VERSION ""

NS_ :

BS_:

BU_: VDCU_V CDCU VDR_TBOX ADCU VIU_B VIU_C VDCU_M EPB EPS_M EPS_S EBS FCS CMS_R CMS_B ECAS EGSM MTCU

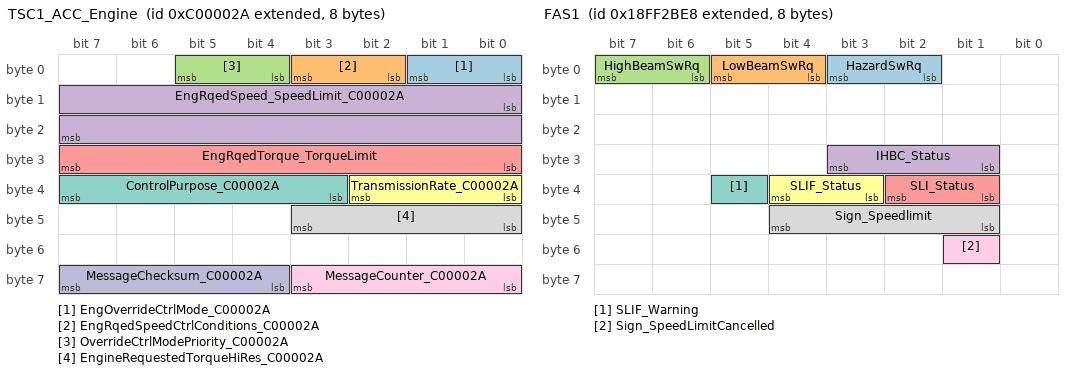
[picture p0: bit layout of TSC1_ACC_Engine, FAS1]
BO_ 2348810282 TSC1_ACC_Engine: 8 ADCU
 SG_ EngOverrideCtrlMode_C00002A : 0|2@1+ (1,0) [0|3] "" VDCU_V
 SG_ EngRqedSpeedCtrlConditions_C00002A : 2|2@1+ (1,0) [0|3] "" VDCU_V
 SG_ OverrideCtrlModePriority_C00002A : 4|2@1+ (1,0) [0|3] "" VDCU_V
 SG_ EngRqedSpeed_SpeedLimit_C00002A : 8|16@1+ (0.125,0) [0|8031.875] "rpm" VDCU_V
 SG_ EngRqedTorque_TorqueLimit : 24|8@1+ (1,-125) [-125|125] "%" VDCU_V
 SG_ TransmissionRate_C00002A : 32|3@1+ (1,0) [0|7] "" VDCU_V
 SG_ ControlPurpose_C00002A : 35|5@1+ (1,0) [0|31] "" VDCU_V
 SG_ EngineRequestedTorqueHiRes_C00002A : 40|4@1+ (0.125,0) [0|0.875] "%" VDCU_V
 SG_ MessageCounter_C00002A : 56|4@1+ (1,0) [0|15] "" VDCU_V
 SG_ MessageChecksum_C00002A : 60|4@1+ (1,0) [0|15] "" VDCU_V

BO_ 2349465642 CCVS2_ACC: 8 ADCU
 SG_ CruiseControlPauseCommand : 4|2@1+ (1,0) [0|3] "" VDCU_V

BO_ 2566859752 FAS1: 8 FCS
 SG_ HazardSwRq : 2|2@1+ (1,0) [0|3] "" VDCU_V
 SG_ LowBeamSwRq : 4|2@1+ (1,0) [0|3] "" VDCU_V
 SG_ HighBeamSwRq : 6|2@1+ (1,0) [0|3] "" VDCU_V
 SG_ IHBC_Status : 25|3@1+ (1,0) [0|7] "" VDCU_V
 SG_ SLI_Status : 33|2@1+ (1,0) [0|3] "" VDCU_V
 SG_ SLIF_Status : 35|2@1+ (1,0) [0|3] "" VDCU_V
 SG_ SLIF_Warning : 37|1@1+ (1,0) [0|1] "" VDCU_V
 SG_ Sign_Speedlimit : 41|4@1+ (1,0) [0|15] "" VDCU_V
 SG_ Sign_SpeedLimitCancelled : 49|1@1+ (1,0) [0|1] "" VDCU_V

BO_ 2565865808 EBC1_EPB: 8 EPB
 SG_ HaltBrakeSwitchEPB : 58|2@1+ (1,0) [0|3] "" VDCU_V

BO_ 2566787664 EPBS1_EPB: 8 EPB
 SG_ EPB_ParkBraStatus : 0|2@1+ (1,0) [0|3] "" VDCU_V
 SG_ AH_ParkActive : 2|2@1+ (1,0) [0|3] "" VDCU_V
 SG_ AH_BraStatus : 4|2@1+ (1,0) [0|3] "" VDCU_V
 SG_ EPB_WorkMode : 6|2@1+ (1,0) [0|3] "" VDCU_V
 SG_ ErrCode : 8|8@1+ (1,0) [0|255] "" VDCU_V
 SG_ ChildLockActive : 16|2@1+ (1,0) [0|3] "" VDCU_V
 SG_ LowPreRelParkLimit : 18|2@1+ (1,0) [0|3] "" VDCU_V
 SG_ TrailerCnctChck : 20|2@1+ (1,0) [0|3] "" VDCU_V
 SG_ ResponsePriority : 22|2@1+ (1,0) [0|3] "" VDCU_V
 SG_ IdepedtBraOly : 24|2@1+ (1,0) [0|3] "" VDCU_V
 SG_ PrakBraForcTest : 26|2@1+ (1,0) [0|3] "" VDCU_V
 SG_ DriveHillStatus : 28|2@1+ (1,0) [0|3] "" VDCU_V
 SG_ EPB_BraSwitch : 30|2@1+ (1,0) [0|3] "" VDCU_V
 SG_ ParkBtSwitch : 32|2@1+ (1,0) [0|3] "" VDCU_V
 SG_ RelsBtSwitch : 34|2@1+ (1,0) [0|3] "" VDCU_V
 SG_ AHBtSwitch : 36|2@1+ (1,0) [0|3] "" VDCU_V
 SG_ IdepedtBtSwitch : 38|2@1+ (1,0) [0|3] "" VDCU_V
 SG_ ForcTestBtSwitch : 40|2@1+ (1,0) [0|3] "" VDCU_V
 SG_ SysStatus : 42|2@1+ (1,0) [0|3] "" VDCU_V
 SG_ WarmingStatus : 44|2@1+ (1,0) [0|3] "" VDCU_V
 SG_ RollerTestBenchMode : 46|1@1+ (1,0) [0|1] "" VDCU_V
 SG_ ParkBraPres : 48|8@1+ (4.9,-122.5) [-122.5|1102.5] "Kpa" VDCU_V
 SG_ PTposition : 56|8@1+ (1,-125) [-125|125] "%" VDCU_V

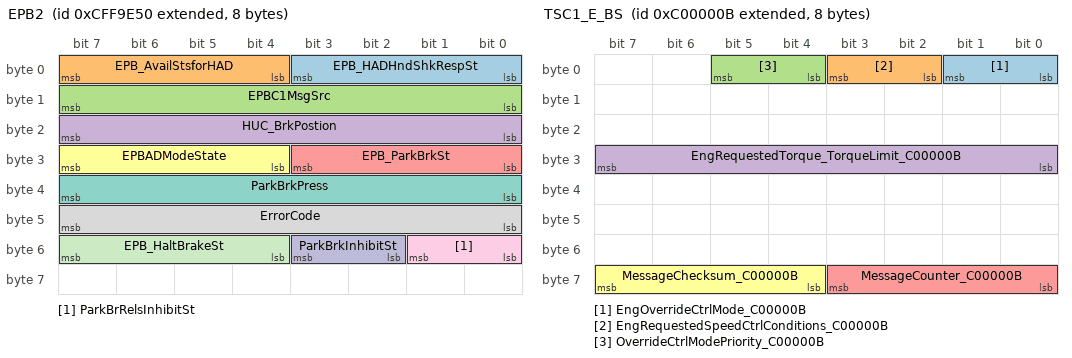
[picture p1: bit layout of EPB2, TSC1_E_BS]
BO_ 2365562448 EPB2: 8 EPB
 SG_ EPB_HADHndShkRespSt : 0|4@1+ (1,0) [0|15] "" VDCU_V
 SG_ EPB_AvailStsforHAD : 4|4@1+ (1,0) [0|15] "" VDCU_V
 SG_ EPBC1MsgSrc : 8|8@1+ (1,0) [0|255] "" VDCU_V
 SG_ HUC_BrkPostion : 16|8@1+ (1,0) [0|255] "" VDCU_V
 SG_ EPB_ParkBrkSt : 24|4@1+ (1,0) [0|16] "" VDCU_V
 SG_ EPBADModeState : 28|4@1+ (1,0) [0|15] "" VDCU_V
 SG_ ParkBrkPress : 32|8@1+ (4,0) [0|255] "" VDCU_V
 SG_ ErrorCode : 40|8@1+ (1,0) [0|255] "" VDCU_V
 SG_ ParkBrRelsInhibitSt : 48|2@1+ (1,0) [0|3] "" VDCU_V
 SG_ ParkBrkInhibitSt : 50|2@1+ (1,0) [0|3] "" VDCU_V
 SG_ EPB_HaltBrakeSt : 52|4@1+ (1,0) [0|15] "" VDCU_V

BO_ 2566847056 B1_EPB: 8 EPB
 SG_ BrakeAppPress : 0|8@1+ (4,0) [0|1000] "Kpa" VDCU_V

BO_ 2566911764 PropB_F7_S: 8 EPS_S
 SG_ DriverInterventionStatus_S : 0|3@1+ (1,1) [1|7] "0" VDCU_V

BO_ 2566897256 WPTC1: 8 VDCU_V
 SG_ WPTC1_InletTemp : 0|8@1+ (1,-40) [-40|210] "℃" Vector__XXX
 SG_ WPTC1_OutletTemp : 8|8@1+ (1,-40) [-40|210] "℃" Vector__XXX
 SG_ WPTC1_CtrlSysTemp : 16|8@1+ (1,-40) [-40|210] "℃" Vector__XXX
 SG_ WPTC1_HVVoltage : 24|8@1+ (5,0) [0|1000] "V" Vector__XXX
 SG_ WPTC1_HeaterPower : 32|8@1+ (100,0) [0|25500] "W" VDR_TBOX
 SG_ WPTC1_WorkingSts : 40|1@1+ (1,0) [0|1] "" Vector__XXX
 SG_ WPTC1_FaultLevel : 41|2@1+ (1,0) [0|3] "" Vector__XXX
 SG_ WPTC1_HVOverVoltage : 43|1@1+ (1,0) [0|1] "" Vector__XXX
 SG_ WPTC1_HVUnderVoltage : 44|1@1+ (1,0) [0|1] "" Vector__XXX
 SG_ WPTC1_LVOverVoltage : 45|1@1+ (1,0) [0|1] "" Vector__XXX
 SG_ WPTC1_LVUnderVoltage : 46|1@1+ (1,0) [0|1] "" Vector__XXX
 SG_ WPTC1_OpenCircuit : 47|1@1+ (1,0) [0|1] "" Vector__XXX
 SG_ WPTC1_OutletOverheating : 48|1@1+ (1,0) [0|1] "" Vector__XXX
 SG_ WPTC1_IGBTOverheating : 49|1@1+ (1,0) [0|1] "" Vector__XXX
 SG_ WPTC1_ComLoss : 50|1@1+ (1,0) [0|1] "" Vector__XXX
 SG_ WPTC1_IGBTShortCircuit : 51|1@1+ (1,0) [0|1] "" Vector__XXX
 SG_ WPTC1_LowFlowrate : 52|1@1+ (1,0) [0|1] "" Vector__XXX
 SG_ WPTC1_OvercurrentFault : 53|1@1+ (1,0) [0|1] "" Vector__XXX
 SG_ WPTC1_PTCShortCircuit : 54|1@1+ (1,0) [0|1] "" Vector__XXX
 SG_ WPTC1_NTCFault : 55|1@1+ (1,0) [0|1] "" Vector__XXX
 SG_ WPTC1_SoftwareVersion : 56|8@1+ (1,0) [0|255] "" Vector__XXX

BO_ 2566897283 WPTC2: 8 VDCU_V
 SG_ WPTC2_InletTemp : 0|8@1+ (1,-40) [-40|210] "℃" Vector__XXX
 SG_ WPTC2_OutletTemp : 8|8@1+ (1,-40) [-40|210] "℃" Vector__XXX
 SG_ WPTC2_CtrlSysTemp : 16|8@1+ (1,-40) [-40|210] "℃" Vector__XXX
 SG_ WPTC2_HVVoltage : 24|8@1+ (5,0) [0|1000] "V" Vector__XXX
 SG_ WPTC2_HeaterPower : 32|8@1+ (100,0) [0|25500] "W" VDR_TBOX
 SG_ WPTC2_WorkingSts : 40|1@1+ (1,0) [0|1] "" Vector__XXX
 SG_ WPTC2_FaultLevel : 41|2@1+ (1,0) [0|3] "" Vector__XXX
 SG_ WPTC2_HVOverVoltage : 43|1@1+ (1,0) [0|1] "" Vector__XXX
 SG_ WPTC2_HVUnderVoltage : 44|1@1+ (1,0) [0|1] "" Vector__XXX
 SG_ WPTC2_LVOverVoltage : 45|1@1+ (1,0) [0|1] "" Vector__XXX
 SG_ WPTC2_LVUnderVoltage : 46|1@1+ (1,0) [0|1] "" Vector__XXX
 SG_ WPTC2_OpenCircuit : 47|1@1+ (1,0) [0|1] "" Vector__XXX
 SG_ WPTC2_OutletOverheating : 48|1@1+ (1,0) [0|1] "" Vector__XXX
 SG_ WPTC2_IGBTOverheating : 49|1@1+ (1,0) [0|1] "" Vector__XXX
 SG_ WPTC2_ComLoss : 50|1@1+ (1,0) [0|1] "" Vector__XXX
 SG_ WPTC2_IGBTShortCircuit : 51|1@1+ (1,0) [0|1] "" Vector__XXX
 SG_ WPTC2_LowFlowrate : 52|1@1+ (1,0) [0|1] "" Vector__XXX
 SG_ WPTC2_OvercurrentFault : 53|1@1+ (1,0) [0|1] "" Vector__XXX
 SG_ WPTC2_PTCShortCircuit : 54|1@1+ (1,0) [0|1] "" Vector__XXX
 SG_ WPTC2_NTCFault : 55|1@1+ (1,0) [0|1] "" Vector__XXX
 SG_ WPTC2_SoftwareVersion : 56|8@1+ (1,0) [0|255] "" Vector__XXX

BO_ 2566897284 WPTC3: 8 VDCU_V
 SG_ WPTC3_InletTemp : 0|8@1+ (1,-40) [-40|210] "℃" Vector__XXX
 SG_ WPTC3_OutletTemp : 8|8@1+ (1,-40) [-40|210] "℃" Vector__XXX
 SG_ WPTC3_CtrlSysTemp : 16|8@1+ (1,-40) [-40|210] "℃" Vector__XXX
 SG_ WPTC3_HVVoltage : 24|8@1+ (5,0) [0|1000] "V" Vector__XXX
 SG_ WPTC3_HeaterPower : 32|8@1+ (100,0) [0|25500] "W" VDR_TBOX
 SG_ WPTC3_WorkingSts : 40|1@1+ (1,0) [0|1] "" Vector__XXX
 SG_ WPTC3_FaultLevel : 41|2@1+ (1,0) [0|3] "" Vector__XXX
 SG_ WPTC3_HVOverVoltage : 43|1@1+ (1,0) [0|1] "" Vector__XXX
 SG_ WPTC3_HVUnderVoltage : 44|1@1+ (1,0) [0|1] "" Vector__XXX
 SG_ WPTC3_LVOverVoltage : 45|1@1+ (1,0) [0|1] "" Vector__XXX
 SG_ WPTC3_LVUnderVoltage : 46|1@1+ (1,0) [0|1] "" Vector__XXX
 SG_ WPTC3_OpenCircuit : 47|1@1+ (1,0) [0|1] "" Vector__XXX
 SG_ WPTC3_OutletOverheating : 48|1@1+ (1,0) [0|1] "" Vector__XXX
 SG_ WPTC3_IGBTOverheating : 49|1@1+ (1,0) [0|1] "" Vector__XXX
 SG_ WPTC3_ComLoss : 50|1@1+ (1,0) [0|1] "" Vector__XXX
 SG_ WPTC3_IGBTShortCircuit : 51|1@1+ (1,0) [0|1] "" Vector__XXX
 SG_ WPTC3_LowFlowrate : 52|1@1+ (1,0) [0|1] "" Vector__XXX
 SG_ WPTC3_OvercurrentFault : 53|1@1+ (1,0) [0|1] "" Vector__XXX
 SG_ WPTC3_PTCShortCircuit : 54|1@1+ (1,0) [0|1] "" Vector__XXX
 SG_ WPTC3_NTCFault : 55|1@1+ (1,0) [0|1] "" Vector__XXX
 SG_ WPTC3_SoftwareVersion : 56|8@1+ (1,0) [0|255] "" Vector__XXX

BO_ 2348810251 TSC1_E_BS: 8 EBS
 SG_ EngOverrideCtrlMode_C00000B : 0|2@1+ (1,0) [0|3] "" VDCU_V
 SG_ EngRequestedSpeedCtrlConditions_C00000B : 2|2@1+ (1,0) [0|3] "" VDCU_V
 SG_ OverrideCtrlModePriority_C00000B : 4|2@1+ (1,0) [0|3] "" VDCU_V
 SG_ EngRequestedTorque_TorqueLimit_C00000B : 24|8@1+ (1,-125) [-125|125] "%" VDCU_V
 SG_ MessageCounter_C00000B : 56|4@1+ (1,0) [0|15] "" VDCU_V
 SG_ MessageChecksum_C00000B : 60|4@1+ (1,0) [0|15] "" VDCU_V

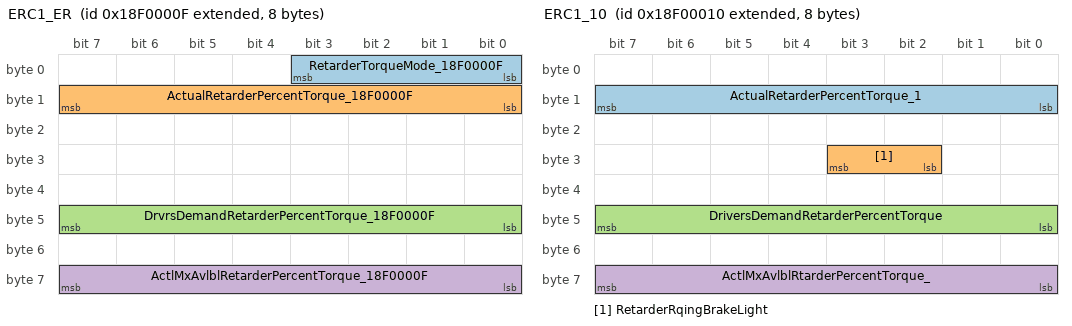
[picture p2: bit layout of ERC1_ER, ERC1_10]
BO_ 2565865487 ERC1_ER: 8 VDCU_V
 SG_ RetarderTorqueMode_18F0000F : 0|4@1+ (1,0) [0|15] "" VDR_TBOX,EBS
 SG_ ActualRetarderPercentTorque_18F0000F : 8|8@1+ (1,-125) [-125|125] "%" VDR_TBOX,EBS
 SG_ DrvrsDemandRetarderPercentTorque_18F0000F : 40|8@1+ (1,-125) [-125|0] "%" VDR_TBOX,EBS
 SG_ ActlMxAvlblRetarderPercentTorque_18F0000F : 56|8@1+ (1,-125) [-125|125] "%" VDR_TBOX,EBS

BO_ 2566840591 RC_ER: 19 VDCU_V
 SG_ ReferenceRetarderTorque_18FEE10F : 128|16@1+ (1,0) [0|64255] "Nm" VDR_TBOX,EBS

BO_ 2565865488 ERC1_10: 8 VDCU_V
 SG_ ActualRetarderPercentTorque_1 : 8|8@1+ (1,-125) [-125|125] "%" VDR_TBOX,ADCU,EPB,EPS_M,EPS_S
 SG_ RetarderRqingBrakeLight : 26|2@1+ (1,0) [0|3] "" VDR_TBOX,ADCU,EPB,EPS_M,EPS_S
 SG_ DriversDemandRetarderPercentTorque : 40|8@1+ (1,-125) [-125|125] "%" VDR_TBOX,ADCU,EPB,EPS_M,EPS_S
 SG_ ActlMxAvlblRtarderPercentTorque_ : 56|8@1+ (1,-125) [-125|125] "%" VDR_TBOX,ADCU,EPB,EPS_M,EPS_S

BO_ 2566840592 RC1_10: 19 VDCU_V
 SG_ RetarderType_10 : 0|4@1+ (1,0) [0|15] "" VDR_TBOX,ADCU,EBS
 SG_ RetarderLocation_10 : 4|4@1+ (1,0) [0|15] "" VDR_TBOX,ADCU,EBS
 SG_ ReferenceRetarderTorque_10 : 128|16@1+ (1,0) [0|64255] "Nm" VDR_TBOX,ADCU,EBS

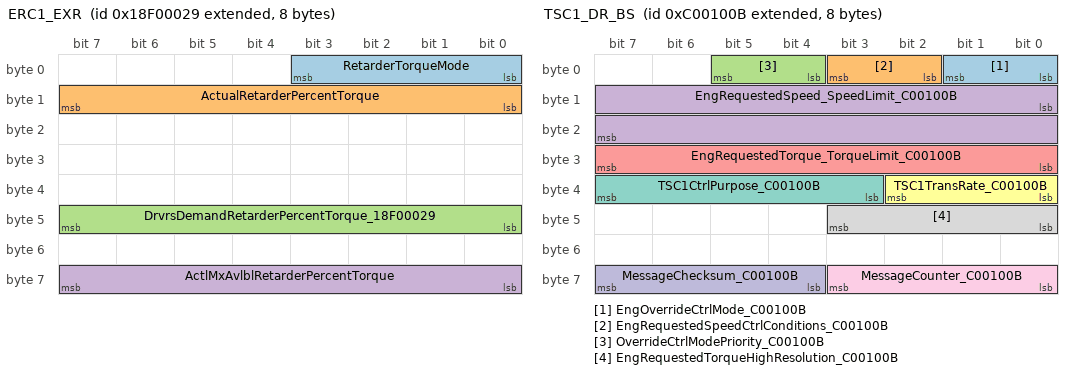
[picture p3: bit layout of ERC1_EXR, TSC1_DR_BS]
BO_ 2565865513 ERC1_EXR: 8 VDCU_V
 SG_ RetarderTorqueMode : 0|4@1+ (1,0) [0|15] "" VDR_TBOX,EBS
 SG_ ActualRetarderPercentTorque : 8|8@1+ (1,-125) [-125|125] "%" VDR_TBOX,EBS
 SG_ DrvrsDemandRetarderPercentTorque_18F00029 : 40|8@1+ (1,-125) [-125|0] "%" VDR_TBOX,EBS
 SG_ ActlMxAvlblRetarderPercentTorque : 56|8@1+ (1,-125) [-125|125] "%" VDR_TBOX,EBS

BO_ 2566840617 RC_EXR: 19 VDCU_V
 SG_ ReferenceRetarderTorque : 128|16@1+ (1,0) [0|64255] "Nm" VDR_TBOX,EBS

BO_ 2348814091 TSC1_ER_BS: 10 EBS
 SG_ EngOverrideCtrlMode_C000F0B : 0|2@1+ (1,0) [0|3] "" VDCU_V
 SG_ OverrideCtrlModePriority_C000F0B : 4|2@1+ (1,0) [0|3] "" VDCU_V
 SG_ EngRequestedTorque_TorqueLimit_C000F0B : 24|8@1+ (1,-125) [-125|125] "%" VDCU_V
 SG_ MessageCounterJ1939_C000F0B : 56|4@1+ (1,0) [0|15] "" VDCU_V
 SG_ MessageChecksumJ1939_C000F0B : 60|4@1+ (1,0) [0|15] "" VDCU_V
 SG_ MessageChecksumAR2_C000F0B : 64|8@1+ (1,0) [0|255] "" VDCU_V
 SG_ MessageCounter_C000F0B : 72|4@1+ (1,0) [0|15] "" VDCU_V

BO_ 2348814347 TSC1_DR_BS: 8 EBS
 SG_ EngOverrideCtrlMode_C00100B : 0|2@1+ (1,0) [0|3] "" VDCU_V
 SG_ EngRequestedSpeedCtrlConditions_C00100B : 2|2@1+ (1,0) [0|3] "" VDCU_V
 SG_ OverrideCtrlModePriority_C00100B : 4|2@1+ (1,0) [0|3] "" VDCU_V
 SG_ EngRequestedSpeed_SpeedLimit_C00100B : 8|16@1+ (0.125,0) [0|8031.875] "rpm" VDCU_V
 SG_ EngRequestedTorque_TorqueLimit_C00100B : 24|8@1+ (1,-125) [-125|125] "%" VDCU_V
 SG_ TSC1TransRate_C00100B : 32|3@1+ (1,0) [0|7] "" VDCU_V
 SG_ TSC1CtrlPurpose_C00100B : 35|5@1+ (1,0) [0|31] "" VDCU_V
 SG_ EngRequestedTorqueHighResolution_C00100B : 40|4@1+ (0.125,0) [0|0.875] "%" VDCU_V
 SG_ MessageCounter_C00100B : 56|4@1+ (1,0) [0|15] "" VDCU_V
 SG_ MessageChecksum_C00100B : 60|4@1+ (1,0) [0|15] "" VDCU_V

BO_ 2348820747 TSC1_EXR_BS: 10 EBS
 SG_ EngOverrideCtrlMode : 0|2@1+ (1,0) [0|3] "" VDCU_V
 SG_ OverrideCtrlModePriority : 4|2@1+ (1,0) [0|3] "" VDCU_V
 SG_ EngRequestedTorque_TorqueLimit : 24|8@1+ (1,-125) [-125|125] "%" VDCU_V
 SG_ MessageCounterJ1939_C00290B : 56|4@1+ (1,0) [0|15] "" VDCU_V
 SG_ MessageChecksumJ1939_C00290B : 60|4@1+ (1,0) [0|15] "" VDCU_V
 SG_ MessageChecksumAR2_C00290B : 64|8@1+ (1,0) [0|255] "" VDCU_V
 SG_ MessageCounter_C00290B : 72|4@1+ (1,0) [0|15] "" VDCU_V

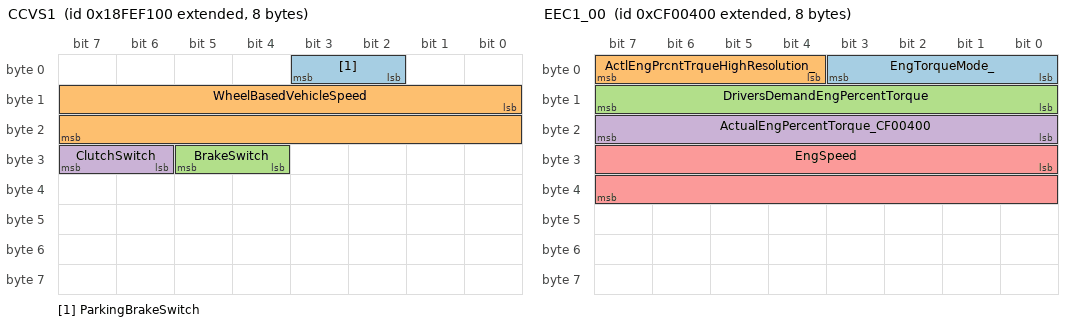
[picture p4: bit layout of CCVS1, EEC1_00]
BO_ 2566844672 CCVS1: 8 VDCU_V
 SG_ ParkingBrakeSwitch : 2|2@1+ (1,0) [0|3] "" CDCU,VDR_TBOX,ADCU,EPB,FCS,EBS,ECAS
 SG_ WheelBasedVehicleSpeed : 8|16@1+ (0.00390625,0) [0|250.996] "km/h" VDR_TBOX,ADCU,EPB,EBS,ECAS
 SG_ BrakeSwitch : 28|2@1+ (1,0) [0|3] "" VDR_TBOX,ADCU,EPB,ECAS
 SG_ ClutchSwitch : 30|2@1+ (1,0) [0|3] "" VDR_TBOX,ADCU,EPB

BO_ 2566841088 EC1_00: 39 VDCU_V
 SG_ EngReferenceTorque_ : 152|16@1+ (1,0) [0|64255] "N?m" ADCU,EBS

BO_ 2364539904 EEC1_00: 8 VDCU_V
 SG_ EngTorqueMode_ : 0|4@1+ (1,0) [0|15] "%" VDR_TBOX,ADCU,EPB,FCS,EPS_M,EPS_S
 SG_ ActlEngPrcntTrqueHighResolution_ : 4|4@1+ (0.125,0) [0|0.875] "%" VDR_TBOX,ADCU,EPB,FCS,EBS,EPS_M,EPS_S
 SG_ DriversDemandEngPercentTorque : 8|8@1+ (1,-125) [-125|125] "%" VIU_C,VDR_TBOX,ADCU,EPB,FCS,EBS,EPS_M,EPS_S
 SG_ ActualEngPercentTorque_CF00400 : 16|8@1+ (1,-125) [-125|125] "%" VIU_C,VDR_TBOX,ADCU,EPB,FCS,EBS,EPS_M,EPS_S
 SG_ EngSpeed : 24|16@1+ (0.125,0) [0|8031.875] "rpm" VIU_C,VDR_TBOX,ADCU,EPB,FCS,EBS,EPS_M,EPS_S,ECAS

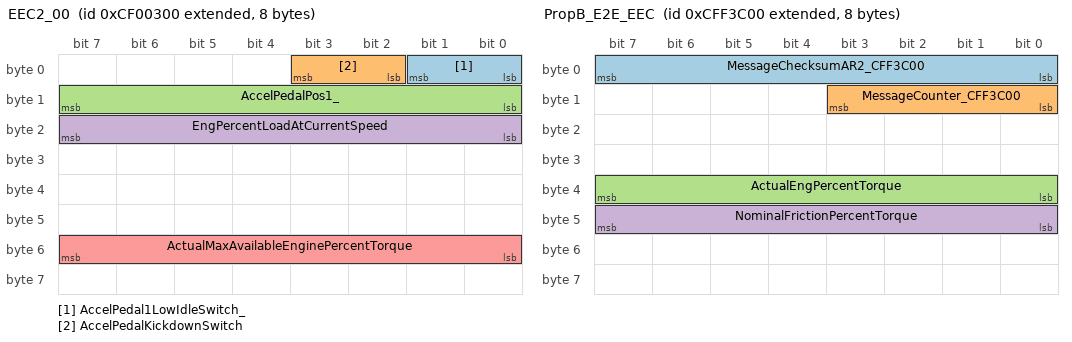
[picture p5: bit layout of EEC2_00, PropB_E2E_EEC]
BO_ 2364539648 EEC2_00: 8 VDCU_V
 SG_ AccelPedal1LowIdleSwitch_ : 0|2@1+ (1,0) [0|3] "" VDR_TBOX,ADCU,EPB,FCS,EPS_M,EPS_S
 SG_ AccelPedalKickdownSwitch : 2|2@1+ (1,0) [0|3] "" VDR_TBOX,ADCU,EPB,FCS,EPS_M,EPS_S
 SG_ AccelPedalPos1_ : 8|8@1+ (0.4,0) [0|100] "%" VDR_TBOX,ADCU,EPB,FCS,EBS,EPS_M,EPS_S
 SG_ EngPercentLoadAtCurrentSpeed : 16|8@1+ (1,0) [0|250] "%" VIU_C,VDR_TBOX,ADCU,EPB,FCS,EBS,EPS_M,EPS_S
 SG_ ActualMaxAvailableEnginePercentTorque : 48|8@1+ (0.4,0) [0|100] "%" VDR_TBOX,ADCU,EPB,FCS,EPS_M,EPS_S

BO_ 2566840064 EEC3_00: 8 VDCU_V
 SG_ NominalFrictionPercentTorque_00 : 0|8@1+ (1,-125) [-125|125] "%" VDR_TBOX,ADCU,EPB,EPS_M,EPS_S
 SG_ Estimated_Engine_Parasitic_Losses_Percent_Torque : 32|8@1+ (1,-125) [0|125] "%" VDR_TBOX

BO_ 2566843904 ET1: 8 VDCU_V
 SG_ EngCoolantTemp : 0|8@1+ (1,-40) [-40|210] "deg^C" EBS

BO_ 2566845952 IC1: 8 VDCU_V
 SG_ EngIntakeManifold1Press : 8|8@1+ (2,0) [0|500] "kPa" EBS

BO_ 2365537280 PropB_E2E_EEC: 8 VDCU_V
 SG_ MessageChecksumAR2_CFF3C00 : 0|8@1+ (1,0) [0|255] "" EBS
 SG_ MessageCounter_CFF3C00 : 8|4@1+ (1,0) [0|15] "" EBS
 SG_ ActualEngPercentTorque : 32|8@1+ (1,-125) [-125|130] "%" EBS
 SG_ NominalFrictionPercentTorque : 40|8@1+ (1,-125) [-125|125] "%" EBS

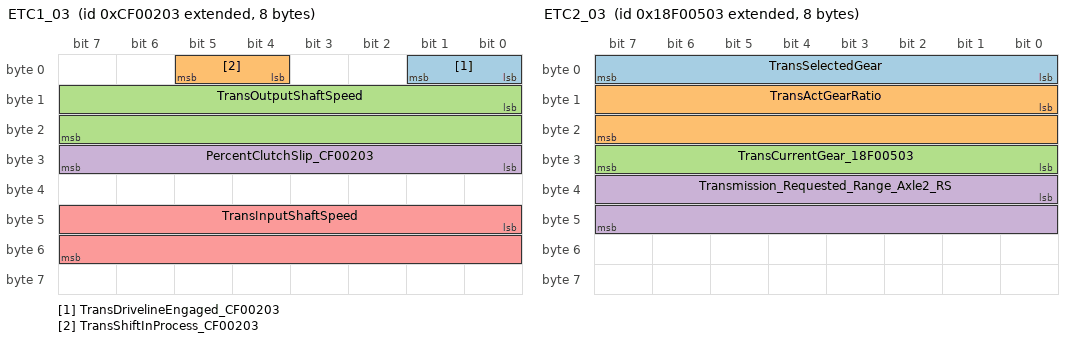
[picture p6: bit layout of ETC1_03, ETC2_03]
BO_ 2364539395 ETC1_03: 8 VDCU_V
 SG_ TransDrivelineEngaged_CF00203 : 0|2@1+ (1,0) [0|3] "" VDR_TBOX,ADCU,EPB
 SG_ TransShiftInProcess_CF00203 : 4|2@1+ (1,0) [0|3] "" VDR_TBOX,ADCU,EPB,EBS
 SG_ TransOutputShaftSpeed : 8|16@1+ (0.125,0) [0|8031.875] "rpm" VDR_TBOX,ADCU,EPB,EPS_M,EPS_S
 SG_ PercentClutchSlip_CF00203 : 24|8@1+ (0.4,0) [0|100] "%" VDR_TBOX,ADCU,EPB
 SG_ TransInputShaftSpeed : 40|16@1+ (0.125,0) [0|8031.875] "rpm" VDR_TBOX,ADCU,EPB

BO_ 2565866755 ETC2_03: 8 VDCU_V
 SG_ TransSelectedGear : 0|8@1+ (1,-125) [-125|125] "" CDCU,VDR_TBOX,ADCU,EPB,EBS,EPS_M,EPS_S
 SG_ TransActGearRatio : 8|16@1+ (0.001,0) [0|64.225] "" VDR_TBOX,ADCU,EPB,EBS,EPS_M,EPS_S
 SG_ TransCurrentGear_18F00503 : 24|8@1+ (1,-125) [-125|125] "" CDCU,VDR_TBOX,CMS_R,CMS_B,ADCU,EPB,EBS,EPS_M,EPS_S
 SG_ Transmission_Requested_Range_Axle2_RS : 32|16@1+ (1,0) [0|255] "ASC" Vector__XXX

BO_ 2566801923 ETC7_03: 8 VDCU_V
 SG_ TransReadyForBrakeRelease_18FE4A03 : 8|2@1+ (1,0) [0|3] "" VDR_TBOX,ADCU,EPB,EBS,EPS_M,EPS_S

BO_ 2364541955 ETC8: 8 VDCU_V
 SG_ TransTorqueConverterRatio : 0|16@1+ (0.001,0) [0|64.255] "" EBS

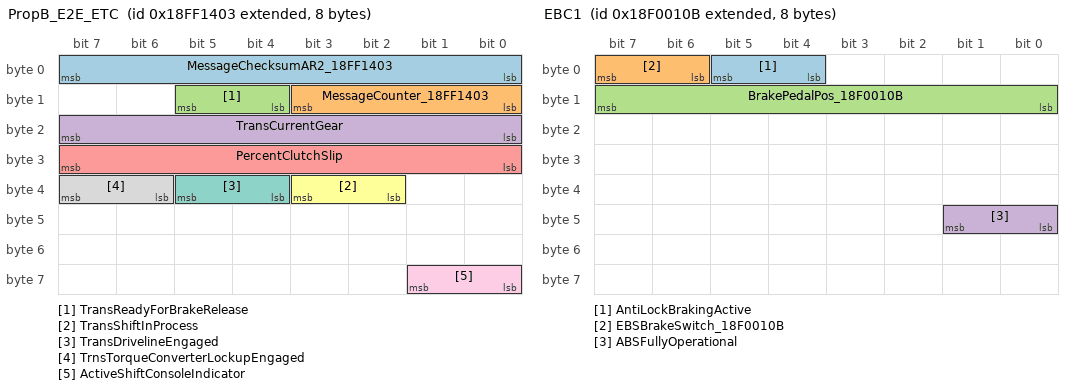
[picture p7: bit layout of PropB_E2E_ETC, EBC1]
BO_ 2566853635 PropB_E2E_ETC: 8 VDCU_V
 SG_ MessageChecksumAR2_18FF1403 : 0|8@1+ (1,0) [0|255] "" EBS
 SG_ MessageCounter_18FF1403 : 8|4@1+ (1,0) [0|15] "" EBS
 SG_ TransReadyForBrakeRelease : 12|2@1+ (1,0) [0|3] "" EBS
 SG_ TransCurrentGear : 16|8@1+ (1,-125) [-125|125] "" EBS
 SG_ PercentClutchSlip : 24|8@1+ (0.4,0) [0|100] "%" EBS
 SG_ TransShiftInProcess : 34|2@1+ (1,0) [0|3] "" EBS
 SG_ TransDrivelineEngaged : 36|2@1+ (1,0) [0|3] "" EBS
 SG_ TrnsTorqueConverterLockupEngaged : 38|2@1+ (1,0) [0|3] "" EBS
 SG_ ActiveShiftConsoleIndicator : 56|2@1+ (1,0) [0|3] "" EBS

BO_ 2565865739 EBC1: 8 EBS
 SG_ AntiLockBrakingActive : 4|2@1+ (1,0) [0|3] "" VDCU_V
 SG_ EBSBrakeSwitch_18F0010B : 6|2@1+ (1,0) [0|3] "" VDCU_V
 SG_ BrakePedalPos_18F0010B : 8|8@1+ (0.4,0) [0|100] "" VDCU_V
 SG_ ABSFullyOperational : 40|2@1+ (1,0) [0|3] "" VDCU_V

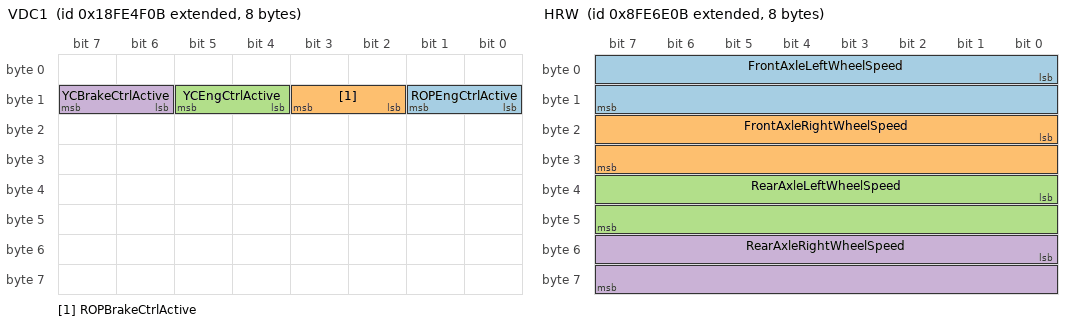
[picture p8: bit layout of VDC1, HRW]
BO_ 2566803211 VDC1: 8 EBS
 SG_ ROPEngCtrlActive : 8|2@1+ (1,0) [0|3] "" VDCU_V
 SG_ ROPBrakeCtrlActive : 10|2@1+ (1,0) [0|3] "" VDCU_V
 SG_ YCEngCtrlActive : 12|2@1+ (1,0) [0|3] "" VDCU_V
 SG_ YCBrakeCtrlActive : 14|2@1+ (1,0) [0|3] "" VDCU_V

BO_ 2298375691 HRW: 8 EBS
 SG_ FrontAxleLeftWheelSpeed : 0|16@1+ (0.00390625,0) [0|255.99609375] "" VDCU_V
 SG_ FrontAxleRightWheelSpeed : 16|16@1+ (0.00390625,0) [0|255.99609375] "" VDCU_V
 SG_ RearAxleLeftWheelSpeed : 32|16@1+ (0.00390625,0) [0|255.99609375] "" VDCU_V
 SG_ RearAxleRightWheelSpeed : 48|16@1+ (0.00390625,0) [0|255.99609375] "" VDCU_V

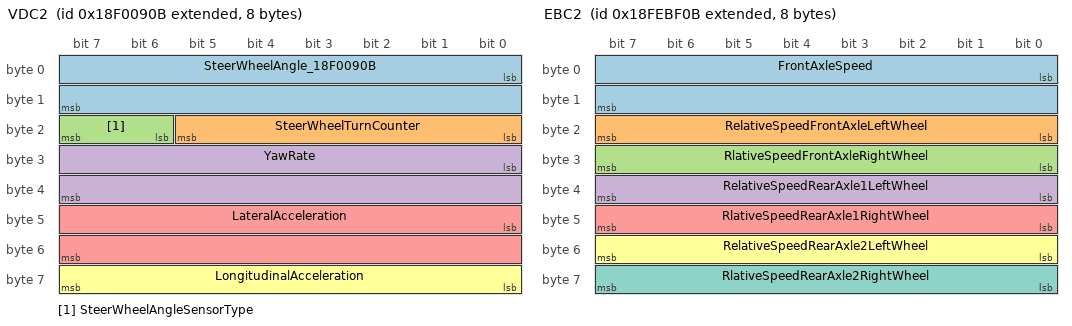
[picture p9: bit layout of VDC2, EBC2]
BO_ 2565867787 VDC2: 8 EBS
 SG_ SteerWheelAngle_18F0090B : 0|16@1+ (9.765625E-4,-31.374) [-31.374|32.625056205] "" VDCU_V
 SG_ SteerWheelTurnCounter : 16|6@1+ (1,-32) [-32|29] "" VDCU_V
 SG_ SteerWheelAngleSensorType : 22|2@1+ (1,0) [0|3] "" VDCU_V
 SG_ YawRate : 24|16@1+ (1.220703125E-4,-3.92) [-3.92|4.07985745] "" VDCU_V
 SG_ LateralAcceleration : 40|16@1+ (4.8828125E-4,-15.687) [-15.687|16.312495335] "" VDCU_V
 SG_ LongitudinalAcceleration : 56|8@1+ (0.1,-12.5) [-12.5|12.5] "" VDCU_V

BO_ 2566831883 EBC2: 8 EBS
 SG_ FrontAxleSpeed : 0|16@1+ (0.00390625,0) [0|255.99609375] "" VDCU_V
 SG_ RelativeSpeedFrontAxleLeftWheel : 16|8@1+ (0.0625,-7.8125) [-7.8125|7.8125] "" VDCU_V
 SG_ RlativeSpeedFrontAxleRightWheel : 24|8@1+ (0.0625,-7.8125) [-7.8125|7.8125] "" VDCU_V
 SG_ RelativeSpeedRearAxle1LeftWheel : 32|8@1+ (0.0625,-7.8125) [-7.8125|7.8125] "" VDCU_V
 SG_ RlativeSpeedRearAxle1RightWheel : 40|8@1+ (0.0625,-7.8125) [-7.8125|7.8125] "" VDCU_V
 SG_ RelativeSpeedRearAxle2LeftWheel : 48|8@1+ (0.0625,-7.8125) [-7.8125|7.8125] "" VDCU_V
 SG_ RlativeSpeedRearAxle2RightWheel : 56|8@1+ (0.0625,-7.8125) [-7.8125|7.8125] "" VDCU_V

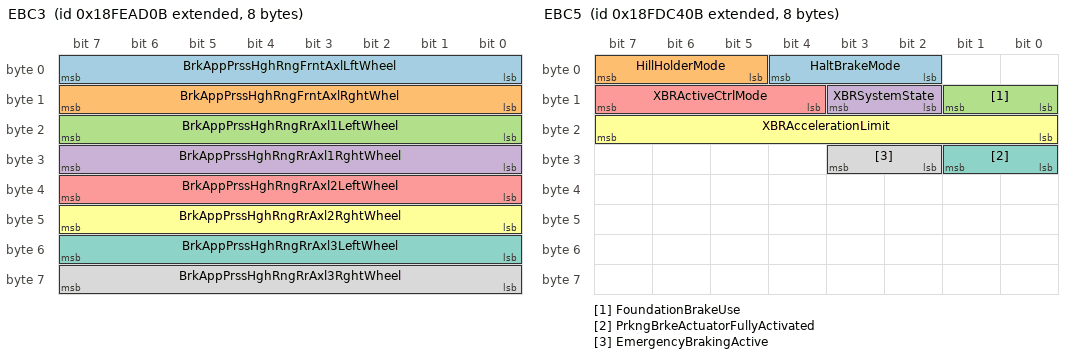
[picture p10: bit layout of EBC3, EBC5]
BO_ 2566827275 EBC3: 8 EBS
 SG_ BrkAppPrssHghRngFrntAxlLftWheel : 0|8@1+ (5,0) [0|1250] "" VDCU_V
 SG_ BrkAppPrssHghRngFrntAxlRghtWhel : 8|8@1+ (5,0) [0|1250] "" VDCU_V
 SG_ BrkAppPrssHghRngRrAxl1LeftWheel : 16|8@1+ (5,0) [0|1250] "" VDCU_V
 SG_ BrkAppPrssHghRngRrAxl1RghtWheel : 24|8@1+ (5,0) [0|1250] "" VDCU_V
 SG_ BrkAppPrssHghRngRrAxl2LeftWheel : 32|8@1+ (5,0) [0|1250] "" VDCU_V
 SG_ BrkAppPrssHghRngRrAxl2RghtWheel : 40|8@1+ (5,0) [0|1250] "" VDCU_V
 SG_ BrkAppPrssHghRngRrAxl3LeftWheel : 48|8@1+ (5,0) [0|1250] "" VDCU_V
 SG_ BrkAppPrssHghRngRrAxl3RghtWheel : 56|8@1+ (5,0) [0|1250] "" VDCU_V

BO_ 2566767627 EBC5: 8 EBS
 SG_ HaltBrakeMode : 2|3@1+ (1,0) [0|7] "" VDCU_V
 SG_ HillHolderMode : 5|3@1+ (1,0) [0|7] "" VDCU_V
 SG_ FoundationBrakeUse : 8|2@1+ (1,0) [0|3] "" VDCU_V
 SG_ XBRSystemState : 10|2@1+ (1,0) [0|3] "" VDCU_V
 SG_ XBRActiveCtrlMode : 12|4@1+ (1,0) [0|15] "" VDCU_V
 SG_ XBRAccelerationLimit : 16|8@1+ (0.1,-12.5) [-12.5|12.5] "" VDCU_V
 SG_ PrkngBrkeActuatorFullyActivated : 24|2@1+ (1,0) [0|3] "" VDCU_V
 SG_ EmergencyBrakingActive : 26|2@1+ (1,0) [0|3] "" VDCU_V

BO_ 2566847015 Brakes: 8 VDCU_V
 SG_ BrakePrimaryPress : 8|8@1+ (4,0) [0|1000] "kPa" EBS
 SG_ BrakeSecondPress : 16|8@1+ (4,0) [0|1000] "kPa" EBS

BO_ 2565865767 MSF1_PropB_MC: 10 VDCU_V
 SG_ ABSOffroadSwitch_18F00127 : 16|2@1+ (1,0) [0|3] "" EBS
 SG_ ASROffroadSwitch_18F00127 : 18|2@1+ (1,0) [0|3] "" EBS
 SG_ ASRHillHolderSwitch_18F00127 : 20|2@1+ (1,0) [0|3] "" EBS
 SG_ EngRetarderSelection : 32|8@1+ (0.4,0) [0|100] "%" Vector__XXX
 SG_ HaltBrakeSwitch_18F00127 : 58|2@1+ (1,0) [0|3] "" EBS
 SG_ TrctrMntdTrailerABSWarningSignal : 62|2@1+ (1,0) [0|3] "" Vector__XXX
 SG_ MessageChecksumAR2_18F00127 : 64|8@1+ (1,0) [0|255] "" Vector__XXX
 SG_ MessageCounter_18F00127 : 72|4@1+ (1,0) [0|15] "" Vector__XXX

BO_ 2565865511 ERC1_MC: 10 VDCU_V
 SG_ DrvrsDemandRetarderPercentTorque : 40|8@1+ (1,-125) [-125|0] "%" EBS
 SG_ RetarderSelectionNonengine : 48|8@1+ (0.4,0) [0|100] "%" EBS
 SG_ MessageChecksumAR2_18F00027 : 64|8@1+ (1,0) [0|255] "" EBS
 SG_ MessageCounter_18F00027 : 72|4@1+ (1,0) [0|15] "" EBS

BO_ 2566857767 PropB_RetLever: 8 VDCU_V
 SG_ RetarderLeverState : 0|8@1+ (0.4,0) [0|100] "%" EBS

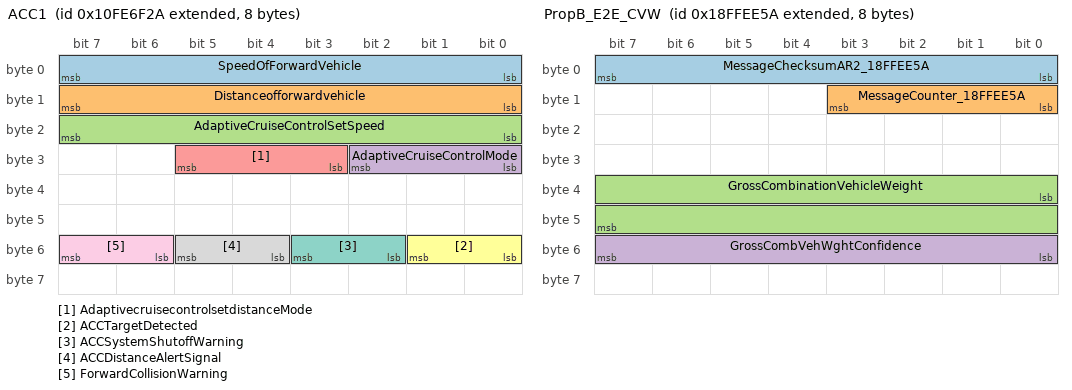
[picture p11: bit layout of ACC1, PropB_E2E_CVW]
BO_ 2432593706 ACC1: 8 FCS
 SG_ SpeedOfForwardVehicle : 0|8@1+ (1,0) [0|250] "" VDCU_V
 SG_ Distanceofforwardvehicle : 8|8@1+ (1,0) [0|250] "" VDCU_V
 SG_ AdaptiveCruiseControlSetSpeed : 16|8@1+ (1,0) [0|250] "" VDCU_V
 SG_ AdaptiveCruiseControlMode : 24|3@1+ (1,0) [0|7] "" VDCU_V
 SG_ AdaptivecruisecontrolsetdistanceMode : 27|3@1+ (1,0) [0|7] "" VDCU_V
 SG_ ACCTargetDetected : 48|2@1+ (1,0) [0|3] "" VDCU_V
 SG_ ACCSystemShutoffWarning : 50|2@1+ (1,0) [0|3] "" VDCU_V
 SG_ ACCDistanceAlertSignal : 52|2@1+ (1,0) [0|3] "" VDCU_V
 SG_ ForwardCollisionWarning : 54|2@1+ (1,0) [0|3] "" VDCU_V

BO_ 2365479471 ASC1_SSC: 8 ECAS
 SG_ NominalLevelFrontAxle : 0|4@1+ (1,0) [0|15] "" VDCU_V

BO_ 2566842927 VW: 8 ECAS
 SG_ AxleLocation : 0|8@1+ (1,0) [0|255] "/" VDCU_V

BO_ 2566909530 PropB_E2E_CVW: 8 VDCU_V
 SG_ MessageChecksumAR2_18FFEE5A : 0|8@1+ (1,0) [0|255] "" EBS
 SG_ MessageCounter_18FFEE5A : 8|4@1+ (1,0) [0|15] "" EBS
 SG_ GrossCombinationVehicleWeight : 32|16@1+ (10,0) [0|642550] "kg" EBS
 SG_ GrossCombVehWghtConfidence : 48|8@1+ (0.4,0) [0|100] "%" EBS

BO_ 2364551072 AEBS1: 8 ADCU
 SG_ AdvancedemergencybrakingsystemstateAEBS1 : 0|4@1+ (1,0) [0|15] "" VDCU_V
 SG_ Collision_warning_level : 4|4@1+ (1,0) [0|15] "" VDCU_V

BO_ 2365484270 TCO1: 8 CDCU
 SG_ TachographVehicleSpeed : 48|16@1+ (0.00390625,0) [0|250.996] "km/h" VDCU_V

BO_ 2566832622 VDHR: 8 CDCU
 SG_ HighResolutionTotalVehicleDistance : 0|32@1+ (0.005,0) [0|21055406] "km" VDCU_V
 SG_ HighResolutionTripDistance : 32|32@1+ (0.005,0) [0|21055406] "km" VDCU_V

BO_ 2566841327 EC1_EF: 39 VDCU_V
 SG_ EngSpeedAtIdlePoint1_ : 0|16@1+ (0.125,0) [0|8031.875] "rpm" VDR_TBOX,ADCU,EBS
 SG_ EM1ReferenceTorque_ : 152|16@1+ (1,0) [0|64255] "N?m" VDR_TBOX,ADCU,EBS

BO_ 2566840303 EEC3_EM1: 8 VDCU_V
 SG_ NominalFrictionPercentTorque_EF : 0|8@1+ (1,-125) [-125|125] "%" VDR_TBOX,ADCU,EPB,EBS,EPS_M,EPS_S
 SG_ EstEM1PrsticLossesPercentTorque_ : 32|8@1+ (1,-125) [-125|125] "%" VDR_TBOX,ADCU,EPB,EBS,EPS_M,EPS_S

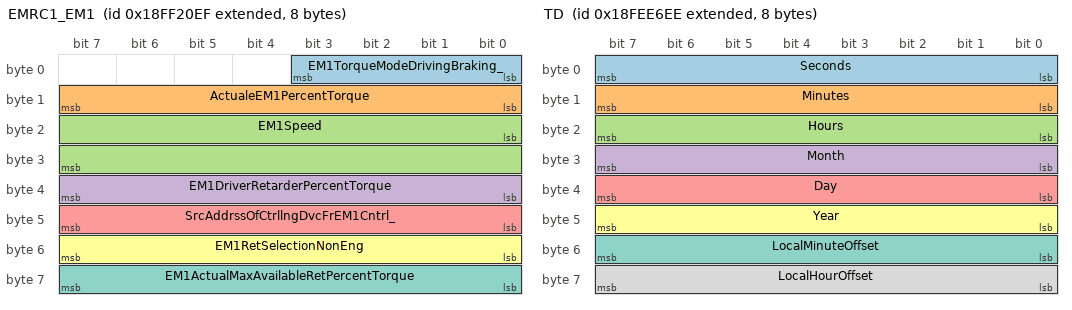
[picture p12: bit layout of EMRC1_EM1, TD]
BO_ 2566856943 EMRC1_EM1: 8 VDCU_V
 SG_ EM1TorqueModeDrivingBraking_ : 0|4@1+ (1,0) [0|15] "" VDR_TBOX,ADCU,EPB,EBS,EPS_M,EPS_S
 SG_ ActualeEM1PercentTorque : 8|8@1+ (1,-125) [-125|125] "%" VDR_TBOX,ADCU,EPB,EBS,EPS_M,EPS_S
 SG_ EM1Speed : 16|16@1+ (0.25,0) [0|16255.75] "rpm" VDR_TBOX,ADCU,EPB,EBS,EPS_M,EPS_S
 SG_ EM1DriverRetarderPercentTorque : 32|8@1+ (1,-125) [-125|125] "" VDR_TBOX,ADCU,EPB,EBS,EPS_M,EPS_S
 SG_ SrcAddrssOfCtrllngDvcFrEM1Cntrl_ : 40|8@1+ (1,0) [0|255] "" VDR_TBOX,ADCU,EPB,EBS,EPS_M,EPS_S
 SG_ EM1RetSelectionNonEng : 48|8@1+ (0.4,0) [0|100] "%" VDR_TBOX,ADCU,EPB,EBS,EPS_M,EPS_S
 SG_ EM1ActualMaxAvailableRetPercentTorque : 56|8@1+ (1,-125) [-125|125] "%" VDR_TBOX,ADCU,EPB,EBS,EPS_M,EPS_S

BO_ 2566840815 RC1_EF: 19 VDCU_V
 SG_ RetarderType_EF_ : 0|4@1+ (1,0) [0|15] "" VDR_TBOX,ADCU,EBS
 SG_ RetarderLocation_EF : 4|4@1+ (1,0) [0|15] "" VDR_TBOX,ADCU,EBS
 SG_ ReferenceRetarderTorque_EF : 128|16@1+ (1,0) [0|64255] "Nm" VDR_TBOX,ADCU,EBS

BO_ 2566701807 HSS1: 8 VDCU_V
 SG_ PropulsionSystemActive_Ready : 8|2@1+ (1,0) [0|3] "" EPB

BO_ 2566842094 TD: 8 VDR_TBOX
 SG_ Seconds : 0|8@1+ (0.25,0) [0|63.75] "s" VDCU_V
 SG_ Minutes : 8|8@1+ (1,0) [0|255] "mins" VDCU_V
 SG_ Hours : 16|8@1+ (1,0) [0|255] "hr" VDCU_V
 SG_ Month : 24|8@1+ (1,0) [0|255] "months" VDCU_V
 SG_ Day : 32|8@1+ (0.25,0) [0|63.75] "days" VDCU_V
 SG_ Year : 40|8@1+ (1,1985) [1985|2240] "years" VDCU_V
 SG_ LocalMinuteOffset : 48|8@1+ (1,-125) [-125|130] "min" VDCU_V
 SG_ LocalHourOffset : 56|8@1+ (1,-125) [-125|130] "h" VDCU_V

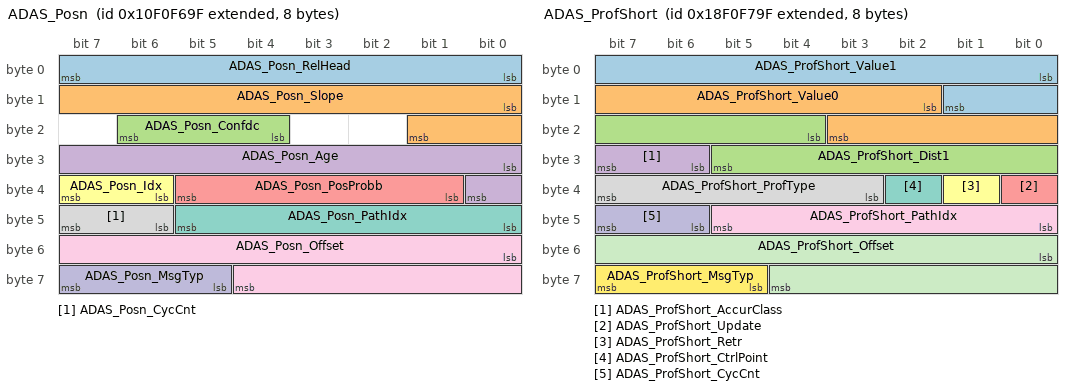
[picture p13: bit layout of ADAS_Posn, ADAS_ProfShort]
BO_ 2431710879 ADAS_Posn: 8 VDR_TBOX
 SG_ ADAS_Posn_RelHead : 0|8@1+ (1.4173228,0) [-180|178.583] "degree" VDCU_V
 SG_ ADAS_Posn_Slope : 8|10@1+ (1,0) [0|1024] "" VDCU_V
 SG_ ADAS_Posn_Confdc : 20|3@1+ (1,0) [0|6] "" VDCU_V
 SG_ ADAS_Posn_Age : 24|9@1+ (5,0) [0|2545] "ms" VDCU_V
 SG_ ADAS_Posn_PosProbb : 33|5@1+ (3.33333333,0) [0|100] "%" VDCU_V
 SG_ ADAS_Posn_Idx : 38|2@1+ (1,0) [0|3] "" VDCU_V
 SG_ ADAS_Posn_PathIdx : 40|6@1+ (1,0) [0|63] "" VDCU_V
 SG_ ADAS_Posn_CycCnt : 46|2@1+ (1,0) [0|3] "" VDCU_V
 SG_ ADAS_Posn_Offset : 48|13@1+ (1,0) [0|8191] "m" VDCU_V
 SG_ ADAS_Posn_MsgTyp : 61|3@1+ (1,0) [0|6] "" VDCU_V

BO_ 2498819743 ADAS_Stub: 8 VDR_TBOX
 SG_ ADAS_Stub_NumOfLaneDrvDir : 0|3@1+ (1,0) [0|6] "" VDCU_V
 SG_ ADAS_Stub_NumOfLaneOppDir : 3|2@1+ (1,0) [0|2] "" VDCU_V
 SG_ ADAS_Stub_RtOfWay : 5|2@1+ (1,0) [0|1] "" VDCU_V
 SG_ ADAS_Stub_LastStub : 7|1@1+ (1,0) [0|1] "" VDCU_V
 SG_ ADAS_Stub_TurnAngl : 8|8@1+ (1,0) [0|255] "" VDCU_V
 SG_ ADAS_Stub_FormOfWay_ : 16|4@1+ (1,0) [1|14] "" VDCU_V
 SG_ ADAS_Stub_CmplxInsct : 20|2@1+ (1,0) [0|1] "" VDCU_V
 SG_ ADAS_Stub_PartOfCalcRoute : 22|2@1+ (1,0) [0|1] "" VDCU_V
 SG_ ADAS_Stub_FuncRoadClass : 24|3@1+ (1,0) [1|6] "" VDCU_V
 SG_ ADAS_Stub_RelProbb : 27|5@1+ (3.33333333,0) [0|100] "%" VDCU_V
 SG_ ADAS_Stub_Update : 32|1@1+ (1,0) [0|1] "" VDCU_V
 SG_ ADAS_Stub_Retr : 33|1@1+ (1,0) [0|0] "" VDCU_V
 SG_ ADAS_Stub_SubPathIdx : 34|6@1+ (1,0) [5|63] "" VDCU_V
 SG_ ADAS_Stub_PathIdx : 40|6@1+ (1,0) [1|63] "" VDCU_V
 SG_ ADAS_Stub_CycCnt : 46|2@1+ (1,0) [0|3] "" VDCU_V
 SG_ ADAS_Stub_Offset : 48|13@1+ (1,0) [0|8190] "m" VDCU_V
 SG_ ADAS_Stub_MsgType : 61|3@1+ (1,0) [0|6] "" VDCU_V

BO_ 2565928863 ADAS_ProfShort: 8 VDR_TBOX
 SG_ ADAS_ProfShort_Value1 : 0|10@1+ (1,0) [0|1022] "" VDCU_V
 SG_ ADAS_ProfShort_Value0 : 10|10@1+ (1,0) [0|1022] "" VDCU_V
 SG_ ADAS_ProfShort_Dist1 : 20|10@1+ (1,0) [0|1022] "" VDCU_V
 SG_ ADAS_ProfShort_AccurClass : 30|2@1+ (1,0) [0|2] "" VDCU_V
 SG_ ADAS_ProfShort_Update : 32|1@1+ (1,0) [0|1] "" VDCU_V
 SG_ ADAS_ProfShort_Retr : 33|1@1+ (1,0) [0|1] "" VDCU_V
 SG_ ADAS_ProfShort_CtrlPoint : 34|1@1+ (1,0) [0|1] "" VDCU_V
 SG_ ADAS_ProfShort_ProfType : 35|5@1+ (1,0) [1|31] "" VDCU_V
 SG_ ADAS_ProfShort_PathIdx : 40|6@1+ (1,0) [0|63] "" VDCU_V
 SG_ ADAS_ProfShort_CycCnt : 46|2@1+ (1,0) [0|3] "" VDCU_V
 SG_ ADAS_ProfShort_Offset : 48|13@1+ (1,0) [0|8190] "m" VDCU_V
 SG_ ADAS_ProfShort_MsgTyp : 61|3@1+ (1,0) [0|6] "" VDCU_V

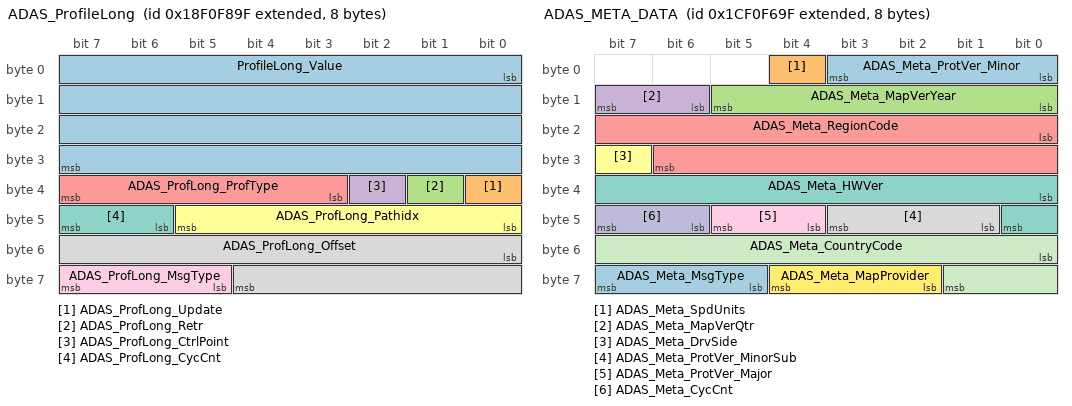
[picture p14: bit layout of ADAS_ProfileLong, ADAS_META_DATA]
BO_ 2565929119 ADAS_ProfileLong: 8 VDR_TBOX
 SG_ ProfileLong_Value : 0|32@1+ (1,0) [0|4294967295] "" VDCU_V
 SG_ ADAS_ProfLong_Update : 32|1@1+ (1,0) [0|2] "" VDCU_V
 SG_ ADAS_ProfLong_Retr : 33|1@1+ (1,0) [0|2] "" VDCU_V
 SG_ ADAS_ProfLong_CtrlPoint : 34|1@1+ (1,0) [0|2] "" VDCU_V
 SG_ ADAS_ProfLong_ProfType : 35|5@1+ (1,0) [0|31] "" VDCU_V
 SG_ ADAS_ProfLong_Pathidx : 40|6@1+ (1,0) [0|63] "" VDCU_V
 SG_ ADAS_ProfLong_CycCnt : 46|2@1+ (1,0) [0|3] "" VDCU_V
 SG_ ADAS_ProfLong_Offset : 48|13@1+ (1,0) [0|8191] "" VDCU_V
 SG_ ADAS_ProfLong_MsgType : 61|3@1+ (1,0) [0|7] "" VDCU_V

BO_ 2565928607 ADAS_Segement: 8 VDR_TBOX
 SG_ ADAS_Seg_NumOfLaneDrvDir : 0|3@1+ (1,0) [1|0] "" VDCU_V
 SG_ ADAS_Seg_NumOfLaneOppDir : 3|2@1+ (1,0) [1|0] "" VDCU_V
 SG_ ADAS_Seg_DividedRoad : 5|2@1+ (1,0) [1|0] "" VDCU_V
 SG_ ADAS_Seg_EffSpdLmtType : 8|3@1+ (1,0) [1|0] "" VDCU_V
 SG_ ADAS_Seg_EffSpdLmt : 11|5@1+ (1,0) [5|0] "" VDCU_V
 SG_ ADAS_Seg_FormOfWay : 16|4@1+ (1,0) [1|0] "" VDCU_V
 SG_ ADAS_Seg_CmplxInsct : 20|2@1+ (1,0) [1|0] "" VDCU_V
 SG_ ADAS_Seg_PartOfCalcRoute : 22|2@1+ (1,0) [1|0] "" VDCU_V
 SG_ ADAS_Seg_FuncRoadClass : 24|3@1+ (1,0) [1|0] "" VDCU_V
 SG_ ADAS_Seg_RelProbb : 27|5@1+ (3.33333333,0) [3.33|0] "" VDCU_V
 SG_ ADAS_Seg_Update : 32|1@1+ (1,0) [1|0] "" VDCU_V
 SG_ ADAS_Seg_Retr : 33|1@1+ (1,0) [1|0] "" VDCU_V
 SG_ ADAS_Seg_BuildUpArea : 34|2@1+ (1,0) [1|0] "" VDCU_V
 SG_ ADAS_Seg_Bridge : 36|2@1+ (1,0) [1|0] "" VDCU_V
 SG_ ADAS_Seg_Tunnel : 38|2@1+ (1,0) [1|0] "" VDCU_V
 SG_ ADAS_Seg_Pathidx : 40|6@1+ (1,0) [1|0] "" VDCU_V
 SG_ ADAS_Seg_CycCnt : 46|2@1+ (1,0) [1|0] "" VDCU_V
 SG_ ADAS_Seg_Offset : 48|13@1+ (1,0) [1|0] "" VDCU_V
 SG_ ADAS_Seg_MsgType : 61|3@1+ (1,0) [1|0] "" VDCU_V

BO_ 2633037471 ADAS_META_DATA: 8 VDR_TBOX
 SG_ ADAS_Meta_ProtVer_Minor : 0|4@1+ (1,0) [0|15] "" VDCU_V
 SG_ ADAS_Meta_SpdUnits : 4|1@1+ (1,0) [0|1] "" VDCU_V
 SG_ ADAS_Meta_MapVerYear : 8|6@1+ (1,0) [0|63] "" VDCU_V
 SG_ ADAS_Meta_MapVerQtr : 14|2@1+ (1,0) [0|3] "" VDCU_V
 SG_ ADAS_Meta_RegionCode : 16|15@1+ (1,0) [0|32767] "" VDCU_V
 SG_ ADAS_Meta_DrvSide : 31|1@1+ (1,0) [0|1] "" VDCU_V
 SG_ ADAS_Meta_HWVer : 32|9@1+ (1,0) [0|511] "" VDCU_V
 SG_ ADAS_Meta_ProtVer_MinorSub : 41|3@1+ (1,0) [0|7] "" VDCU_V
 SG_ ADAS_Meta_ProtVer_Major : 44|2@1+ (1,0) [0|3] "" VDCU_V
 SG_ ADAS_Meta_CycCnt : 46|2@1+ (1,0) [0|3] "" VDCU_V
 SG_ ADAS_Meta_CountryCode : 48|10@1+ (1,0) [0|1023] "" VDCU_V
 SG_ ADAS_Meta_MapProvider : 58|3@1+ (1,0) [0|7] "" VDCU_V
 SG_ ADAS_Meta_MsgType : 61|3@1+ (1,0) [0|7] "" VDCU_V

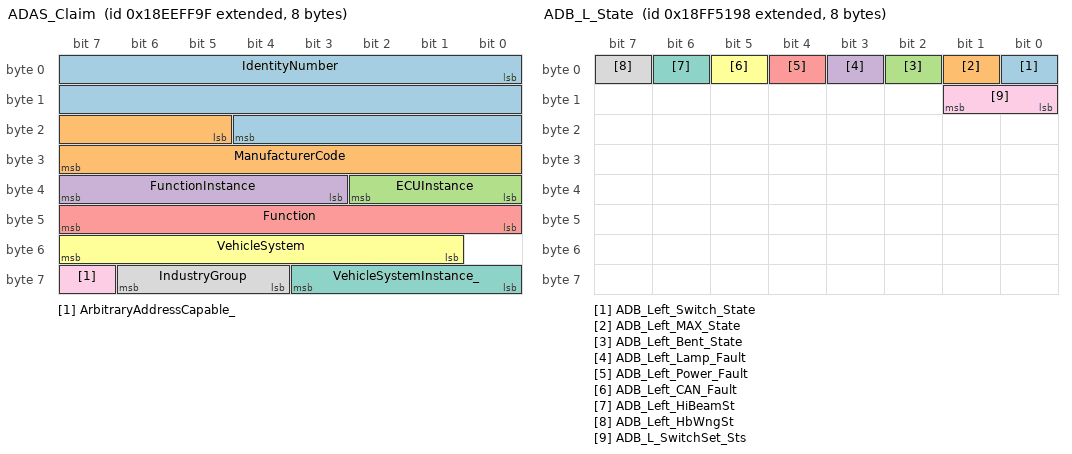
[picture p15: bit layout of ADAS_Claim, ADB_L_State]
BO_ 2565799839 ADAS_Claim: 8 VDR_TBOX
 SG_ IdentityNumber : 0|21@1+ (1,0) [0|2097151] "" VDCU_V
 SG_ ManufacturerCode : 21|11@1+ (1,0) [0|1023] "" VDCU_V
 SG_ ECUInstance : 32|3@1+ (1,0) [0|7] "" VDCU_V
 SG_ FunctionInstance : 35|5@1+ (1,0) [0|31] "" VDCU_V
 SG_ Function : 40|8@1+ (1,0) [0|255] "" VDCU_V
 SG_ VehicleSystem : 49|7@1+ (1,0) [0|127] "" VDCU_V
 SG_ VehicleSystemInstance_ : 56|4@1+ (1,0) [0|15] "" VDCU_V
 SG_ IndustryGroup : 60|3@1+ (1,0) [0|7] "" VDCU_V
 SG_ ArbitraryAddressCapable_ : 63|1@1+ (1,0) [0|1] "" VDCU_V

BO_ 2566845343 GPS1_0x18FEF39F: 8 VDR_TBOX
 SG_ Latitude : 0|32@1+ (1.0E-7,-210) [-211|211.1081215] "deg" VDCU_V
 SG_ Longitude : 32|32@1+ (1.0E-7,-210) [-211|211.1081215] "deg" VDCU_V

BO_ 2566842527 GPS2_0x18FEE89F: 8 VDR_TBOX
 SG_ Navigation_BasedVehicleSpeed : 16|16@1+ (0.00390625,0) [0|250.996] "kph" VDCU_V
 SG_ Altitude : 48|16@1+ (0.125,-2500) [-2500|5531.875] "m" VDCU_V

BO_ 2633037727 Gradient_0x1CF0F79F: 8 VDR_TBOX
 SG_ ADASProfileShortSlope : 0|10@1+ (0.1,-51.1) [-51.1|51.1] "%" VDCU_V

BO_ 2566869400 ADB_L_State: 8 VDCU_V
 SG_ ADB_Left_Switch_State : 0|1@1+ (1,0) [0|1] "" Vector__XXX
 SG_ ADB_Left_MAX_State : 1|1@1+ (1,0) [0|1] "" Vector__XXX
 SG_ ADB_Left_Bent_State : 2|1@1+ (1,0) [0|1] "" Vector__XXX
 SG_ ADB_Left_Lamp_Fault : 3|1@1+ (1,0) [0|1] "" Vector__XXX
 SG_ ADB_Left_Power_Fault : 4|1@1+ (1,0) [0|1] "" Vector__XXX
 SG_ ADB_Left_CAN_Fault : 5|1@1+ (1,0) [0|1] "" Vector__XXX
 SG_ ADB_Left_HiBeamSt : 6|1@1+ (1,0) [0|1] "" Vector__XXX
 SG_ ADB_Left_HbWngSt : 7|1@1+ (1,0) [0|1] "" Vector__XXX
 SG_ ADB_L_SwitchSet_Sts : 8|2@1+ (1,0) [0|3] "" CDCU

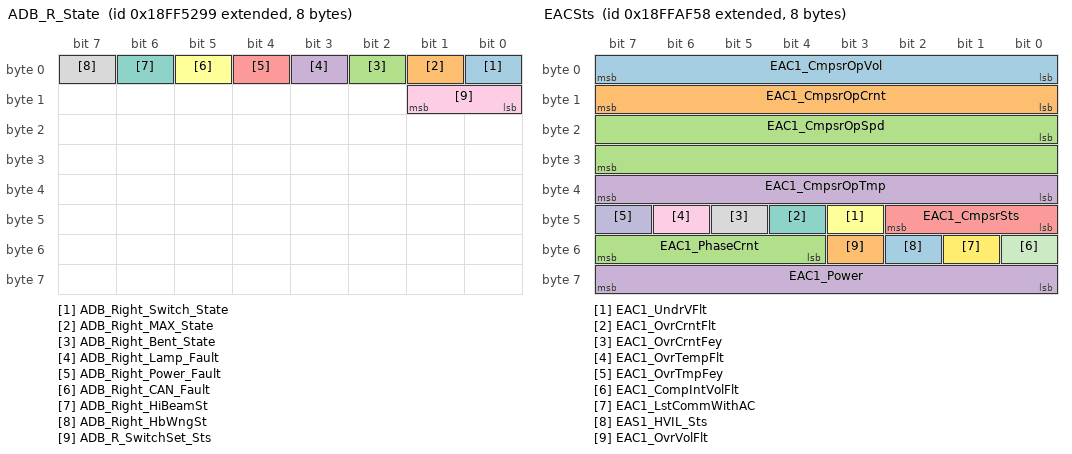
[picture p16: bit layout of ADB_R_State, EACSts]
BO_ 2566869657 ADB_R_State: 8 VDCU_V
 SG_ ADB_Right_Switch_State : 0|1@1+ (1,0) [0|1] "" Vector__XXX
 SG_ ADB_Right_MAX_State : 1|1@1+ (1,0) [0|1] "" Vector__XXX
 SG_ ADB_Right_Bent_State : 2|1@1+ (1,0) [0|1] "" Vector__XXX
 SG_ ADB_Right_Lamp_Fault : 3|1@1+ (1,0) [0|1] "" Vector__XXX
 SG_ ADB_Right_Power_Fault : 4|1@1+ (1,0) [0|1] "" Vector__XXX
 SG_ ADB_Right_CAN_Fault : 5|1@1+ (1,0) [0|1] "" Vector__XXX
 SG_ ADB_Right_HiBeamSt : 6|1@1+ (1,0) [0|1] "" Vector__XXX
 SG_ ADB_Right_HbWngSt : 7|1@1+ (1,0) [0|1] "" Vector__XXX
 SG_ ADB_R_SwitchSet_Sts : 8|2@1+ (1,0) [0|3] "" CDCU

BO_ 2566893400 EACSts: 8 VDCU_V
 SG_ EAC1_CmpsrOpVol : 0|8@1+ (4,0) [0|1000] "V" Vector__XXX
 SG_ EAC1_CmpsrOpCrnt : 8|8@1+ (0.1,0) [0|25] "A" Vector__XXX
 SG_ EAC1_CmpsrOpSpd : 16|16@1+ (1,0) [0|6000] "rpm" VDR_TBOX
 SG_ EAC1_CmpsrOpTmp : 32|8@1+ (1,-40) [-40|215] "℃" Vector__XXX
 SG_ EAC1_CmpsrSts : 40|3@1+ (1,0) [0|7] "" Vector__XXX
 SG_ EAC1_UndrVFlt : 43|1@1+ (1,0) [0|1] "" Vector__XXX
 SG_ EAC1_OvrCrntFlt : 44|1@1+ (1,0) [0|1] "" Vector__XXX
 SG_ EAC1_OvrCrntFey : 45|1@1+ (1,0) [0|1] "" Vector__XXX
 SG_ EAC1_OvrTempFlt : 46|1@1+ (1,0) [0|1] "" Vector__XXX
 SG_ EAC1_OvrTmpFey : 47|1@1+ (1,0) [0|1] "" Vector__XXX
 SG_ EAC1_CompIntVolFlt : 48|1@1+ (1,0) [0|1] "" Vector__XXX
 SG_ EAC1_LstCommWithAC : 49|1@1+ (1,0) [0|1] "" Vector__XXX
 SG_ EAS1_HVIL_Sts : 50|1@1+ (1,0) [0|1] "" Vector__XXX
 SG_ EAC1_OvrVolFlt : 51|1@1+ (1,0) [0|1] "" Vector__XXX
 SG_ EAC1_PhaseCrnt : 52|4@1+ (2,0) [0|30] "A" Vector__XXX
 SG_ EAC1_Power : 56|8@1+ (100,0) [0|25500] "W" Vector__XXX

BO_TX_BU_ 2348810282 : ADCU,FCS;
BO_TX_BU_ 2349465642 : ADCU,FCS;
BO_TX_BU_ 2364551072 : ADCU,FCS;
CM_ BO_ 2498819743 "向前探索路网时遇到路口就会发送，发送一帧，没有固定时间周期";
CM_ BO_ 2565928863 "向前探索路网时，有ADAS属性就会发送(坡度、曲率等)，发送一帧，没有固定时间周期";
CM_ BO_ 2565929119 "按照地图中的道路分段编号发送(一段link发一条)";
CM_ BO_ 2565928607 "按照地图中的道路分段编号发送(一段link发一条)";
CM_ BO_ 2633037471 "一启动就发送";
CM_ BO_ 2565799839 "周期报文，与发动机握手用";
CM_ BO_ 2566893400 "驾驶室压缩机（氢燃料）//驾驶室&动力电池压缩机（纯电动）_状态";
CM_ SG_ 2348810282 EngRqedSpeedCtrlConditions_C00002A "This mode tells the engine control system the governor characteristics that are desired during speed control.";
CM_ SG_ 2348810282 EngRqedSpeed_SpeedLimit_C00002A "Parameter provided to the engine from external sources in the torque/speed control message.Invalid Value:0xFB00~ALLFF";
CM_ SG_ 2348810282 EngRqedTorque_TorqueLimit "Parameter provided to the engine or retarder in the torque/speed control message for controlling or limiting the output torque.无效值：0xFB-ALL";
CM_ SG_ 2348810282 TransmissionRate_C00002A "This parameter indicates the transmission rate at which the sending device will transmit the TSC1 message.";
CM_ SG_ 2348810282 ControlPurpose_C00002A "State signal which indicates which control mode the sending device is using to generate the TSC1 command.";
CM_ SG_ 2348810282 EngineRequestedTorqueHiRes_C00002A "This parameter displays an additional torque in percent of the reference engine torque.";
CM_ SG_ 2348810282 MessageCounter_C00002A "The message counter is used to detect situations where the transmitting ECU malfunction repeats the same frame all the time.";
CM_ SG_ 2348810282 MessageChecksum_C00002A "The checksum is used to verify the signal path from the transmitting device to the receiving device.";
CM_ SG_ 2349465642 CruiseControlPauseCommand "This parameter is used to temporarily disable cruise control from a source other than the driver controlled switch if cruise control is active.  If this parameter is used to disable cruise control, then cruise control will not need to be re-initialized and the previous set speed will be retained.  In order for the cruise control system to resume to the previous set speed, a valid command must be received. 巡航控制暂停";
CM_ SG_ 2566859752 HazardSwRq "危险报警灯请求";
CM_ SG_ 2566859752 LowBeamSwRq "Command to activate or de-activate the tractor low beam head light lamps.近光灯";
CM_ SG_ 2566859752 HighBeamSwRq "Command to activate or de-activate the tractor high beam head light lamps.远光灯";
CM_ SG_ 2566859752 IHBC_Status "IHBC状态";
CM_ SG_ 2566859752 SLI_Status "SLI状态";
CM_ SG_ 2566859752 SLIF_Status "SLIF状态";
CM_ SG_ 2566859752 SLIF_Warning "SLIF报警";
CM_ SG_ 2566859752 Sign_Speedlimit "速度限制符号值";
CM_ SG_ 2566859752 Sign_SpeedLimitCancelled "速度限制取消";
CM_ SG_ 2566787664 EPB_ParkBraStatus "EPB驻车状态";
CM_ SG_ 2566787664 AH_ParkActive "Auto Hold制动状态(当激活后满足条件才会制动)";
CM_ SG_ 2566787664 AH_BraStatus "Autohold功能激活状态";
CM_ SG_ 2566787664 EPB_WorkMode "压力控制模式时可以控制驻车力度大小，发送相应的需求开关开度请求可实现相应驻车力度。";
CM_ SG_ 2566787664 ErrCode "00无故障；非00EPB故障，详见故障码清单";
CM_ SG_ 2566787664 ChildLockActive "童锁激活（没踩脚刹去操作开关释放驻车将激活）";
CM_ SG_ 2566787664 LowPreRelParkLimit "低压释放限制开启";
CM_ SG_ 2566787664 TrailerCnctChck "甩挂,挂车制动检查，7公里以下车速允许挂车独立制动。";
CM_ SG_ 2566787664 ResponsePriority "（当操作开关与无人驾驶控制相反时将激活人为控制优先，响应认为操作指令）";
CM_ SG_ 2566787664 IdepedtBraOly "挂车独立制动";
CM_ SG_ 2566787664 PrakBraForcTest "驻车力度检测";
CM_ SG_ 2566787664 DriveHillStatus "测试项";
CM_ SG_ 2566787664 EPB_BraSwitch "制动开关，行驶过程中拉EPB开关将发送该信号用于点亮制动灯。";
CM_ SG_ 2566787664 ParkBtSwitch "操作驻车开关将置位";
CM_ SG_ 2566787664 RelsBtSwitch "操作释放开关将置位";
CM_ SG_ 2566787664 AHBtSwitch "操作autohold开关将置位";
CM_ SG_ 2566787664 IdepedtBtSwitch "操作挂车独立制动开关将置位";
CM_ SG_ 2566787664 ForcTestBtSwitch "操作检测点开关将置位";
CM_ SG_ 2566787664 SysStatus "系统是否能响应无人驾驶（Not Ready时不能响应）";
CM_ SG_ 2566787664 WarmingStatus "仪表警告声音";
CM_ SG_ 2566787664 RollerTestBenchMode "滚筒模式";
CM_ SG_ 2566787664 ParkBraPres "驻车气压";
CM_ SG_ 2566787664 PTposition "开关位置";
CM_ SG_ 2365562448 EPBC1MsgSrc "The source address of the EPBC1 Active Unit(当前响应的报文源)";
CM_ SG_ 2365562448 ParkBrkPress "Gage pressure of compressed air or fluid in vehicle braking system measured at the brake chamber when brake shoe (or pad) is placed against brake drum .(驻车制动气压)";
CM_ SG_ 2365562448 EPB_HaltBrakeSt "Signal which indicates the current mode of the EPB halt brake function..临停状态";
CM_ SG_ 2566847056 BrakeAppPress "驻车气压";
CM_ SG_ 2566911764 DriverInterventionStatus_S "DriverInterventionStatus（驾驶员介入检测）";
CM_ SG_ 2566897256 WPTC1_InletTemp "入口温度";
CM_ SG_ 2566897256 WPTC1_OutletTemp "出口温度";
CM_ SG_ 2566897256 WPTC1_CtrlSysTemp "控制系统温度 IGBT 温度";
CM_ SG_ 2566897256 WPTC1_HVVoltage "高压侧电压";
CM_ SG_ 2566897256 WPTC1_HeaterPower "加热器功率";
CM_ SG_ 2566897256 WPTC1_WorkingSts "工作状态";
CM_ SG_ 2566897256 WPTC1_FaultLevel "故障等级0X00:NO Fault0X01:1级故障(轻微故障:高压过压,高压欠压,低压过压,低压欠压,高压回路开路)0x02:2级故障(一般故障:PTC出水口过温,IGBT过温,通信丢失)0x03:3级故障(严重故障:IGBT短路,低流量（干烧）,过流故障,PTC短路,NTC故障)";
CM_ SG_ 2566897256 WPTC1_HVOverVoltage "高压过压";
CM_ SG_ 2566897256 WPTC1_HVUnderVoltage "高压欠压";
CM_ SG_ 2566897256 WPTC1_LVOverVoltage "低压过压";
CM_ SG_ 2566897256 WPTC1_LVUnderVoltage "低压欠压";
CM_ SG_ 2566897256 WPTC1_OpenCircuit "高压回路开路";
CM_ SG_ 2566897256 WPTC1_OutletOverheating "PTC出水口过温(＞95℃)";
CM_ SG_ 2566897256 WPTC1_IGBTOverheating "IGBT过温(＞120℃)";
CM_ SG_ 2566897256 WPTC1_ComLoss "通信丢失";
CM_ SG_ 2566897256 WPTC1_IGBTShortCircuit "IGBT短路";
CM_ SG_ 2566897256 WPTC1_LowFlowrate "低流量（干烧，水温＞50℃后，5s内上升超过10℃）";
CM_ SG_ 2566897256 WPTC1_OvercurrentFault "过流故障";
CM_ SG_ 2566897256 WPTC1_PTCShortCircuit "PTC短路";
CM_ SG_ 2566897256 WPTC1_NTCFault "NTC故障";
CM_ SG_ 2566897256 WPTC1_SoftwareVersion "软件版本号,如软件版本号为V1.1则发送0x11";
CM_ SG_ 2566897283 WPTC2_InletTemp "入口温度";
CM_ SG_ 2566897283 WPTC2_OutletTemp "出口温度";
CM_ SG_ 2566897283 WPTC2_CtrlSysTemp "控制系统温度 IGBT 温度";
CM_ SG_ 2566897283 WPTC2_HVVoltage "高压侧电压";
CM_ SG_ 2566897283 WPTC2_HeaterPower "加热器功率";
CM_ SG_ 2566897283 WPTC2_WorkingSts "工作状态";
CM_ SG_ 2566897283 WPTC2_FaultLevel "故障等级0X00:NO Fault0X01:1级故障(轻微故障:高压过压,高压欠压,低压过压,低压欠压,高压回路开路)0x02:2级故障(一般故障:PTC出水口过温,IGBT过温,通信丢失)0x03:3级故障(严重故障:IGBT短路,低流量（干烧）,过流故障,PTC短路,NTC故障)";
CM_ SG_ 2566897283 WPTC2_HVOverVoltage "高压过压";
CM_ SG_ 2566897283 WPTC2_HVUnderVoltage "高压欠压";
CM_ SG_ 2566897283 WPTC2_LVOverVoltage "低压过压";
CM_ SG_ 2566897283 WPTC2_LVUnderVoltage "低压欠压";
CM_ SG_ 2566897283 WPTC2_OpenCircuit "高压回路开路";
CM_ SG_ 2566897283 WPTC2_OutletOverheating "PTC出水口过温(＞95℃)";
CM_ SG_ 2566897283 WPTC2_IGBTOverheating "IGBT过温(＞120℃)";
CM_ SG_ 2566897283 WPTC2_ComLoss "通信丢失";
CM_ SG_ 2566897283 WPTC2_IGBTShortCircuit "IGBT短路";
CM_ SG_ 2566897283 WPTC2_LowFlowrate "低流量（干烧，水温＞50℃后，5s内上升超过10℃）";
CM_ SG_ 2566897283 WPTC2_OvercurrentFault "过流故障";
CM_ SG_ 2566897283 WPTC2_PTCShortCircuit "PTC短路";
CM_ SG_ 2566897283 WPTC2_NTCFault "NTC故障";
CM_ SG_ 2566897283 WPTC2_SoftwareVersion "软件版本号,如软件版本号为V1.1则发送0x11";
CM_ SG_ 2566897284 WPTC3_InletTemp "入口温度";
CM_ SG_ 2566897284 WPTC3_OutletTemp "出口温度";
CM_ SG_ 2566897284 WPTC3_CtrlSysTemp "控制系统温度 IGBT 温度";
CM_ SG_ 2566897284 WPTC3_HVVoltage "高压侧电压";
CM_ SG_ 2566897284 WPTC3_HeaterPower "加热器功率";
CM_ SG_ 2566897284 WPTC3_WorkingSts "工作状态";
CM_ SG_ 2566897284 WPTC3_FaultLevel "故障等级0X00:NO Fault0X01:1级故障(轻微故障:高压过压,高压欠压,低压过压,低压欠压,高压回路开路)0x02:2级故障(一般故障:PTC出水口过温,IGBT过温,通信丢失)0x03:3级故障(严重故障:IGBT短路,低流量（干烧）,过流故障,PTC短路,NTC故障)";
CM_ SG_ 2566897284 WPTC3_HVOverVoltage "高压过压";
CM_ SG_ 2566897284 WPTC3_HVUnderVoltage "高压欠压";
CM_ SG_ 2566897284 WPTC3_LVOverVoltage "低压过压";
CM_ SG_ 2566897284 WPTC3_LVUnderVoltage "低压欠压";
CM_ SG_ 2566897284 WPTC3_OpenCircuit "高压回路开路";
CM_ SG_ 2566897284 WPTC3_OutletOverheating "PTC出水口过温(＞95℃)";
CM_ SG_ 2566897284 WPTC3_IGBTOverheating "IGBT过温(＞120℃)";
CM_ SG_ 2566897284 WPTC3_ComLoss "通信丢失";
CM_ SG_ 2566897284 WPTC3_IGBTShortCircuit "IGBT短路";
CM_ SG_ 2566897284 WPTC3_LowFlowrate "低流量（干烧，水温＞50℃后，5s内上升超过10℃）";
CM_ SG_ 2566897284 WPTC3_OvercurrentFault "过流故障";
CM_ SG_ 2566897284 WPTC3_PTCShortCircuit "PTC短路";
CM_ SG_ 2566897284 WPTC3_NTCFault "NTC故障";
CM_ SG_ 2566897284 WPTC3_SoftwareVersion "软件版本号,如软件版本号为V1.1则发送0x11";
CM_ SG_ 2565865487 RetarderTorqueMode_18F0000F "State signal which indicates which retarder torque mode is currently generating, limiting, or controlling the torque.  Note that the modes are not in prioritized order. Not all modes may be relevant for a given device.";
CM_ SG_ 2565865487 ActualRetarderPercentTorque_18F0000F "Actual braking torque of the retarder as a percent of retarder configuration reference torque SPN 556.";
CM_ SG_ 2565865487 DrvrsDemandRetarderPercentTorque_18F0000F "The requested torque for the retarder by the driver. This includes the torque requested due to activation of the retarder lever";
CM_ SG_ 2565865487 ActlMxAvlblRetarderPercentTorque_18F0000F "This is the maximum amount of torque that the retarder can immediately deliver.   It is the same as the maximum torque shown in the Retarder's Configuration message";
CM_ SG_ 2566840591 ReferenceRetarderTorque_18FEE10F "This parameter is the 100% reference value for all defined indicated retarder torque parameters.  It is only defined once and doesn't change if a different retarder torque map becomes valid.";
CM_ SG_ 2565865488 ActualRetarderPercentTorque_1 "Actual braking torque of the retarder as a percent of retarder configuration reference torque SPN 556.";
CM_ SG_ 2565865488 RetarderRqingBrakeLight "Indicates that whether the retarder is requesting that the brake lights are illuminated.制动灯请求";
CM_ SG_ 2565865488 DriversDemandRetarderPercentTorque "The Drivers demand retarder – percent torque is the maximum torque selected by the driver when one or more modesare selected by the driver, such as hand lever, switch, constant torque, constant velocity, etc.";
CM_ SG_ 2565865488 ActlMxAvlblRtarderPercentTorque_ "This is the maximum amount of torque that the retarder can immediately deliver.";
CM_ SG_ 2566840592 RetarderType_10 "A vehicle retarder is a supplementary device to the wheel brakes for the driver to better control the vehicle.";
CM_ SG_ 2566840592 RetarderLocation_10 "This parameter defines whether the 搕orque/speed curve?defined by the retarder configuration message (PGN 65249) is";
CM_ SG_ 2566840592 ReferenceRetarderTorque_10 "This parameter is the 100% reference value for all defined indicated retarder torque parameters.";
CM_ SG_ 2565865513 RetarderTorqueMode "State signal which indicates which retarder torque mode is currently generating, limiting, or controlling the torque.  Note that the modes are not in prioritized order. Not all modes may be relevant for a given device.";
CM_ SG_ 2565865513 ActualRetarderPercentTorque "Actual braking torque of the retarder as a percent of retarder configuration reference torque SPN 556.";
CM_ SG_ 2565865513 DrvrsDemandRetarderPercentTorque_18F00029 "The requested torque for the retarder by the driver. This includes the torque requested due to activation of the retarder lever";
CM_ SG_ 2565865513 ActlMxAvlblRetarderPercentTorque "This is the maximum amount of torque that the retarder can immediately deliver.   It is the same as the maximum torque shown in the Retarder's Configuration message";
CM_ SG_ 2566840617 ReferenceRetarderTorque "This parameter is the 100% reference value for all defined indicated retarder torque parameters.  It is only defined once and doesn't change if a different retarder torque map becomes valid.";
CM_ SG_ 2348814091 EngOverrideCtrlMode_C000F0B "The override control mode defines which sort of command is used";
CM_ SG_ 2348814091 OverrideCtrlModePriority_C000F0B "This field is used as an input to the engine or retarder to determine the priority of the Override Control Mode received in the Torque/Speed Control message (see PGN 0).  The default is 11 (Low priority).";
CM_ SG_ 2348814091 EngRequestedTorque_TorqueLimit_C000F0B "Parameter provided to the engine or retarder in the torque/speed control message for controlling or limiting the output torque.";
CM_ SG_ 2348814091 MessageCounterJ1939_C000F0B "The message counter is used to detect situations where the transmitting ECU malfunction repeats the same frame all the time.  The receiver of the information may use the counter parameter to detect this situation.";
CM_ SG_ 2348814091 MessageChecksumJ1939_C000F0B "The message checksum is used to verify the signal path from the transmitting device to the receiving device.";
CM_ SG_ 2348814091 MessageChecksumAR2_C000F0B "The message checksum is used to verify the signal path from the transmitting device to the receiving device. Autosar Profile 2";
CM_ SG_ 2348814091 MessageCounter_C000F0B "The message counter is used to detect situations where the transmitting ECU malfunction repeats the same frame all the time.  The receiver of the information may use the counter parameter to detect this situation.";
CM_ SG_ 2348820747 EngOverrideCtrlMode "The override control mode defines which sort of command is used";
CM_ SG_ 2348820747 OverrideCtrlModePriority "This field is used as an input to the engine or retarder to determine the priority of the Override Control Mode received in the Torque/Speed Control message (see PGN 0).  The default is 11 (Low priority).";
CM_ SG_ 2348820747 EngRequestedTorque_TorqueLimit "Parameter provided to the engine or retarder in the torque/speed control message for controlling or limiting the output torque.";
CM_ SG_ 2348820747 MessageCounterJ1939_C00290B "The message counter is used to detect situations where the transmitting ECU malfunction repeats the same frame all the time.  The receiver of the information may use the counter parameter to detect this situation.";
CM_ SG_ 2348820747 MessageChecksumJ1939_C00290B "The message checksum is used to verify the signal path from the transmitting device to the receiving device.";
CM_ SG_ 2348820747 MessageChecksumAR2_C00290B "The message checksum is used to verify the signal path from the transmitting device to the receiving device. Autosar Profile 2";
CM_ SG_ 2348820747 MessageCounter_C00290B "The message counter is used to detect situations where the transmitting ECU malfunction repeats the same frame all the time.  The receiver of the information may use the counter parameter to detect this situation.";
CM_ SG_ 2566844672 ParkingBrakeSwitch "Switch signal which indicates when the parking brake is set.手刹开关状态";
CM_ SG_ 2566844672 WheelBasedVehicleSpeed "Speed of the vehicle as calculated from wheel or tailshaft speed.Invalid Value:0xFB00~ALLFF车速";
CM_ SG_ 2566844672 BrakeSwitch "Switch signal which indicates that the driver operated brake foot pedal is being pressed.制动开关状态";
CM_ SG_ 2566844672 ClutchSwitch "Switch signal which indicates that the clutch pedal is being pressed.离合开关状态";
CM_ SG_ 2566841088 EngReferenceTorque_ "This parameter is the 100% reference value for all defined indicated engine torque parameters.Invalid Value: 0xFB00~ALLFF发动机参考扭矩";
CM_ SG_ 2364539904 EngTorqueMode_ "State signal which indicates which engine torque mode is currently generating, limiting, or controlling the torque.发动机扭矩模式";
CM_ SG_ 2364539904 ActlEngPrcntTrqueHighResolution_ "This parameter displays an additional torque in percent of the reference engine torque.(实际扭矩百分比小数部分)";
CM_ SG_ 2364539904 DriversDemandEngPercentTorque "The requested torque output of the engine by the driver.驾驶指令扭矩百分比";
CM_ SG_ 2364539904 ActualEngPercentTorque_CF00400 "The calculated output torque of the engine.发动机实际扭矩百分比";
CM_ SG_ 2364539904 EngSpeed "Actual engine speed which is calculated over a minimum crankshaft angle of 720 degrees divided by the number of cylinders.Invalid Value: 0xFB00~ALLFF发动机转速";
CM_ SG_ 2364539648 AccelPedal1LowIdleSwitch_ "Switch signal which indicates the state of the accelerator pedal 1 low idle switch.";
CM_ SG_ 2364539648 AccelPedalKickdownSwitch "Switch signal which indicates whether the accelerator pedal kickdown switch is opened or closed.KD油门开关";
CM_ SG_ 2364539648 AccelPedalPos1_ "The ratio of actual position of the analog engine speed/torque request input device (such as an accelerator pedal or油门开度";
CM_ SG_ 2364539648 EngPercentLoadAtCurrentSpeed "The ratio of actual engine percent torque (indicated) to maximum indicated torque available at the current engine speed,当前转速下的负荷百分比";
CM_ SG_ 2364539648 ActualMaxAvailableEnginePercentTorque "This is the maximum amount of torque that the engine can immediately deliver as a percentage of the reference enginetorque (SPN 544).";
CM_ SG_ 2566840064 NominalFrictionPercentTorque_00 "The calculated torque that indicates the amount of torque required by the basic engine itself added by the loss torque of摩擦力扭矩百分比（对EBS科委专用）";
CM_ SG_ 2566840064 Estimated_Engine_Parasitic_Losses_Percent_Torque "估计的发动机或电机寄生损耗-扭矩百分比当该参数的数据值等于FB时，意味着发动机或电机计算的所有寄生损耗都包含在标称摩擦百分比扭矩（SPN 514）中。（科委专用）";
CM_ SG_ 2566843904 EngCoolantTemp "Temperature of liquid found in engine cooling system.";
CM_ SG_ 2566845952 EngIntakeManifold1Press "The gage pressure measurement of the air intake manifold. If there are multiple air pressure sensors in the intake stream, this is the last one in flow direction before entering the combustion chamber.";
CM_ SG_ 2365537280 MessageChecksumAR2_CFF3C00 "The message checksum is used to verify the signal path from the transmitting device to the receiving device. Autosar Profile 2";
CM_ SG_ 2365537280 MessageCounter_CFF3C00 "The message counter is used to detect situations where the transmitting ECU malfunction repeats the same frame all the time.  The receiver of the information may use the counter parameter to detect this situation.";
CM_ SG_ 2365537280 ActualEngPercentTorque "The calculated output torque of the engine.  The data is transmitted in indicated torque as a percent of reference engine torque (see the engine configuration message, PGN 65251).";
CM_ SG_ 2365537280 NominalFrictionPercentTorque "The calculated torque that indicates the amount of torque required by the basic engine itself added by the loss torque of accessories.";
CM_ SG_ 2364539395 TransDrivelineEngaged_CF00203 "Driveline engaged indicates the transmission controlled portion of the driveline is engaged sufficiently to allow a transfer变速箱在档";
CM_ SG_ 2364539395 TransShiftInProcess_CF00203 "Indicates that the transmission is in process of shifting from the current gear to the selected gear.正在换挡";
CM_ SG_ 2364539395 TransOutputShaftSpeed "Calculated speed of the transmission output shaft.Invalid Value:0xFB00~ALLFF输出轴转速";
CM_ SG_ 2364539395 PercentClutchSlip_CF00203 "Parameter which represents the ratio of input shaft speed to current engine speed (in percent).离合器滑移率";
CM_ SG_ 2364539395 TransInputShaftSpeed "Rotational velocity of the primary shaft transferring power into the transmission.Invalid Value:0xFB00~ALLFF";
CM_ SG_ 2565866755 TransSelectedGear "The gear that the transmission will attempt to achieve during the current shift if a shift is in progress, or the next shift if one目标档位";
CM_ SG_ 2565866755 TransActGearRatio "Actual ratio of input shaft speed to output shaft speed";
CM_ SG_ 2565866755 TransCurrentGear_18F00503 "The gear currently engaged in the transmission or the last gear engaged while the transmission is in the process of当前档位";
CM_ SG_ 2565866755 Transmission_Requested_Range_Axle2_RS "Range selected by the operator.  Characters may include P, Rx, Rx-1...R2, R1, R, Nx, Nx-1...N2, N1, N, D, D1, D2..., Dx, L, L1, L2..., Lx-1, 1, 2, 3,...  If only one displayed character is required, the second character shall be used and the first character shall be a space (ASCII 32) or a control character (ASCII 0 to 31).  If the first character is a control character, refer to the manufacturer's application document for definition.";
CM_ SG_ 2566801923 TransReadyForBrakeRelease_18FE4A03 "Thi s paramet er  indicat es t hat  enough  torque/ mot iveforce is avai lable at thetransmi ssion  out put  shaft  to  release  al lthe brakes wi thout a risk of  unintent ional movement  inthe  opposi te di rection.（ETC7只发此信号）";
CM_ SG_ 2364541955 TransTorqueConverterRatio "Ratio of the transmissions torque converter output torque to torque converter input torque at current speed. The ratio of 1.000 ( 03 E8 hex ) indicates torque converter lockup.";
CM_ SG_ 2566853635 MessageChecksumAR2_18FF1403 "The message checksum is used to verify the signal path from the transmitting device to the receiving device. Autosar Profile 2";
CM_ SG_ 2566853635 MessageCounter_18FF1403 "The message counter is used to detect situations where the transmitting ECU malfunction repeats the same frame all the time.  The receiver of the information may use the counter parameter to detect this situation.";
CM_ SG_ 2566853635 TransReadyForBrakeRelease "This parameter indicates that enough torque / motive force is available at the transmission output shaft to release all the brakes without a risk of unintentional movement in the opposite direction.";
CM_ SG_ 2566853635 TransCurrentGear "The gear currently engaged in the transmission or the last gear engaged while the transmission is in the process of shifting to the new or selected gear.  Transitions toward a destination gear will not be indicated.";
CM_ SG_ 2566853635 PercentClutchSlip "Parameter which represents the ratio of input shaft speed to current engine speed (in percent). Percent Clutch Slip = ((Engine rpm - Input shaft rpm)/(Engine rpm)) x 100";
CM_ SG_ 2566853635 TransShiftInProcess "Indicates that the transmission is in process of shifting from the current gear to the selected gear. This state is generally ACTIVE during the entire time that the transmission controls the vehicle during a shift.";
CM_ SG_ 2566853635 TransDrivelineEngaged "Driveline engaged indicates the transmission controlled portion of the driveline is engaged sufficiently to allow a transfer of torque through the transmission.  Driveline engaged is ACTIVE whenever the transmission is in gear with clutch closed";
CM_ SG_ 2566853635 TrnsTorqueConverterLockupEngaged "State signal which indicates whether the torque converter lockup is engaged.";
CM_ SG_ 2566853635 ActiveShiftConsoleIndicator "Signal from transmission control unit indicating which shift console (primary or secondary) it currently considers as the active shift selector input.";
CM_ SG_ 2565865739 AntiLockBrakingActive "State signal which indicates that the ABS is active.";
CM_ SG_ 2565865739 EBSBrakeSwitch_18F0010B "Switch signal which indicates that the brake pedal is being pressed.";
CM_ SG_ 2565865739 BrakePedalPos_18F0010B "Ratio of brake pedal position to maximum pedal position.";
CM_ SG_ 2565865739 ABSFullyOperational "Signal which indicates whether an ABS system is fully operational or whether its functionality is reduced by a defect or by";
CM_ SG_ 2566803211 ROPEngCtrlActive "State Signal which indicates that the Roll Over Prevention (ROP) has commanded engine control to be active.";
CM_ SG_ 2566803211 ROPBrakeCtrlActive "State signal which indicates that Roll over Prevention (ROP) has activated brake control.";
CM_ SG_ 2566803211 YCEngCtrlActive "State Signal which indicates that the Yaw Control (YC) has commanded engine control to be active.";
CM_ SG_ 2566803211 YCBrakeCtrlActive "State signal which indicates that Yaw Control (YC) has activated brake control.";
CM_ SG_ 2298375691 FrontAxleLeftWheelSpeed "High resolution measurement of the speed of the left wheel on the front axle.Invalid Value:0xFB00~ALLFF";
CM_ SG_ 2298375691 FrontAxleRightWheelSpeed "High resolution measurement of the speed of the right wheel on the front axle.Invalid Value:0xFB00~ALLFF";
CM_ SG_ 2298375691 RearAxleLeftWheelSpeed "High resolution measurement of the speed of the left wheel on the rear axle.Invalid Value:0xFB00~ALLFF";
CM_ SG_ 2298375691 RearAxleRightWheelSpeed "High resolution measurement of the speed of the right wheel on the rear axle.Invalid Value:0xFB00~ALLFF";
CM_ SG_ 2565867787 SteerWheelAngle_18F0090B "The main operator`s steering wheel angle (on the steering column, not the actual wheel angle).Invalid Value:0xFAFF~ALLFF";
CM_ SG_ 2565867787 SteerWheelTurnCounter "Indicates number of steering wheel turns, absolute position or relative position at ignition on.";
CM_ SG_ 2565867787 SteerWheelAngleSensorType "Indicates whether the steering wheel angle sensor is capable of absolute measuring of the number of steering wheel";
CM_ SG_ 2565867787 YawRate "Indicates the rotation about the vertical axis.Invalid Value:0xFAE2~ALLFF";
CM_ SG_ 2565867787 LateralAcceleration "Indicates a lateral acceleration of the vehicle.Invalid Value:0xFAE2~ALLFF";
CM_ SG_ 2565867787 LongitudinalAcceleration "Indicates the longitudinal acceleration of the vehicle.";
CM_ SG_ 2566831883 FrontAxleSpeed "The average speed of the two front wheels.Invalid Value:0xFB00~ALLFF";
CM_ SG_ 2566831883 RelativeSpeedFrontAxleLeftWheel "The speed of the front axle, left wheel relative to the front axle speed, SPN 904.";
CM_ SG_ 2566831883 RlativeSpeedFrontAxleRightWheel "The speed of the front axle, right wheel relative to the front axle speed, SPN 904.";
CM_ SG_ 2566831883 RelativeSpeedRearAxle1LeftWheel "The speed of the rear axle #1, left wheel relative to the front axle speed, SPN 904.";
CM_ SG_ 2566831883 RlativeSpeedRearAxle1RightWheel "The speed of the rear axle #1, right wheel relative to the front axle speed, SPN 904.";
CM_ SG_ 2566831883 RelativeSpeedRearAxle2LeftWheel "The speed of the rear axle #2, left wheel relative to the front axle speed, SPN 904.";
CM_ SG_ 2566831883 RlativeSpeedRearAxle2RightWheel "The speed of the rear axle #2, right wheel relative to the front axle speed, SPN 904.";
CM_ SG_ 2566827275 BrkAppPrssHghRngFrntAxlLftWheel "The brake application pressure for the left wheel on the front axle.";
CM_ SG_ 2566827275 BrkAppPrssHghRngFrntAxlRghtWhel "The brake application pressure for the right wheel on the front axle.";
CM_ SG_ 2566827275 BrkAppPrssHghRngRrAxl1LeftWheel "The brake application pressure for the left wheel on the rear axle #1.";
CM_ SG_ 2566827275 BrkAppPrssHghRngRrAxl1RghtWheel "The brake application pressure for the right wheel on the rear axle #1.";
CM_ SG_ 2566827275 BrkAppPrssHghRngRrAxl2LeftWheel "The brake application pressure for the left wheel on the rear axle #2.";
CM_ SG_ 2566827275 BrkAppPrssHghRngRrAxl2RghtWheel "The brake application pressure for the right wheel on the rear axle #2.";
CM_ SG_ 2566827275 BrkAppPrssHghRngRrAxl3LeftWheel "The brake application pressure for the left wheel on the rear axle #3.";
CM_ SG_ 2566827275 BrkAppPrssHghRngRrAxl3RghtWheel "The brake application pressure for the right wheel on the rear axle #3.";
CM_ SG_ 2566767627 HaltBrakeMode "Signal which indicates the current mode of the halt brake function.";
CM_ SG_ 2566767627 HillHolderMode "Signal which indicates the current mode of the hill holder function.";
CM_ SG_ 2566767627 FoundationBrakeUse "This parameter indicates if the brake system presently uses the foundation brakes.";
CM_ SG_ 2566767627 XBRSystemState "This parameter indicates which external brake control is allowed.";
CM_ SG_ 2566767627 XBRActiveCtrlMode "This parameter indicates which XBR Control Mode is executed by the brake system.";
CM_ SG_ 2566767627 XBRAccelerationLimit "The brake system may temporarily or generally limit the maximum brake performance available for external systems.";
CM_ SG_ 2566767627 PrkngBrkeActuatorFullyActivated "Signal which indicates when the parking brake actuator is fully activated.";
CM_ SG_ 2566767627 EmergencyBrakingActive "紧急制动（点制动灯）";
CM_ SG_ 2566847015 BrakePrimaryPress "Gage pressure of air in the primary, or supply side, of the air brake system.";
CM_ SG_ 2566847015 BrakeSecondPress "Gage pressure of air in the secondary, or service side, of the air brake system.";
CM_ SG_ 2565865767 ABSOffroadSwitch_18F00127 "Switch signal which indicates the position of the ABS off-road switch.";
CM_ SG_ 2565865767 ASROffroadSwitch_18F00127 "Switch signal which indicates the position of the ASR off-road switch.";
CM_ SG_ 2565865767 ASRHillHolderSwitch_18F00127 "Switch signal which indicates the position of the ASR Hill Holder switch";
CM_ SG_ 2565865767 HaltBrakeSwitch_18F00127 "Switch signal which indicates the position of the halt brake switch.";
CM_ SG_ 2565865767 TrctrMntdTrailerABSWarningSignal "This parameter commands the tractor-mounted trailer ABS optical warning signal.";
CM_ SG_ 2565865767 MessageChecksumAR2_18F00127 "The message checksum is used to verify the signal path from the transmitting device to the receiving device. Autosar Profile 2";
CM_ SG_ 2565865767 MessageCounter_18F00127 "The message counter is used to detect situations where the transmitting ECU malfunction repeats the same frame all the time.  The receiver of the information may use the counter parameter to detect this situation.";
CM_ SG_ 2565865511 DrvrsDemandRetarderPercentTorque "The requested torque for the retarder by the driver. This includes the torque requested due to activation of the retarder lever";
CM_ SG_ 2565865511 RetarderSelectionNonengine "Retarder Lever activation in percentage value";
CM_ SG_ 2565865511 MessageChecksumAR2_18F00027 "The message checksum is used to verify the signal path from the transmitting device to the receiving device. Autosar Profile 2";
CM_ SG_ 2565865511 MessageCounter_18F00027 "The message counter is used to detect situations where the transmitting ECU malfunction repeats the same frame all the time.  The receiver of the information may use the counter parameter to detect this situation.";
CM_ SG_ 2566857767 RetarderLeverState "A percentage value containing the current state of the retarder lever";
CM_ SG_ 2432593706 SpeedOfForwardVehicle "前车速";
CM_ SG_ 2432593706 Distanceofforwardvehicle "前车距离";
CM_ SG_ 2432593706 AdaptiveCruiseControlSetSpeed "自适应巡航设定车速";
CM_ SG_ 2432593706 AdaptiveCruiseControlMode "自适应巡航控制模式";
CM_ SG_ 2432593706 AdaptivecruisecontrolsetdistanceMode "自适应巡航设定距离模式";
CM_ SG_ 2432593706 ACCTargetDetected "检测到目标";
CM_ SG_ 2432593706 ACCSystemShutoffWarning "ACC系统关闭提示";
CM_ SG_ 2432593706 ACCDistanceAlertSignal "Signal to indicate to the operator that the ACC system is not able to maintain the distance to the target. Example: Target stopping rapidly. This signal may be used to activate warning sounds or indicators.ACC接管报警";
CM_ SG_ 2432593706 ForwardCollisionWarning "前向碰撞警告";
CM_ SG_ 2365479471 NominalLevelFrontAxle "Signal which indicates the nominal (desired) height of the front axle to be controlled by the suspension system.";
CM_ SG_ 2566842927 AxleLocation "To identify to which of axles the information applies.";
CM_ SG_ 2566909530 MessageChecksumAR2_18FFEE5A "The message checksum is used to verify the signal path from the transmitting device to the receiving device. Autosar Profile 2";
CM_ SG_ 2566909530 MessageCounter_18FFEE5A "The message counter is used to detect situations where the transmitting ECU malfunction repeats the same frame all the time.  The receiver of the information may use the counter parameter to detect this situation.";
CM_ SG_ 2566909530 GrossCombinationVehicleWeight "The total weight of the truck and all attached trailers.";
CM_ SG_ 2364551072 AdvancedemergencybrakingsystemstateAEBS1 "Advanced emergency braking system state系统当前状态";
CM_ SG_ 2364551072 Collision_warning_level "Collision warning level碰撞报警等级";
CM_ SG_ 2365484270 TachographVehicleSpeed "Speed of the vehicle registered by the tachograph.车速";
CM_ SG_ 2566832622 HighResolutionTotalVehicleDistance "Accumulated distance traveled by the vehicle during its operation.总里程";
CM_ SG_ 2566832622 HighResolutionTripDistance "Distance traveled during all or part of a journey.小计里程";
CM_ SG_ 2566841327 EngSpeedAtIdlePoint1_ "Stationary low idle speed of engine which includes influences due to engine temperature (after power up) and otherstationary changes (calibration offsets, sensor failures, etc). This parameter is point 1 of the engine configuration map(see PGN 65251).";
CM_ SG_ 2566841327 EM1ReferenceTorque_ "This parameter is the 100% reference value for all defined indicated motor torque parameters.Invalid Value: 0xFB00~ALLFF电机参考扭矩";
CM_ SG_ 2566840303 NominalFrictionPercentTorque_EF "The calculated torque that indicates the amount of torque required by the basic motor itself added by the loss torque of摩擦力扭矩百分比";
CM_ SG_ 2566840303 EstEM1PrsticLossesPercentTorque_ "The calculated torque that indicates the estimated amount of torque loss due to motor parasitics, such as cooling fan, air";
CM_ SG_ 2566856943 EM1TorqueModeDrivingBraking_ "State signal which indicates which motor torque mode is currently generating, limiting, or controlling the torque.电机扭矩模式";
CM_ SG_ 2566856943 ActualeEM1PercentTorque "The calculated output torque of the motor.电机实际扭矩百分比(VCU不发小数部分)";
CM_ SG_ 2566856943 EM1Speed "Actual motor speed which is calculated over a minimum crankshaft angle of 720 degrees divided by the number of cylinders.Invalid Value: 0xFB00~ALLFF电机输出轴转速";
CM_ SG_ 2566856943 EM1DriverRetarderPercentTorque "驾驶员请求的电机扭矩百分比";
CM_ SG_ 2566856943 SrcAddrssOfCtrllngDvcFrEM1Cntrl_ "The source address of the SAE J1939 device currently controlling the motor.";
CM_ SG_ 2566856943 EM1RetSelectionNonEng "驾驶员需求缓速器扭矩";
CM_ SG_ 2566856943 EM1ActualMaxAvailableRetPercentTorque "可提供的最大扭矩";
CM_ SG_ 2566840815 RetarderType_EF_ "A vehicle retarder is a supplementary device to the wheel brakes for the driver to better control the vehicle.";
CM_ SG_ 2566840815 RetarderLocation_EF "This parameter defines whether the 搕orque/speed curve?defined by the retarder configuration message (PGN 65249) is";
CM_ SG_ 2566840815 ReferenceRetarderTorque_EF "This parameter is the 100% reference value for all defined indicated retarder torque parameters.";
CM_ SG_ 2566701807 PropulsionSystemActive_Ready "Indicates when the hybrid system or electric vehicle system is ready to provide or is actively providing propulsion as defined in ARB regulation 13CCR1971.1, which includes the amendments up to the Board hearing date of August 2012. 上高压驾驶状态信号";
CM_ SG_ 2566842094 Seconds "The seconds component of the current time of day.";
CM_ SG_ 2566842094 Minutes "The minutes component of the current time of day.";
CM_ SG_ 2566842094 Hours "The hour component of the current time of day.";
CM_ SG_ 2566842094 Month "The month component of the current calendar date.";
CM_ SG_ 2566842094 Day "The day component of the current calendar date.";
CM_ SG_ 2566842094 Year "The year component of the current calendar date.";
CM_ SG_ 2566842094 LocalMinuteOffset "国内北京时间填充FA，海外填有效值";
CM_ SG_ 2566842094 LocalHourOffset "国内北京时间填充FA，海外填有效值";
CM_ SG_ 2431710879 ADAS_Posn_RelHead "Heading relative to link.";
CM_ SG_ 2431710879 ADAS_Posn_Confdc "Position confidence.";
CM_ SG_ 2431710879 ADAS_Posn_Age "Time difference between the moment the message is sent and the momentthe vehicle position is calculated by the positioning sub-system.0x0~0x1FD：消息发送时刻与定位子系统计算车辆位置之间的时间差为:0~2545 ms";
CM_ SG_ 2431710879 ADAS_Posn_PosProbb "Position Probability is calculated by Positioning module of ADASIS v2Horizon Provider. Different Av2HPs will use different algorithms to calculatethis value.";
CM_ SG_ 2431710879 ADAS_Posn_Idx "If Av2HP supports positioning alternatives, contains index of this PositionCandidate. Candidate 0 is always most probable position candidate,candidate 1 second etc.If Av2HP does not support positioning alternatives, it will be always 0.";
CM_ SG_ 2431710879 ADAS_Posn_PathIdx "Index of current path: If this number differs from the one transmitted in theprevious POSITION message with Position Index = 0, the vehicle has leftthe original path.";
CM_ SG_ 2431710879 ADAS_Posn_CycCnt "Cyclic counter of this message type: Reconstructor can use this value todetect missing messages.";
CM_ SG_ 2431710879 ADAS_Posn_Offset "Offset of current position from the current path’s start point.0x0~0x1FE：车辆位置的偏移范围0~8190m";
CM_ SG_ 2431710879 ADAS_Posn_MsgTyp "Message type";
CM_ SG_ 2498819743 ADAS_Stub_NumOfLaneDrvDir "Number of lanes in driving direction of new path.";
CM_ SG_ 2498819743 ADAS_Stub_NumOfLaneOppDir "Number of lanes in opposite direction on new path.";
CM_ SG_ 2498819743 ADAS_Stub_RtOfWay "Right of the way.";
CM_ SG_ 2498819743 ADAS_Stub_LastStub "Value true indicates that this STUB message is last one that refers to givenparent path and offset; value false says that more STUB messages for thisoffset on parent path will be sent.";
CM_ SG_ 2498819743 ADAS_Stub_TurnAngl "Angle of new path relative to parent path.";
CM_ SG_ 2498819743 ADAS_Stub_FormOfWay_ "Form of Way of new path";
CM_ SG_ 2498819743 ADAS_Stub_CmplxInsct "Complex intersection is defined by the GDF level 2 complex feature“Intersection” containing more than one junction and/or road element.“Complex intersection“ shall be set when the vehicle drives on roadelements with source node and target node belonging to the same complexfeature (“plural junction” with “intersection internal“ road elements)";
CM_ SG_ 2498819743 ADAS_Stub_PartOfCalcRoute "Whether new path from this point on is part of Calculated Route";
CM_ SG_ 2498819743 ADAS_Stub_FuncRoadClass "Functional Road Class of new path indicates relative importance of the road in the routing network and lower values indicate higher priority. This information is usually map-provider specific";
CM_ SG_ 2498819743 ADAS_Stub_RelProbb "Relative probability of the new path on the crossing; sum of all relative stubprobabilities (including continuation stub with sub-path index of 6) is 100percent";
CM_ SG_ 2498819743 ADAS_Stub_Update "Value true indicates that this message contains update.";
CM_ SG_ 2498819743 ADAS_Stub_Retr "Whether this message has been sent at least once before.";
CM_ SG_ 2498819743 ADAS_Stub_SubPathIdx "This is Index of new path.";
CM_ SG_ 2498819743 ADAS_Stub_PathIdx "Index of current path";
CM_ SG_ 2498819743 ADAS_Stub_CycCnt "Cyclic counter of this message type: Reconstructor can use this value to detect missing messages.";
CM_ SG_ 2498819743 ADAS_Stub_Offset "Offset of the position of the crossing from the start path position0x0~0x1FE：0~8190m，岔路口位置与路径起点的距离对8191取余";
CM_ SG_ 2498819743 ADAS_Stub_MsgType "Message type";
CM_ SG_ 2565928863 ADAS_ProfShort_Value1 "Profile value at Offset+Distance1";
CM_ SG_ 2565928863 ADAS_ProfShort_Value0 "Profile value at Offset";
CM_ SG_ 2565928863 ADAS_ProfShort_Dist1 "Distance from first profile spot to the second one.0x0~0x3FE：0~1022m，第一个行点到第二个行点的距离，不超过1023";
CM_ SG_ 2565928863 ADAS_ProfShort_AccurClass "Accuracy of profile value is implementation specific.";
CM_ SG_ 2565928863 ADAS_ProfShort_Update "Value true indicates that this message contains updated information ofalready transmitted PROFILE SHORT.";
CM_ SG_ 2565928863 ADAS_ProfShort_Retr "If true, this message was sent already at least once before.";
CM_ SG_ 2565928863 ADAS_ProfShort_CtrlPoint "If true, values in this message specifies additional control points required forthe interpolation of this profile.";
CM_ SG_ 2565928863 ADAS_ProfShort_ProfType "Profile Type";
CM_ SG_ 2565928863 ADAS_ProfShort_PathIdx "Index of current path: If this number differs from the one transmitted in theprevious POSITION message with Position Index = 0, the vehicle has leftthe original path;";
CM_ SG_ 2565928863 ADAS_ProfShort_CycCnt "Cyclic counter of this message type: Reconstructor can use this value to detect missing messages.";
CM_ SG_ 2565928863 ADAS_ProfShort_Offset "Offset of current position from the current path’s start point.0x0~0x1FE：0~8190m，该消息与路径起点的距离对8191取余";
CM_ SG_ 2565928863 ADAS_ProfShort_MsgTyp "Message type";
CM_ SG_ 2565929119 ProfileLong_Value "Profile value at Offset, a special value (usually 232 -1) signals an invalid, unknown or N/A value.";
CM_ SG_ 2565929119 ADAS_ProfLong_CycCnt "Cyclic counter of this message type and profile type: Reconstructor can use this value to detect missing messages.";
CM_ SG_ 2565929119 ADAS_ProfLong_Offset "0x0~0x1FE：0~8190m，该消息与路径起点的距离对8191取余";
CM_ SG_ 2565928607 ADAS_Seg_NumOfLaneDrvDir "Number of lanes in driving direction: also implies driving direction.  0 denotes one-direction road driven in wrong direction, 1-5 are verbatim values, and 6 indicate 6 or more lanes. Value 7 means N/A.";
CM_ SG_ 2565928607 ADAS_Seg_DividedRoad "0: Segment is not part of a divided road/dual carriageway. 1: Segment is part of a divided road/dual carriageway. 2: Unknown 3: N/A";
CM_ SG_ 2565928607 ADAS_Seg_Offset "0x0~0x1FE：0~8190m，该segment路段与路径起点的距离对8191取余";
CM_ SG_ 2633037471 ADAS_Meta_MapVerQtr "Content of this field is Year quarter of release of map of current area.   For example, NAVTEQ Q4/2007 map will be described as      MAP PROVIDER = 1       MAP VERSION (Y) = 7       MAP VERSION (Q) = 3 Please note if the whole map may be partitioned into parts that can be released on different times or even by different providers. In that case, value if this field may vary between messages.";
CM_ SG_ 2633037471 ADAS_Meta_RegionCode "0x0~0x7FFE：区域代码";
CM_ SG_ 2633037471 ADAS_Meta_HWVer "0x1~0x1FF：提供商的硬件和/或软件版本（取决于公司特定的编号方案）";
CM_ SG_ 2633037471 ADAS_Meta_CountryCode "0x0~0x3FF：国家代码，ISO 3166-1数字指定的有效值";
CM_ SG_ 2565799839 IdentityNumber "固定值：0xE2370";
CM_ SG_ 2565799839 ManufacturerCode "固定值：0x36E";
CM_ SG_ 2565799839 ECUInstance "固定值：0x0";
CM_ SG_ 2565799839 FunctionInstance "固定值：0x0";
CM_ SG_ 2565799839 Function "固定值：0x89";
CM_ SG_ 2565799839 VehicleSystem "固定值：0x0";
CM_ SG_ 2565799839 VehicleSystemInstance_ "固定值：0x0";
CM_ SG_ 2565799839 IndustryGroup "固定值：0x1";
CM_ SG_ 2565799839 ArbitraryAddressCapable_ "固定值：0x0";
CM_ SG_ 2566845343 Latitude "Latitude position of the vehicle._VehiclePosition";
CM_ SG_ 2566845343 Longitude "Longitude position of the vehicle._VehiclePosition";
CM_ SG_ 2566842527 Navigation_BasedVehicleSpeed "Speed of the vehicle as calculated from a device such as a Global Positioning System (GPS).";
CM_ SG_ 2566842527 Altitude "Altitude of the vehicle referenced to sea level at standard atmospheric pressure and temperature.";
CM_ SG_ 2633037727 ADASProfileShortSlope "Profile slope value";
CM_ SG_ 2566869400 ADB_Left_Switch_State "左侧大灯开启或关闭状态";
CM_ SG_ 2566869400 ADB_Left_MAX_State "左侧大灯最高亮度状态";
CM_ SG_ 2566869400 ADB_Left_Bent_State "左侧大灯转弯状态";
CM_ SG_ 2566869400 ADB_Left_Lamp_Fault "左侧大灯灯光源故障";
CM_ SG_ 2566869400 ADB_Left_Power_Fault "左侧大灯电源故障";
CM_ SG_ 2566869400 ADB_Left_CAN_Fault "左侧大灯CAN通讯故障";
CM_ SG_ 2566869400 ADB_Left_HiBeamSt "左前远光灯状态";
CM_ SG_ 2566869400 ADB_Left_HbWngSt "左前远光灯故障状态";
CM_ SG_ 2566869400 ADB_L_SwitchSet_Sts "ABD开关设置状态反馈";
CM_ SG_ 2566869657 ADB_Right_Switch_State "右侧大灯开启或关闭状态";
CM_ SG_ 2566869657 ADB_Right_MAX_State "右侧大灯最高亮度状态";
CM_ SG_ 2566869657 ADB_Right_Bent_State "右侧大灯转弯状态";
CM_ SG_ 2566869657 ADB_Right_Lamp_Fault "右侧大灯灯光源故障";
CM_ SG_ 2566869657 ADB_Right_Power_Fault "右侧大灯电源故障";
CM_ SG_ 2566869657 ADB_Right_CAN_Fault "右侧大灯CAN通讯故障";
CM_ SG_ 2566869657 ADB_Right_HiBeamSt "右前远光灯状态";
CM_ SG_ 2566869657 ADB_Right_HbWngSt "右前远光灯故障状态";
CM_ SG_ 2566869657 ADB_R_SwitchSet_Sts "ABD开关设置状态反馈";
CM_ SG_ 2566893400 EAC1_CmpsrOpVol "空调压缩机工作电压";
CM_ SG_ 2566893400 EAC1_CmpsrOpCrnt "空调压缩机工作电流";
CM_ SG_ 2566893400 EAC1_CmpsrOpSpd "空调压缩机转速";
CM_ SG_ 2566893400 EAC1_CmpsrOpTmp "空调压缩机温度";
CM_ SG_ 2566893400 EAC1_CmpsrSts "空调压缩机工作状态";
CM_ SG_ 2566893400 EAC1_UndrVFlt "压缩机欠压故障";
CM_ SG_ 2566893400 EAC1_OvrCrntFlt "压缩机过流故障";
CM_ SG_ 2566893400 EAC1_OvrCrntFey "过流降频";
CM_ SG_ 2566893400 EAC1_OvrTempFlt "压缩机过温故障";
CM_ SG_ 2566893400 EAC1_OvrTmpFey "过温降频";
CM_ SG_ 2566893400 EAC1_CompIntVolFlt "压缩机控制端电压故障";
CM_ SG_ 2566893400 EAC1_LstCommWithAC "与ECC/VDCU/TMU节点失去通讯";
CM_ SG_ 2566893400 EAS1_HVIL_Sts "预留。EAS互锁状态";
CM_ SG_ 2566893400 EAC1_OvrVolFlt "压缩机过压故障";
CM_ SG_ 2566893400 EAC1_PhaseCrnt "空调压缩机工作相电流";
CM_ SG_ 2566893400 EAC1_Power "压缩机功率";
BA_DEF_ BO_ "GenMsgSendType" ENUM "Cycle","NoMsgSendType","IfActive","Event","CA","CE";
BA_DEF_ BO_ "GenMsgNrOfRepetition" INT 0 0;
BA_DEF_ BO_ "GenMsgILSupport" ENUM "No","Yes";
BA_DEF_ BO_ "GenMsgDelayTime" INT 0 0;
BA_DEF_ BO_ "GenMsgCycleTimeFast" INT 0 0;
BA_DEF_ BO_ "GenMsgCycleTime" INT 0 0;
BA_DEF_ BO_ "NmMessage" ENUM "No","Yes";
BA_DEF_ BO_ "VFrameFormat" ENUM "StandardCAN","ExtendedCAN","reserved","J1939PG";
BA_DEF_ BO_ "J1939CPgTOS" INT 0 7;
BA_DEF_ BO_ "J1939CPgSendTimeout" INT -1 3600000;
BA_DEF_ BO_ "J1939PgAppearanceOnBus" ENUM "Default","CAN_Extended","CANFD_Extended";
BA_DEF_ BO_ "GenMsgRequestable" INT 0 1;
BA_DEF_ SG_ "GenSigInvalidValue" HEX 0 0;
BA_DEF_ SG_ "GenSigStartValue" HEX 0 0;
BA_DEF_ SG_ "GenSigInactiveValue" HEX 0 0;
BA_DEF_ SG_ "GenSigSendType" ENUM "Cycle","OnWrite","OnWriteWithRepetition","OnChange","OnChangeWithRepetition","IfActive","IfActiveWithRepetition","NoSigSendType","vector_leerstring";
BA_DEF_ SG_ "SPN" INT 0 0;
BA_DEF_ SG_ "ASIL" STRING ;
BA_DEF_ SG_ "SigType" ENUM "Default","Range","RangeSigned","ASCII","Discrete","Control","ReferencePGN","DTC","StringDelimiter","StringLength","StringLengthControl","MessageCounter","MessageChecksum";
BA_DEF_ SG_ "GenSigILSupport" ENUM "No","Yes";
BA_DEF_ SG_ "GenSigEVName" STRING ;
BA_DEF_DEF_ "GenMsgSendType" "Cycle";
BA_DEF_DEF_ "GenMsgNrOfRepetition" 0;
BA_DEF_DEF_ "GenMsgILSupport" "Yes";
BA_DEF_DEF_ "GenMsgDelayTime" 0;
BA_DEF_DEF_ "GenMsgCycleTimeFast" 0;
BA_DEF_DEF_ "GenMsgCycleTime" 100;
BA_DEF_DEF_ "NmMessage" "No";
BA_DEF_DEF_ "VFrameFormat" "StandardCAN";
BA_DEF_DEF_ "J1939CPgTOS" 2;
BA_DEF_DEF_ "J1939CPgSendTimeout" -1;
BA_DEF_DEF_ "J1939PgAppearanceOnBus" "Default";
BA_DEF_DEF_ "GenMsgRequestable" 1;
BA_DEF_DEF_ "GenSigInvalidValue" 0;
BA_DEF_DEF_ "GenSigStartValue" 0;
BA_DEF_DEF_ "GenSigInactiveValue" 0;
BA_DEF_DEF_ "GenSigSendType" "Cycle";
BA_DEF_DEF_ "SPN" 0;
BA_DEF_DEF_ "ASIL" "";
BA_DEF_DEF_ "SigType" "Default";
BA_DEF_DEF_ "GenSigILSupport" "Yes";
BA_DEF_DEF_ "GenSigEVName" "Env@Nodename_@Signame";
BA_ "GenMsgCycleTime" BO_ 2348810282 200;
BA_ "GenMsgCycleTimeFast" BO_ 2348810282 20;
BA_ "GenMsgSendType" BO_ 2348810282 4;
BA_ "VFrameFormat" BO_ 2348810282 3;
BA_ "VFrameFormat" BO_ 2349465642 3;
BA_ "GenMsgCycleTime" BO_ 2566859752 50;
BA_ "VFrameFormat" BO_ 2566859752 3;
BA_ "VFrameFormat" BO_ 2565865808 3;
BA_ "VFrameFormat" BO_ 2566787664 3;
BA_ "GenMsgCycleTime" BO_ 2365562448 20;
BA_ "VFrameFormat" BO_ 2365562448 3;
BA_ "GenMsgCycleTime" BO_ 2566847056 1000;
BA_ "VFrameFormat" BO_ 2566847056 3;
BA_ "GenMsgCycleTime" BO_ 2566911764 10;
BA_ "VFrameFormat" BO_ 2566911764 3;
BA_ "GenMsgCycleTime" BO_ 2566897256 500;
BA_ "VFrameFormat" BO_ 2566897256 3;
BA_ "GenMsgCycleTime" BO_ 2566897283 500;
BA_ "VFrameFormat" BO_ 2566897283 3;
BA_ "GenMsgCycleTime" BO_ 2566897284 500;
BA_ "VFrameFormat" BO_ 2566897284 3;
BA_ "GenMsgCycleTimeFast" BO_ 2348810251 10;
BA_ "GenMsgSendType" BO_ 2348810251 4;
BA_ "VFrameFormat" BO_ 2348810251 3;
BA_ "VFrameFormat" BO_ 2565865487 3;
BA_ "VFrameFormat" BO_ 2566840591 3;
BA_ "VFrameFormat" BO_ 2565865488 3;
BA_ "GenMsgCycleTime" BO_ 2566840592 5000;
BA_ "VFrameFormat" BO_ 2566840592 3;
BA_ "VFrameFormat" BO_ 2565865513 3;
BA_ "VFrameFormat" BO_ 2566840617 3;
BA_ "VFrameFormat" BO_ 2348814091 3;
BA_ "GenMsgCycleTime" BO_ 2348814347 50;
BA_ "GenMsgCycleTimeFast" BO_ 2348814347 50;
BA_ "VFrameFormat" BO_ 2348814347 3;
BA_ "VFrameFormat" BO_ 2348820747 3;
BA_ "VFrameFormat" BO_ 2566844672 3;
BA_ "GenMsgCycleTime" BO_ 2566841088 5000;
BA_ "VFrameFormat" BO_ 2566841088 3;
BA_ "GenMsgCycleTime" BO_ 2364539904 20;
BA_ "VFrameFormat" BO_ 2364539904 3;
BA_ "GenMsgCycleTime" BO_ 2364539648 20;
BA_ "VFrameFormat" BO_ 2364539648 3;
BA_ "GenMsgCycleTime" BO_ 2566840064 250;
BA_ "VFrameFormat" BO_ 2566840064 3;
BA_ "VFrameFormat" BO_ 2566843904 3;
BA_ "VFrameFormat" BO_ 2566845952 3;
BA_ "GenMsgDelayTime" BO_ 2365537280 5;
BA_ "VFrameFormat" BO_ 2365537280 3;
BA_ "GenMsgCycleTime" BO_ 2364539395 10;
BA_ "VFrameFormat" BO_ 2364539395 3;
BA_ "VFrameFormat" BO_ 2565866755 3;
BA_ "VFrameFormat" BO_ 2566801923 3;
BA_ "VFrameFormat" BO_ 2364541955 3;
BA_ "VFrameFormat" BO_ 2566853635 3;
BA_ "VFrameFormat" BO_ 2565865739 3;
BA_ "VFrameFormat" BO_ 2566803211 3;
BA_ "GenMsgCycleTime" BO_ 2298375691 20;
BA_ "VFrameFormat" BO_ 2298375691 3;
BA_ "GenMsgCycleTime" BO_ 2565867787 10;
BA_ "VFrameFormat" BO_ 2565867787 3;
BA_ "GenMsgCycleTime" BO_ 2566831883 50;
BA_ "VFrameFormat" BO_ 2566831883 3;
BA_ "VFrameFormat" BO_ 2566827275 3;
BA_ "VFrameFormat" BO_ 2566767627 3;
BA_ "VFrameFormat" BO_ 2566847015 3;
BA_ "VFrameFormat" BO_ 2565865767 3;
BA_ "VFrameFormat" BO_ 2565865511 3;
BA_ "VFrameFormat" BO_ 2566857767 3;
BA_ "VFrameFormat" BO_ 2432593706 3;
BA_ "VFrameFormat" BO_ 2365479471 3;
BA_ "VFrameFormat" BO_ 2566842927 3;
BA_ "VFrameFormat" BO_ 2566909530 3;
BA_ "GenMsgCycleTime" BO_ 2364551072 50;
BA_ "VFrameFormat" BO_ 2364551072 3;
BA_ "GenMsgCycleTime" BO_ 2365484270 50;
BA_ "VFrameFormat" BO_ 2365484270 3;
BA_ "GenMsgCycleTime" BO_ 2566832622 1000;
BA_ "VFrameFormat" BO_ 2566832622 3;
BA_ "GenMsgCycleTime" BO_ 2566841327 5000;
BA_ "VFrameFormat" BO_ 2566841327 3;
BA_ "GenMsgCycleTime" BO_ 2566840303 250;
BA_ "VFrameFormat" BO_ 2566840303 3;
BA_ "GenMsgCycleTime" BO_ 2566856943 10;
BA_ "VFrameFormat" BO_ 2566856943 3;
BA_ "GenMsgCycleTime" BO_ 2566840815 250;
BA_ "VFrameFormat" BO_ 2566840815 3;
BA_ "VFrameFormat" BO_ 2566701807 3;
BA_ "GenMsgCycleTime" BO_ 2566842094 1000;
BA_ "VFrameFormat" BO_ 2566842094 3;
BA_ "GenMsgCycleTime" BO_ 2431710879 1000;
BA_ "VFrameFormat" BO_ 2431710879 3;
BA_ "GenMsgSendType" BO_ 2498819743 2;
BA_ "VFrameFormat" BO_ 2498819743 3;
BA_ "GenMsgSendType" BO_ 2565928863 2;
BA_ "VFrameFormat" BO_ 2565928863 3;
BA_ "GenMsgSendType" BO_ 2565929119 2;
BA_ "VFrameFormat" BO_ 2565929119 3;
BA_ "GenMsgSendType" BO_ 2565928607 2;
BA_ "VFrameFormat" BO_ 2565928607 3;
BA_ "GenMsgCycleTime" BO_ 2633037471 5000;
BA_ "VFrameFormat" BO_ 2633037471 3;
BA_ "GenMsgCycleTime" BO_ 2565799839 1000;
BA_ "VFrameFormat" BO_ 2565799839 3;
BA_ "GenMsgCycleTime" BO_ 2566845343 5000;
BA_ "VFrameFormat" BO_ 2566845343 3;
BA_ "GenMsgCycleTime" BO_ 2566842527 5000;
BA_ "VFrameFormat" BO_ 2566842527 3;
BA_ "GenMsgCycleTime" BO_ 2633037727 5000;
BA_ "VFrameFormat" BO_ 2633037727 3;
BA_ "GenMsgCycleTime" BO_ 2566869400 50;
BA_ "VFrameFormat" BO_ 2566869400 3;
BA_ "GenMsgCycleTime" BO_ 2566869657 50;
BA_ "VFrameFormat" BO_ 2566869657 3;
BA_ "GenMsgCycleTime" BO_ 2566893400 500;
BA_ "VFrameFormat" BO_ 2566893400 1;
BA_ "SPN" SG_ 2348810282 EngOverrideCtrlMode_C00002A 695;
BA_ "GenSigSendType" SG_ 2348810282 EngOverrideCtrlMode_C00002A 5;
BA_ "SPN" SG_ 2348810282 EngRqedSpeedCtrlConditions_C00002A 696;
BA_ "GenSigSendType" SG_ 2348810282 EngRqedSpeedCtrlConditions_C00002A 5;
BA_ "SPN" SG_ 2348810282 OverrideCtrlModePriority_C00002A 897;
BA_ "GenSigSendType" SG_ 2348810282 OverrideCtrlModePriority_C00002A 5;
BA_ "SPN" SG_ 2348810282 EngRqedSpeed_SpeedLimit_C00002A 898;
BA_ "GenSigSendType" SG_ 2348810282 EngRqedSpeed_SpeedLimit_C00002A 5;
BA_ "SPN" SG_ 2348810282 EngRqedTorque_TorqueLimit 518;
BA_ "GenSigSendType" SG_ 2348810282 EngRqedTorque_TorqueLimit 5;
BA_ "SPN" SG_ 2348810282 TransmissionRate_C00002A 3349;
BA_ "GenSigSendType" SG_ 2348810282 TransmissionRate_C00002A 5;
BA_ "SPN" SG_ 2348810282 ControlPurpose_C00002A 3350;
BA_ "GenSigSendType" SG_ 2348810282 ControlPurpose_C00002A 5;
BA_ "SPN" SG_ 2348810282 EngineRequestedTorqueHiRes_C00002A 4191;
BA_ "GenSigSendType" SG_ 2348810282 EngineRequestedTorqueHiRes_C00002A 5;
BA_ "SPN" SG_ 2348810282 MessageCounter_C00002A 4206;
BA_ "GenSigSendType" SG_ 2348810282 MessageCounter_C00002A 5;
BA_ "SPN" SG_ 2348810282 MessageChecksum_C00002A 4207;
BA_ "GenSigSendType" SG_ 2348810282 MessageChecksum_C00002A 5;
BA_ "SPN" SG_ 2349465642 CruiseControlPauseCommand 5605;
BA_ "SPN" SG_ 2566859752 LowBeamSwRq 2349;
BA_ "GenSigStartValue" SG_ 2566859752 LowBeamSwRq 3;
BA_ "SPN" SG_ 2566859752 HighBeamSwRq 2347;
BA_ "GenSigStartValue" SG_ 2566859752 HighBeamSwRq 3;
BA_ "SPN" SG_ 2565865808 HaltBrakeSwitchEPB 2911;
BA_ "GenSigStartValue" SG_ 2565865808 HaltBrakeSwitchEPB 3;
BA_ "ASIL" SG_ 2566787664 ErrCode "B";
BA_ "GenSigStartValue" SG_ 2566787664 EPB_BraSwitch 3;
BA_ "GenSigStartValue" SG_ 2566787664 ParkBtSwitch 3;
BA_ "GenSigStartValue" SG_ 2566787664 RelsBtSwitch 3;
BA_ "GenSigStartValue" SG_ 2566787664 AHBtSwitch 3;
BA_ "GenSigStartValue" SG_ 2566787664 IdepedtBtSwitch 3;
BA_ "GenSigStartValue" SG_ 2566787664 ForcTestBtSwitch 3;
BA_ "GenSigStartValue" SG_ 2566787664 SysStatus 3;
BA_ "SPN" SG_ 2566847056 BrakeAppPress 116;
BA_ "SPN" SG_ 2566911764 DriverInterventionStatus_S 879031;
BA_ "GenSigInactiveValue" SG_ 2566911764 DriverInterventionStatus_S 6;
BA_ "GenSigStartValue" SG_ 2566897256 WPTC1_SoftwareVersion 1;
BA_ "GenSigStartValue" SG_ 2566897283 WPTC2_SoftwareVersion 1;
BA_ "GenSigStartValue" SG_ 2566897284 WPTC3_SoftwareVersion 1;
BA_ "SPN" SG_ 2348810251 EngOverrideCtrlMode_C00000B 695;
BA_ "SPN" SG_ 2348810251 EngRequestedSpeedCtrlConditions_C00000B 696;
BA_ "GenSigStartValue" SG_ 2348810251 EngRequestedSpeedCtrlConditions_C00000B 3;
BA_ "SPN" SG_ 2348810251 OverrideCtrlModePriority_C00000B 897;
BA_ "GenSigStartValue" SG_ 2348810251 OverrideCtrlModePriority_C00000B 3;
BA_ "SPN" SG_ 2348810251 EngRequestedTorque_TorqueLimit_C00000B 518;
BA_ "GenSigStartValue" SG_ 2348810251 EngRequestedTorque_TorqueLimit_C00000B 255;
BA_ "SPN" SG_ 2348810251 MessageCounter_C00000B 4206;
BA_ "GenSigStartValue" SG_ 2348810251 MessageCounter_C00000B 15;
BA_ "SPN" SG_ 2348810251 MessageChecksum_C00000B 4207;
BA_ "GenSigStartValue" SG_ 2348810251 MessageChecksum_C00000B 15;
BA_ "GenSigStartValue" SG_ 2565865487 ActualRetarderPercentTorque_18F0000F 255;
BA_ "GenSigStartValue" SG_ 2565865487 DrvrsDemandRetarderPercentTorque_18F0000F 255;
BA_ "GenSigStartValue" SG_ 2565865487 ActlMxAvlblRetarderPercentTorque_18F0000F 255;
BA_ "GenSigStartValue" SG_ 2566840591 ReferenceRetarderTorque_18FEE10F 65535;
BA_ "SPN" SG_ 2565865488 ActualRetarderPercentTorque_1 520;
BA_ "SPN" SG_ 2565865488 RetarderRqingBrakeLight 1667;
BA_ "GenSigStartValue" SG_ 2565865488 RetarderRqingBrakeLight 3;
BA_ "SPN" SG_ 2565865488 DriversDemandRetarderPercentTorque 1715;
BA_ "SPN" SG_ 2565865488 ActlMxAvlblRtarderPercentTorque_ 1717;
BA_ "SPN" SG_ 2566840592 RetarderType_10 901;
BA_ "SPN" SG_ 2566840592 RetarderLocation_10 902;
BA_ "SPN" SG_ 2566840592 ReferenceRetarderTorque_10 556;
BA_ "GenSigStartValue" SG_ 2565865513 RetarderTorqueMode 15;
BA_ "GenSigStartValue" SG_ 2565865513 ActualRetarderPercentTorque 255;
BA_ "GenSigStartValue" SG_ 2565865513 DrvrsDemandRetarderPercentTorque_18F00029 255;
BA_ "GenSigStartValue" SG_ 2565865513 ActlMxAvlblRetarderPercentTorque 255;
BA_ "GenSigStartValue" SG_ 2566840617 ReferenceRetarderTorque 65535;
BA_ "GenSigStartValue" SG_ 2348814091 EngRequestedTorque_TorqueLimit_C000F0B 255;
BA_ "SPN" SG_ 2348814347 EngOverrideCtrlMode_C00100B 695;
BA_ "SPN" SG_ 2348814347 EngRequestedSpeedCtrlConditions_C00100B 696;
BA_ "GenSigStartValue" SG_ 2348814347 EngRequestedSpeedCtrlConditions_C00100B 3;
BA_ "SPN" SG_ 2348814347 OverrideCtrlModePriority_C00100B 897;
BA_ "GenSigStartValue" SG_ 2348814347 OverrideCtrlModePriority_C00100B 3;
BA_ "SPN" SG_ 2348814347 EngRequestedSpeed_SpeedLimit_C00100B 898;
BA_ "GenSigStartValue" SG_ 2348814347 EngRequestedSpeed_SpeedLimit_C00100B 65535;
BA_ "SPN" SG_ 2348814347 EngRequestedTorque_TorqueLimit_C00100B 518;
BA_ "GenSigStartValue" SG_ 2348814347 EngRequestedTorque_TorqueLimit_C00100B 255;
BA_ "SPN" SG_ 2348814347 TSC1TransRate_C00100B 3349;
BA_ "GenSigStartValue" SG_ 2348814347 TSC1TransRate_C00100B 7;
BA_ "SPN" SG_ 2348814347 TSC1CtrlPurpose_C00100B 3350;
BA_ "GenSigStartValue" SG_ 2348814347 TSC1CtrlPurpose_C00100B 31;
BA_ "SPN" SG_ 2348814347 EngRequestedTorqueHighResolution_C00100B 4191;
BA_ "GenSigStartValue" SG_ 2348814347 EngRequestedTorqueHighResolution_C00100B 15;
BA_ "SPN" SG_ 2348814347 MessageCounter_C00100B 4206;
BA_ "GenSigStartValue" SG_ 2348814347 MessageCounter_C00100B 15;
BA_ "SPN" SG_ 2348814347 MessageChecksum_C00100B 4207;
BA_ "GenSigStartValue" SG_ 2348814347 MessageChecksum_C00100B 15;
BA_ "GenSigStartValue" SG_ 2348820747 EngRequestedTorque_TorqueLimit 255;
BA_ "SPN" SG_ 2566844672 ParkingBrakeSwitch 70;
BA_ "GenSigStartValue" SG_ 2566844672 ParkingBrakeSwitch 3;
BA_ "SPN" SG_ 2566844672 WheelBasedVehicleSpeed 84;
BA_ "SPN" SG_ 2566844672 BrakeSwitch 597;
BA_ "GenSigStartValue" SG_ 2566844672 BrakeSwitch 3;
BA_ "SPN" SG_ 2566844672 ClutchSwitch 598;
BA_ "GenSigStartValue" SG_ 2566844672 ClutchSwitch 3;
BA_ "SPN" SG_ 2566841088 EngReferenceTorque_ 544;
BA_ "SPN" SG_ 2364539904 EngTorqueMode_ 899;
BA_ "SPN" SG_ 2364539904 ActlEngPrcntTrqueHighResolution_ 4154;
BA_ "SPN" SG_ 2364539904 DriversDemandEngPercentTorque 512;
BA_ "SPN" SG_ 2364539904 ActualEngPercentTorque_CF00400 513;
BA_ "SPN" SG_ 2364539904 EngSpeed 190;
BA_ "SPN" SG_ 2364539648 AccelPedal1LowIdleSwitch_ 558;
BA_ "GenSigStartValue" SG_ 2364539648 AccelPedal1LowIdleSwitch_ 3;
BA_ "SPN" SG_ 2364539648 AccelPedalKickdownSwitch 559;
BA_ "GenSigStartValue" SG_ 2364539648 AccelPedalKickdownSwitch 3;
BA_ "SPN" SG_ 2364539648 AccelPedalPos1_ 91;
BA_ "ASIL" SG_ 2364539648 AccelPedalPos1_ "B";
BA_ "SPN" SG_ 2364539648 EngPercentLoadAtCurrentSpeed 92;
BA_ "SPN" SG_ 2364539648 ActualMaxAvailableEnginePercentTorque 3357;
BA_ "SPN" SG_ 2566840064 NominalFrictionPercentTorque_00 514;
BA_ "SPN" SG_ 2566840064 Estimated_Engine_Parasitic_Losses_Percent_Torque 2978;
BA_ "GenSigStartValue" SG_ 2566840064 Estimated_Engine_Parasitic_Losses_Percent_Torque 251;
BA_ "GenSigStartValue" SG_ 2566843904 EngCoolantTemp 255;
BA_ "GenSigStartValue" SG_ 2566845952 EngIntakeManifold1Press 255;
BA_ "SPN" SG_ 2365537280 ActualEngPercentTorque 513;
BA_ "GenSigStartValue" SG_ 2365537280 ActualEngPercentTorque 255;
BA_ "SPN" SG_ 2365537280 NominalFrictionPercentTorque 514;
BA_ "GenSigStartValue" SG_ 2365537280 NominalFrictionPercentTorque 255;
BA_ "SPN" SG_ 2364539395 TransDrivelineEngaged_CF00203 560;
BA_ "GenSigStartValue" SG_ 2364539395 TransDrivelineEngaged_CF00203 3;
BA_ "SPN" SG_ 2364539395 TransShiftInProcess_CF00203 574;
BA_ "GenSigStartValue" SG_ 2364539395 TransShiftInProcess_CF00203 3;
BA_ "SPN" SG_ 2364539395 TransInputShaftSpeed 161;
BA_ "SPN" SG_ 2565866755 TransSelectedGear 524;
BA_ "SPN" SG_ 2565866755 TransActGearRatio 526;
BA_ "SPN" SG_ 2565866755 TransCurrentGear_18F00503 523;
BA_ "ASIL" SG_ 2565866755 TransCurrentGear_18F00503 "A";
BA_ "SPN" SG_ 2565866755 Transmission_Requested_Range_Axle2_RS 162;
BA_ "SPN" SG_ 2566801923 TransReadyForBrakeRelease_18FE4A03 3086;
BA_ "GenSigStartValue" SG_ 2566801923 TransReadyForBrakeRelease_18FE4A03 3;
BA_ "GenSigStartValue" SG_ 2364541955 TransTorqueConverterRatio 65535;
BA_ "GenSigStartValue" SG_ 2566853635 TransReadyForBrakeRelease 3;
BA_ "GenSigStartValue" SG_ 2566853635 TransCurrentGear 255;
BA_ "GenSigStartValue" SG_ 2566853635 PercentClutchSlip 255;
BA_ "GenSigStartValue" SG_ 2566853635 TransShiftInProcess 3;
BA_ "GenSigStartValue" SG_ 2566853635 TransDrivelineEngaged 3;
BA_ "GenSigStartValue" SG_ 2566853635 TrnsTorqueConverterLockupEngaged 3;
BA_ "GenSigStartValue" SG_ 2566853635 ActiveShiftConsoleIndicator 3;
BA_ "SPN" SG_ 2565865739 AntiLockBrakingActive 563;
BA_ "GenSigStartValue" SG_ 2565865739 AntiLockBrakingActive 3;
BA_ "SPN" SG_ 2565865739 EBSBrakeSwitch_18F0010B 1121;
BA_ "GenSigStartValue" SG_ 2565865739 EBSBrakeSwitch_18F0010B 3;
BA_ "SPN" SG_ 2565865739 BrakePedalPos_18F0010B 521;
BA_ "SPN" SG_ 2565865739 ABSFullyOperational 1243;
BA_ "GenSigStartValue" SG_ 2565865739 ABSFullyOperational 3;
BA_ "SPN" SG_ 2566803211 ROPEngCtrlActive 1816;
BA_ "GenSigStartValue" SG_ 2566803211 ROPEngCtrlActive 3;
BA_ "SPN" SG_ 2566803211 ROPBrakeCtrlActive 1818;
BA_ "GenSigStartValue" SG_ 2566803211 ROPBrakeCtrlActive 3;
BA_ "SPN" SG_ 2566803211 YCEngCtrlActive 1817;
BA_ "GenSigStartValue" SG_ 2566803211 YCEngCtrlActive 3;
BA_ "SPN" SG_ 2566803211 YCBrakeCtrlActive 1819;
BA_ "GenSigStartValue" SG_ 2566803211 YCBrakeCtrlActive 3;
BA_ "SPN" SG_ 2298375691 FrontAxleRightWheelSpeed 16;
BA_ "SPN" SG_ 2298375691 RearAxleLeftWheelSpeed 32;
BA_ "SPN" SG_ 2298375691 RearAxleRightWheelSpeed 48;
BA_ "SPN" SG_ 2565867787 SteerWheelAngle_18F0090B 1807;
BA_ "SPN" SG_ 2565867787 SteerWheelTurnCounter 1811;
BA_ "SPN" SG_ 2565867787 SteerWheelAngleSensorType 1812;
BA_ "GenSigStartValue" SG_ 2565867787 SteerWheelAngleSensorType 3;
BA_ "SPN" SG_ 2565867787 YawRate 1808;
BA_ "SPN" SG_ 2565867787 LateralAcceleration 1809;
BA_ "SPN" SG_ 2565867787 LongitudinalAcceleration 1810;
BA_ "SPN" SG_ 2566831883 FrontAxleSpeed 904;
BA_ "SPN" SG_ 2566831883 RelativeSpeedFrontAxleLeftWheel 905;
BA_ "SPN" SG_ 2566831883 RlativeSpeedFrontAxleRightWheel 906;
BA_ "SPN" SG_ 2566831883 RelativeSpeedRearAxle1LeftWheel 907;
BA_ "SPN" SG_ 2566831883 RlativeSpeedRearAxle1RightWheel 908;
BA_ "SPN" SG_ 2566831883 RelativeSpeedRearAxle2LeftWheel 909;
BA_ "SPN" SG_ 2566831883 RlativeSpeedRearAxle2RightWheel 910;
BA_ "SPN" SG_ 2566827275 BrkAppPrssHghRngFrntAxlLftWheel 1091;
BA_ "SPN" SG_ 2566827275 BrkAppPrssHghRngFrntAxlRghtWhel 1092;
BA_ "SPN" SG_ 2566827275 BrkAppPrssHghRngRrAxl1LeftWheel 1093;
BA_ "SPN" SG_ 2566827275 BrkAppPrssHghRngRrAxl1RghtWheel 1094;
BA_ "SPN" SG_ 2566827275 BrkAppPrssHghRngRrAxl2LeftWheel 1095;
BA_ "SPN" SG_ 2566827275 BrkAppPrssHghRngRrAxl2RghtWheel 1096;
BA_ "SPN" SG_ 2566827275 BrkAppPrssHghRngRrAxl3LeftWheel 1097;
BA_ "SPN" SG_ 2566827275 BrkAppPrssHghRngRrAxl3RghtWheel 1098;
BA_ "SPN" SG_ 2566767627 HaltBrakeMode 2913;
BA_ "GenSigStartValue" SG_ 2566767627 HaltBrakeMode 7;
BA_ "SPN" SG_ 2566767627 HillHolderMode 2912;
BA_ "GenSigStartValue" SG_ 2566767627 HillHolderMode 7;
BA_ "SPN" SG_ 2566767627 FoundationBrakeUse 2919;
BA_ "GenSigStartValue" SG_ 2566767627 FoundationBrakeUse 3;
BA_ "SPN" SG_ 2566767627 XBRSystemState 2917;
BA_ "GenSigStartValue" SG_ 2566767627 XBRSystemState 3;
BA_ "ASIL" SG_ 2566767627 XBRSystemState "B";
BA_ "SPN" SG_ 2566767627 XBRActiveCtrlMode 2918;
BA_ "GenSigStartValue" SG_ 2566767627 XBRActiveCtrlMode 7;
BA_ "ASIL" SG_ 2566767627 XBRActiveCtrlMode "B";
BA_ "SPN" SG_ 2566767627 XBRAccelerationLimit 2921;
BA_ "SPN" SG_ 2566767627 PrkngBrkeActuatorFullyActivated 5275;
BA_ "GenSigStartValue" SG_ 2566767627 PrkngBrkeActuatorFullyActivated 3;
BA_ "SPN" SG_ 2566767627 EmergencyBrakingActive 5847;
BA_ "GenSigStartValue" SG_ 2566767627 EmergencyBrakingActive 3;
BA_ "ASIL" SG_ 2566767627 EmergencyBrakingActive "B";
BA_ "GenSigStartValue" SG_ 2566847015 BrakePrimaryPress 255;
BA_ "GenSigStartValue" SG_ 2566847015 BrakeSecondPress 255;
BA_ "GenSigStartValue" SG_ 2565865767 ABSOffroadSwitch_18F00127 3;
BA_ "GenSigStartValue" SG_ 2565865767 ASROffroadSwitch_18F00127 3;
BA_ "GenSigStartValue" SG_ 2565865767 ASRHillHolderSwitch_18F00127 3;
BA_ "GenSigStartValue" SG_ 2565865767 EngRetarderSelection 255;
BA_ "GenSigStartValue" SG_ 2565865767 HaltBrakeSwitch_18F00127 3;
BA_ "GenSigStartValue" SG_ 2565865767 TrctrMntdTrailerABSWarningSignal 3;
BA_ "GenSigStartValue" SG_ 2565865511 DrvrsDemandRetarderPercentTorque 255;
BA_ "GenSigStartValue" SG_ 2565865511 RetarderSelectionNonengine 255;
BA_ "GenSigStartValue" SG_ 2566857767 RetarderLeverState 255;
BA_ "SPN" SG_ 2432593706 SpeedOfForwardVehicle 1586;
BA_ "SPN" SG_ 2432593706 Distanceofforwardvehicle 1587;
BA_ "SPN" SG_ 2432593706 AdaptiveCruiseControlSetSpeed 1588;
BA_ "SPN" SG_ 2432593706 AdaptiveCruiseControlMode 1590;
BA_ "SPN" SG_ 2432593706 AdaptivecruisecontrolsetdistanceMode 1589;
BA_ "SPN" SG_ 2432593706 ACCTargetDetected 1798;
BA_ "GenSigStartValue" SG_ 2432593706 ACCTargetDetected 3;
BA_ "SPN" SG_ 2432593706 ACCSystemShutoffWarning 1797;
BA_ "GenSigStartValue" SG_ 2432593706 ACCSystemShutoffWarning 3;
BA_ "SPN" SG_ 2432593706 ACCDistanceAlertSignal 1796;
BA_ "ASIL" SG_ 2432593706 ACCDistanceAlertSignal "B";
BA_ "SPN" SG_ 2432593706 ForwardCollisionWarning 5022;
BA_ "GenSigStartValue" SG_ 2432593706 ForwardCollisionWarning 3;
BA_ "SPN" SG_ 2365479471 NominalLevelFrontAxle 1734;
BA_ "GenSigInvalidValue" SG_ 2365479471 NominalLevelFrontAxle 14;
BA_ "GenSigStartValue" SG_ 2365479471 NominalLevelFrontAxle 15;
BA_ "SPN" SG_ 2566842927 AxleLocation 928;
BA_ "GenSigStartValue" SG_ 2566909530 GrossCombinationVehicleWeight 65535;
BA_ "GenSigStartValue" SG_ 2566909530 GrossCombVehWghtConfidence 255;
BA_ "SPN" SG_ 2364551072 AdvancedemergencybrakingsystemstateAEBS1 5676;
BA_ "GenSigInactiveValue" SG_ 2364551072 AdvancedemergencybrakingsystemstateAEBS1 14;
BA_ "SPN" SG_ 2364551072 Collision_warning_level 5677;
BA_ "GenSigInactiveValue" SG_ 2364551072 Collision_warning_level 14;
BA_ "SPN" SG_ 2365484270 TachographVehicleSpeed 1624;
BA_ "ASIL" SG_ 2365484270 TachographVehicleSpeed "A";
BA_ "SPN" SG_ 2566832622 HighResolutionTotalVehicleDistance 917;
BA_ "SPN" SG_ 2566832622 HighResolutionTripDistance 918;
BA_ "SPN" SG_ 2566841327 EngSpeedAtIdlePoint1_ 188;
BA_ "SPN" SG_ 2566841327 EM1ReferenceTorque_ 544;
BA_ "SPN" SG_ 2566840303 NominalFrictionPercentTorque_EF 514;
BA_ "SPN" SG_ 2566840303 EstEM1PrsticLossesPercentTorque_ 2978;
BA_ "GenSigStartValue" SG_ 2566856943 EM1TorqueModeDrivingBraking_ 15;
BA_ "SPN" SG_ 2566840815 RetarderType_EF_ 901;
BA_ "SPN" SG_ 2566840815 RetarderLocation_EF 902;
BA_ "SPN" SG_ 2566840815 ReferenceRetarderTorque_EF 556;
BA_ "SPN" SG_ 2566842094 Seconds 959;
BA_ "SPN" SG_ 2566842094 Minutes 960;
BA_ "SPN" SG_ 2566842094 Hours 961;
BA_ "SPN" SG_ 2566842094 Month 963;
BA_ "SPN" SG_ 2566842094 Day 962;
BA_ "SPN" SG_ 2566842094 Year 964;
BA_ "SPN" SG_ 2566842094 LocalMinuteOffset 1601;
BA_ "SPN" SG_ 2566842094 LocalHourOffset 1602;
BA_ "SPN" SG_ 2431710879 ADAS_Posn_RelHead 521110;
BA_ "SPN" SG_ 2431710879 ADAS_Posn_Slope 521111;
BA_ "SPN" SG_ 2431710879 ADAS_Posn_Confdc 521112;
BA_ "GenSigInvalidValue" SG_ 2431710879 ADAS_Posn_Confdc 7;
BA_ "SPN" SG_ 2431710879 ADAS_Posn_Age 521113;
BA_ "GenSigInvalidValue" SG_ 2431710879 ADAS_Posn_Age 511;
BA_ "SPN" SG_ 2431710879 ADAS_Posn_PosProbb 521114;
BA_ "GenSigInvalidValue" SG_ 2431710879 ADAS_Posn_PosProbb 31;
BA_ "SPN" SG_ 2431710879 ADAS_Posn_Idx 521115;
BA_ "SPN" SG_ 2431710879 ADAS_Posn_PathIdx 521116;
BA_ "GenSigInvalidValue" SG_ 2431710879 ADAS_Posn_PathIdx 7;
BA_ "SPN" SG_ 2431710879 ADAS_Posn_CycCnt 521117;
BA_ "SPN" SG_ 2431710879 ADAS_Posn_Offset 521118;
BA_ "GenSigInvalidValue" SG_ 2431710879 ADAS_Posn_Offset 8191;
BA_ "SPN" SG_ 2431710879 ADAS_Posn_MsgTyp 521119;
BA_ "GenSigInvalidValue" SG_ 2431710879 ADAS_Posn_MsgTyp 7;
BA_ "SPN" SG_ 2498819743 ADAS_Stub_NumOfLaneDrvDir 521120;
BA_ "GenSigInvalidValue" SG_ 2498819743 ADAS_Stub_NumOfLaneDrvDir 7;
BA_ "GenSigSendType" SG_ 2498819743 ADAS_Stub_NumOfLaneDrvDir 5;
BA_ "SPN" SG_ 2498819743 ADAS_Stub_NumOfLaneOppDir 521121;
BA_ "GenSigInvalidValue" SG_ 2498819743 ADAS_Stub_NumOfLaneOppDir 3;
BA_ "GenSigSendType" SG_ 2498819743 ADAS_Stub_NumOfLaneOppDir 5;
BA_ "SPN" SG_ 2498819743 ADAS_Stub_RtOfWay 521122;
BA_ "GenSigInvalidValue" SG_ 2498819743 ADAS_Stub_RtOfWay 3;
BA_ "GenSigSendType" SG_ 2498819743 ADAS_Stub_RtOfWay 5;
BA_ "SPN" SG_ 2498819743 ADAS_Stub_LastStub 521123;
BA_ "GenSigSendType" SG_ 2498819743 ADAS_Stub_LastStub 5;
BA_ "SPN" SG_ 2498819743 ADAS_Stub_TurnAngl 521124;
BA_ "GenSigSendType" SG_ 2498819743 ADAS_Stub_TurnAngl 5;
BA_ "SPN" SG_ 2498819743 ADAS_Stub_FormOfWay_ 521125;
BA_ "GenSigInvalidValue" SG_ 2498819743 ADAS_Stub_FormOfWay_ 15;
BA_ "GenSigSendType" SG_ 2498819743 ADAS_Stub_FormOfWay_ 5;
BA_ "SPN" SG_ 2498819743 ADAS_Stub_CmplxInsct 521126;
BA_ "GenSigInvalidValue" SG_ 2498819743 ADAS_Stub_CmplxInsct 3;
BA_ "GenSigSendType" SG_ 2498819743 ADAS_Stub_CmplxInsct 5;
BA_ "SPN" SG_ 2498819743 ADAS_Stub_PartOfCalcRoute 521127;
BA_ "GenSigInvalidValue" SG_ 2498819743 ADAS_Stub_PartOfCalcRoute 3;
BA_ "GenSigSendType" SG_ 2498819743 ADAS_Stub_PartOfCalcRoute 5;
BA_ "SPN" SG_ 2498819743 ADAS_Stub_FuncRoadClass 521128;
BA_ "GenSigInvalidValue" SG_ 2498819743 ADAS_Stub_FuncRoadClass 7;
BA_ "GenSigSendType" SG_ 2498819743 ADAS_Stub_FuncRoadClass 5;
BA_ "SPN" SG_ 2498819743 ADAS_Stub_RelProbb 521129;
BA_ "GenSigInvalidValue" SG_ 2498819743 ADAS_Stub_RelProbb 31;
BA_ "GenSigSendType" SG_ 2498819743 ADAS_Stub_RelProbb 5;
BA_ "SPN" SG_ 2498819743 ADAS_Stub_Update 521130;
BA_ "GenSigSendType" SG_ 2498819743 ADAS_Stub_Update 5;
BA_ "SPN" SG_ 2498819743 ADAS_Stub_Retr 521131;
BA_ "GenSigSendType" SG_ 2498819743 ADAS_Stub_Retr 5;
BA_ "SPN" SG_ 2498819743 ADAS_Stub_SubPathIdx 521132;
BA_ "GenSigSendType" SG_ 2498819743 ADAS_Stub_SubPathIdx 5;
BA_ "SPN" SG_ 2498819743 ADAS_Stub_PathIdx 521133;
BA_ "GenSigInvalidValue" SG_ 2498819743 ADAS_Stub_PathIdx 7;
BA_ "GenSigSendType" SG_ 2498819743 ADAS_Stub_PathIdx 5;
BA_ "SPN" SG_ 2498819743 ADAS_Stub_CycCnt 521134;
BA_ "GenSigSendType" SG_ 2498819743 ADAS_Stub_CycCnt 5;
BA_ "SPN" SG_ 2498819743 ADAS_Stub_Offset 521135;
BA_ "GenSigInvalidValue" SG_ 2498819743 ADAS_Stub_Offset 8191;
BA_ "GenSigSendType" SG_ 2498819743 ADAS_Stub_Offset 5;
BA_ "SPN" SG_ 2498819743 ADAS_Stub_MsgType 521136;
BA_ "GenSigInvalidValue" SG_ 2498819743 ADAS_Stub_MsgType 7;
BA_ "GenSigSendType" SG_ 2498819743 ADAS_Stub_MsgType 5;
BA_ "SPN" SG_ 2565928863 ADAS_ProfShort_Value1 521137;
BA_ "GenSigInvalidValue" SG_ 2565928863 ADAS_ProfShort_Value1 1023;
BA_ "GenSigSendType" SG_ 2565928863 ADAS_ProfShort_Value1 5;
BA_ "SPN" SG_ 2565928863 ADAS_ProfShort_Value0 521138;
BA_ "GenSigInvalidValue" SG_ 2565928863 ADAS_ProfShort_Value0 1023;
BA_ "GenSigSendType" SG_ 2565928863 ADAS_ProfShort_Value0 5;
BA_ "SPN" SG_ 2565928863 ADAS_ProfShort_Dist1 521139;
BA_ "GenSigInvalidValue" SG_ 2565928863 ADAS_ProfShort_Dist1 1023;
BA_ "GenSigSendType" SG_ 2565928863 ADAS_ProfShort_Dist1 5;
BA_ "SPN" SG_ 2565928863 ADAS_ProfShort_AccurClass 521140;
BA_ "GenSigInvalidValue" SG_ 2565928863 ADAS_ProfShort_AccurClass 3;
BA_ "GenSigSendType" SG_ 2565928863 ADAS_ProfShort_AccurClass 5;
BA_ "SPN" SG_ 2565928863 ADAS_ProfShort_Update 521141;
BA_ "GenSigSendType" SG_ 2565928863 ADAS_ProfShort_Update 5;
BA_ "SPN" SG_ 2565928863 ADAS_ProfShort_Retr 521142;
BA_ "GenSigSendType" SG_ 2565928863 ADAS_ProfShort_Retr 5;
BA_ "SPN" SG_ 2565928863 ADAS_ProfShort_CtrlPoint 521143;
BA_ "GenSigSendType" SG_ 2565928863 ADAS_ProfShort_CtrlPoint 5;
BA_ "SPN" SG_ 2565928863 ADAS_ProfShort_ProfType 521144;
BA_ "GenSigSendType" SG_ 2565928863 ADAS_ProfShort_ProfType 5;
BA_ "SPN" SG_ 2565928863 ADAS_ProfShort_PathIdx 521145;
BA_ "GenSigInvalidValue" SG_ 2565928863 ADAS_ProfShort_PathIdx 7;
BA_ "GenSigSendType" SG_ 2565928863 ADAS_ProfShort_PathIdx 5;
BA_ "SPN" SG_ 2565928863 ADAS_ProfShort_CycCnt 521146;
BA_ "GenSigSendType" SG_ 2565928863 ADAS_ProfShort_CycCnt 5;
BA_ "SPN" SG_ 2565928863 ADAS_ProfShort_Offset 521147;
BA_ "GenSigInvalidValue" SG_ 2565928863 ADAS_ProfShort_Offset 8191;
BA_ "GenSigSendType" SG_ 2565928863 ADAS_ProfShort_Offset 5;
BA_ "SPN" SG_ 2565928863 ADAS_ProfShort_MsgTyp 521148;
BA_ "GenSigInvalidValue" SG_ 2565928863 ADAS_ProfShort_MsgTyp 7;
BA_ "GenSigSendType" SG_ 2565928863 ADAS_ProfShort_MsgTyp 5;
BA_ "SPN" SG_ 2565929119 ProfileLong_Value 521149;
BA_ "GenSigSendType" SG_ 2565929119 ProfileLong_Value 5;
BA_ "SPN" SG_ 2565929119 ADAS_ProfLong_Update 521150;
BA_ "GenSigSendType" SG_ 2565929119 ADAS_ProfLong_Update 5;
BA_ "SPN" SG_ 2565929119 ADAS_ProfLong_Retr 521151;
BA_ "GenSigSendType" SG_ 2565929119 ADAS_ProfLong_Retr 5;
BA_ "SPN" SG_ 2565929119 ADAS_ProfLong_CtrlPoint 521152;
BA_ "GenSigSendType" SG_ 2565929119 ADAS_ProfLong_CtrlPoint 5;
BA_ "SPN" SG_ 2565929119 ADAS_ProfLong_ProfType 521153;
BA_ "GenSigSendType" SG_ 2565929119 ADAS_ProfLong_ProfType 5;
BA_ "SPN" SG_ 2565929119 ADAS_ProfLong_Pathidx 521154;
BA_ "GenSigSendType" SG_ 2565929119 ADAS_ProfLong_Pathidx 5;
BA_ "SPN" SG_ 2565929119 ADAS_ProfLong_CycCnt 521155;
BA_ "GenSigSendType" SG_ 2565929119 ADAS_ProfLong_CycCnt 5;
BA_ "SPN" SG_ 2565929119 ADAS_ProfLong_Offset 521156;
BA_ "GenSigSendType" SG_ 2565929119 ADAS_ProfLong_Offset 5;
BA_ "SPN" SG_ 2565929119 ADAS_ProfLong_MsgType 521157;
BA_ "GenSigSendType" SG_ 2565929119 ADAS_ProfLong_MsgType 5;
BA_ "SPN" SG_ 2565928607 ADAS_Seg_NumOfLaneDrvDir 521158;
BA_ "GenSigSendType" SG_ 2565928607 ADAS_Seg_NumOfLaneDrvDir 5;
BA_ "SPN" SG_ 2565928607 ADAS_Seg_NumOfLaneOppDir 521159;
BA_ "GenSigSendType" SG_ 2565928607 ADAS_Seg_NumOfLaneOppDir 5;
BA_ "SPN" SG_ 2565928607 ADAS_Seg_DividedRoad 521160;
BA_ "GenSigSendType" SG_ 2565928607 ADAS_Seg_DividedRoad 5;
BA_ "SPN" SG_ 2565928607 ADAS_Seg_EffSpdLmtType 521161;
BA_ "GenSigSendType" SG_ 2565928607 ADAS_Seg_EffSpdLmtType 5;
BA_ "SPN" SG_ 2565928607 ADAS_Seg_EffSpdLmt 521162;
BA_ "GenSigSendType" SG_ 2565928607 ADAS_Seg_EffSpdLmt 5;
BA_ "SPN" SG_ 2565928607 ADAS_Seg_FormOfWay 521163;
BA_ "GenSigSendType" SG_ 2565928607 ADAS_Seg_FormOfWay 5;
BA_ "SPN" SG_ 2565928607 ADAS_Seg_CmplxInsct 521164;
BA_ "GenSigSendType" SG_ 2565928607 ADAS_Seg_CmplxInsct 5;
BA_ "SPN" SG_ 2565928607 ADAS_Seg_PartOfCalcRoute 521165;
BA_ "GenSigSendType" SG_ 2565928607 ADAS_Seg_PartOfCalcRoute 5;
BA_ "SPN" SG_ 2565928607 ADAS_Seg_FuncRoadClass 521166;
BA_ "GenSigSendType" SG_ 2565928607 ADAS_Seg_FuncRoadClass 5;
BA_ "SPN" SG_ 2565928607 ADAS_Seg_RelProbb 521167;
BA_ "GenSigSendType" SG_ 2565928607 ADAS_Seg_RelProbb 5;
BA_ "SPN" SG_ 2565928607 ADAS_Seg_Update 521168;
BA_ "GenSigSendType" SG_ 2565928607 ADAS_Seg_Update 5;
BA_ "SPN" SG_ 2565928607 ADAS_Seg_Retr 521169;
BA_ "GenSigSendType" SG_ 2565928607 ADAS_Seg_Retr 5;
BA_ "SPN" SG_ 2565928607 ADAS_Seg_BuildUpArea 521170;
BA_ "GenSigSendType" SG_ 2565928607 ADAS_Seg_BuildUpArea 5;
BA_ "SPN" SG_ 2565928607 ADAS_Seg_Bridge 521171;
BA_ "GenSigSendType" SG_ 2565928607 ADAS_Seg_Bridge 5;
BA_ "SPN" SG_ 2565928607 ADAS_Seg_Tunnel 521172;
BA_ "GenSigSendType" SG_ 2565928607 ADAS_Seg_Tunnel 5;
BA_ "SPN" SG_ 2565928607 ADAS_Seg_Pathidx 521173;
BA_ "GenSigSendType" SG_ 2565928607 ADAS_Seg_Pathidx 5;
BA_ "SPN" SG_ 2565928607 ADAS_Seg_CycCnt 521174;
BA_ "GenSigSendType" SG_ 2565928607 ADAS_Seg_CycCnt 5;
BA_ "SPN" SG_ 2565928607 ADAS_Seg_Offset 521175;
BA_ "GenSigSendType" SG_ 2565928607 ADAS_Seg_Offset 5;
BA_ "SPN" SG_ 2565928607 ADAS_Seg_MsgType 521176;
BA_ "GenSigSendType" SG_ 2565928607 ADAS_Seg_MsgType 5;
BA_ "SPN" SG_ 2633037471 ADAS_Meta_ProtVer_Minor 521177;
BA_ "SPN" SG_ 2633037471 ADAS_Meta_SpdUnits 521178;
BA_ "SPN" SG_ 2633037471 ADAS_Meta_MapVerYear 521179;
BA_ "SPN" SG_ 2633037471 ADAS_Meta_MapVerQtr 521180;
BA_ "SPN" SG_ 2633037471 ADAS_Meta_RegionCode 521181;
BA_ "SPN" SG_ 2633037471 ADAS_Meta_DrvSide 521182;
BA_ "SPN" SG_ 2633037471 ADAS_Meta_HWVer 521183;
BA_ "SPN" SG_ 2633037471 ADAS_Meta_ProtVer_MinorSub 521184;
BA_ "SPN" SG_ 2633037471 ADAS_Meta_ProtVer_Major 521185;
BA_ "SPN" SG_ 2633037471 ADAS_Meta_CycCnt 521186;
BA_ "SPN" SG_ 2633037471 ADAS_Meta_CountryCode 521187;
BA_ "SPN" SG_ 2633037471 ADAS_Meta_MapProvider 521188;
BA_ "SPN" SG_ 2633037471 ADAS_Meta_MsgType 521189;
BA_ "SPN" SG_ 2565799839 IdentityNumber 521190;
BA_ "SPN" SG_ 2565799839 ManufacturerCode 521191;
BA_ "SPN" SG_ 2565799839 ECUInstance 521192;
BA_ "SPN" SG_ 2565799839 FunctionInstance 521193;
BA_ "SPN" SG_ 2565799839 Function 521194;
BA_ "SPN" SG_ 2565799839 VehicleSystem 521195;
BA_ "SPN" SG_ 2565799839 VehicleSystemInstance_ 521196;
BA_ "SPN" SG_ 2565799839 IndustryGroup 521197;
BA_ "SPN" SG_ 2565799839 ArbitraryAddressCapable_ 521198;
BA_ "SPN" SG_ 2566845343 Latitude 584;
BA_ "GenSigInvalidValue" SG_ 2566845343 Latitude 251;
BA_ "SPN" SG_ 2566845343 Longitude 585;
BA_ "GenSigInvalidValue" SG_ 2566845343 Longitude 251;
BA_ "SPN" SG_ 2566842527 Navigation_BasedVehicleSpeed 517;
BA_ "SPN" SG_ 2566842527 Altitude 580;
BA_ "SPN" SG_ 2633037727 ADASProfileShortSlope 521216;
BA_ "GenSigInvalidValue" SG_ 2633037727 ADASProfileShortSlope 1023;
VAL_ 2348810282 EngOverrideCtrlMode_C00002A 3 "Spd_TrqLmtCtrlLmtSpdAnd_OrTrqBs" 2 "TrqCtrlCntrlTrqTInclddDsrdTrqVl" 1 "SpdCtrlGvrnSpdTInclddDsrdSpdVle" 0 "OvrrdDsbldDsblAnyExstngCtrlCmdd";
VAL_ 2348810282 EngRqedSpeedCtrlConditions_C00002A 3 "StbltyOptmzdFrDrvlnEnggdAnd_OrI" 2 "ThsCtrlCndtnHsBnOptmzdTMnmzRpmO" 1 "StbltyOptmzdFrDrvlnDsnggdAndNnl" 0 "ThsSpdGvrnrGnSlctnIsAdjstdTPrvd";
VAL_ 2348810282 OverrideCtrlModePriority_C00002A 3 "LowPriority" 2 "MdmPrrtyUsdFrPwrtrnCtrlOprtnsWh" 1 "HighPriority" 0 "HghstPrrtyUsdFrSttnsThtRqrImmdt";
VAL_ 2348810282 TransmissionRate_C00002A 7 "UseStandardRate10ms" 6 "20ms" 5 "50ms" 4 "100ms" 3 "250ms" 2 "500ms" 1 "750ms" 0 "1000ms";
VAL_ 2348810282 ControlPurpose_C00002A 31 "TemporaryPowerTrainCotrol" 30 "ReservedForSAEAssigment" 29 "ReservedForSAEAssigment" 28 "ReservedForSAEAssigment" 27 "ReservedForSAEAssigment" 26 "ReservedForSAEAssigment" 25 "ReservedForSAEAssigment" 24 "ReservedForSAEAssigment" 23 "ReservedForSAEAssigment" 22 "ReservedForSAEAssigment" 21 "ReservedForSAEAssigment" 20 "ReservedForSAEAssigment" 19 "ReservedForSAEAssigment" 18 "ReservedForSAEAssigment" 17 "ReservedForSAEAssigment" 16 "ReservedForSAEAssigment" 15 "ReservedForSAEAssigment" 14 "ReservedForSAEAssigment" 13 "ReservedForSAEAssigment" 12 "ReservedForSAEAssigment" 11 "ReservedForSAEAssigment" 10 "ReservedForSAEAssigment" 9 "ReservedForSAEAssigment" 8 "ReservedForSAEAssigment" 7 "ReservedForSAEAssigment" 6 "ReservedForSAEAssigment" 5 "TemporaryPowerTrainControl" 4 "EngineProtection" 3 "RoadSpeedGovernor" 2 "PTOGovernor" 1 "CruiseControl" 0 "AcceleratorPedal";
VAL_ 2348810282 EngineRequestedTorqueHiRes_C00002A 15 "NotAvailable" 14 "NotAvailable" 13 "NotAvailable" 12 "NotAvailable" 11 "NotAvailable" 10 "NotAvailable" 9 "NotAvailable" 8 "NotAvailable" 7 "+0.825%" 6 "+0.750%" 5 "+0.625%" 4 "+0.500%" 3 "+0.375%" 2 "+0.250%" 1 "+0.125%" 0 "+0.000%";
VAL_ 2349465642 CruiseControlPauseCommand 3 "Don'tcare/takenoaction" 2 "Reserved" 1 "CruiseControlisnot~0xFFowed" 0 "CruiseControlis~0xFFowed";
VAL_ 2566859752 HazardSwRq 3 "Reserved" 2 "Reserved" 1 "On" 0 "Off";
VAL_ 2566859752 LowBeamSwRq 3 "notused" 2 "reserved" 1 "on" 0 "off";
VAL_ 2566859752 HighBeamSwRq 3 "notused" 2 "reserved" 1 "on" 0 "off";
VAL_ 2566859752 IHBC_Status 7 "Reserved" 6 "Reserved" 5 "Reserved" 4 "Permanent:Error" 3 "Temporary:Error" 2 "Active" 1 "Standby" 0 "OFF";
VAL_ 2566859752 SLI_Status 3 "reserved" 2 "SLIfailure" 1 "VisionOnlyMode" 0 "Off";
VAL_ 2566859752 SLIF_Status 3 "reserved" 2 "SLIFfailure" 1 "VisionOnlyModeandwarning" 0 "Off";
VAL_ 2566859752 SLIF_Warning 1 "Warning" 0 "No:Warning";
VAL_ 2566859752 Sign_Speedlimit 12 "120" 11 "110" 10 "100" 9 "90" 8 "80" 7 "70" 6 "60" 5 "50" 4 "40" 3 "30" 2 "20" 1 "10" 0 "Nodisplay";
VAL_ 2566859752 Sign_SpeedLimitCancelled 1 "Speed:Limit:Canceled" 0 "Speed:Limit";
VAL_ 2565865808 HaltBrakeSwitchEPB 3 "Notavailable" 2 "Error" 1 "Haltbrakeswitchactive" 0 "Haltbrakeswitchpassive";
VAL_ 2566787664 EPB_ParkBraStatus 3 "Error" 2 "Disable（释放驻车）" 1 "Enable(驻车)" 0 "NotAvailable（0-0x2x0%的驻车状态）";
VAL_ 2566787664 AH_ParkActive 3 "Error" 2 "Inactive" 1 "Active" 0 "NotAvailable";
VAL_ 2566787664 AH_BraStatus 3 "Error" 2 "Off" 1 "On" 0 "NotAvailable";
VAL_ 2566787664 EPB_WorkMode 3 "WorkShopMode" 2 "BrakePressureControlMode" 1 "ExternalBrakeControlMode" 0 "NormalMode";
VAL_ 2566787664 ErrCode 1 "Error" 0 "NoError";
VAL_ 2566787664 ChildLockActive 3 "Error" 2 "Off" 1 "On" 0 "NotAvailable";
VAL_ 2566787664 LowPreRelParkLimit 3 "Error" 2 "Off" 1 "On" 0 "NotAvailable";
VAL_ 2566787664 TrailerCnctChck 3 "Error" 2 "Off" 1 "On" 0 "NotAvailable";
VAL_ 2566787664 ResponsePriority 3 "Error" 2 "Off" 1 "On" 0 "NotAvailable";
VAL_ 2566787664 IdepedtBraOly 3 "Error" 2 "Off" 1 "On" 0 "NotAvailable";
VAL_ 2566787664 PrakBraForcTest 3 "Error" 2 "Off" 1 "On" 0 "NotAvailable";
VAL_ 2566787664 DriveHillStatus 3 "Error" 2 "DownHill" 1 "UpHill" 0 "Levelroad";
VAL_ 2566787664 EPB_BraSwitch 3 "Notavailable" 2 "Error" 1 "EPBBrakeSet" 0 "EPBBrakeNotSet";
VAL_ 2566787664 ParkBtSwitch 3 "Notavailable" 2 "Error" 1 "Switchactive" 0 "Switchpassive";
VAL_ 2566787664 RelsBtSwitch 3 "Notavailable" 2 "Error" 1 "Switchactive" 0 "Switchpassive";
VAL_ 2566787664 AHBtSwitch 3 "Notavailable" 2 "Error" 1 "Switchactive" 0 "Switchpassive";
VAL_ 2566787664 IdepedtBtSwitch 3 "Notavailable" 2 "Error" 1 "Switchactive" 0 "Switchpassive";
VAL_ 2566787664 ForcTestBtSwitch 3 "Notavailable" 2 "Error" 1 "Switchactive" 0 "Switchpassive";
VAL_ 2566787664 SysStatus 3 "Notavailable" 2 "DriverlessActive" 1 "DriverlessReady" 0 "DriverlessnotReady";
VAL_ 2566787664 WarmingStatus 3 "AutomatedDrivingWarning（自动驾驶中，需要退出自动驾驶才能操作）" 2 "SystemFaultWarning（系统故障无法操作驻车，需要通过机械应急方式操作驻车）" 1 "FunctionLimitWarning(智能功能受限，熄火没有自动驻车需要手动操作EPB开关驻车)" 0 "NoWarning";
VAL_ 2566787664 RollerTestBenchMode 1 "ActivateRollerTestBenchMode" 0 "DeactivateRollerTestBenchMode";
VAL_ 2365562448 EPB_HADHndShkRespSt 15 "Notinst~0xFFed" 14 "Error(系统存在故障无法响应智能驾驶)" 7 "DeactivatedbyADCUerrormessage(由于无人驾驶指令错误(校验或者counter错误)暂时退出了智能驾驶控制，需要发送恢复模式清除该状态)" 6 "Deactivatedbydriver(开关优先的模式下操作了开关暂时退出了智能驾驶控制，需要发送恢复模式清除该状态)" 5 "L5Ready(请求该状态主/副CAN可控，制动优先，开关操作无效)" 4 "L4Ready(请求该状态主/副CAN可控，制动优先)" 3 "L3Ready(请求该状态主/副CAN可控，开关操作优先)" 2 "L2Ready(请求该状态主CAN可控，开关操作优先)" 1 "Systemready(系统可控制进入智能驾驶)" 0 "Notready(系统自检)";
VAL_ 2365562448 EPB_AvailStsforHAD 3 "Secondaryonly(仅冗余通道可用)" 2 "SecondaryorPrimary(两个通道都可以用)" 1 "Primaryonly(仅主通道可用)" 0 "BothNotAvailable(没有可用的通道)";
VAL_ 2365562448 EPB_ParkBrkSt 15 "Unavailable" 14 "Error" 5 "XBRbrakingactive" 4 "Secondarybrakingactive" 3 "Parkingbrakeapplying" 2 "Parkingbrakereleasing" 1 "Parkingbrakeapplied" 0 "Parkingbrakenotapplied";
VAL_ 2365562448 EPBADModeState 15 "NotReady(系统自检)" 14 "Ready(自检完可以进入AD模式)" 3 "ADUEngagedDegrade(从AD模式运行出现任意通道故障进行降级)" 2 "ADUEngaged(所有通道无故障将允许请求进入了全功能AD模式)" 1 "ADUErrorDegrade(冗余AD模式出现错误，但是可以通过主通道控制)" 0 "Unavailable(AD不可用)";
VAL_ 2365562448 ErrorCode 0 "NoError";
VAL_ 2365562448 ParkBrRelsInhibitSt 3 "Unavailable" 2 "Error" 1 "ParkBrakereleaseisinhibited" 0 "ParkBrakereleaseisnotinhibited";
VAL_ 2365562448 ParkBrkInhibitSt 3 "Unavailable" 2 "Error" 1 "ParkBrakeisinhibited" 0 "ParkBrakeisnotinhibited";
VAL_ 2365562448 EPB_HaltBrakeSt 15 "Unavailable" 14 "Error(故障)" 4 "Notfunctional(功能受限不起作用)" 3 "Active(启动停车制动)" 2 "Standby(功能使能，但没满足启动条件)" 1 "Ready(自检完成可用进行功能使能)" 0 "NotReady(系统在自检)";
VAL_ 2566911764 DriverInterventionStatus_S 7 "Notavailable" 6 "Error" 5 "Reserved" 4 "Reserved" 3 "Reserved" 2 "DIDDetectionDisabled（禁用脱手检测）" 1 "DIDDetected（检测到脱手）" 0 "DIDnotDetected（未检测到驾驶员介入）";
VAL_ 2566897256 WPTC1_WorkingSts 1 "On" 0 "Off";
VAL_ 2566897256 WPTC1_FaultLevel 3 "Fault Lv3" 2 "Fault Lv2" 1 "Fault Lv1" 0 "No Fault";
VAL_ 2566897256 WPTC1_HVOverVoltage 1 "Error" 0 "No Error";
VAL_ 2566897256 WPTC1_HVUnderVoltage 1 "Error" 0 "No Error";
VAL_ 2566897256 WPTC1_LVOverVoltage 1 "Error" 0 "No Error";
VAL_ 2566897256 WPTC1_LVUnderVoltage 1 "Error" 0 "No Error";
VAL_ 2566897256 WPTC1_OpenCircuit 1 "Error" 0 "No Error";
VAL_ 2566897256 WPTC1_OutletOverheating 1 "Error" 0 "No Error";
VAL_ 2566897256 WPTC1_IGBTOverheating 1 "Error" 0 "No Error";
VAL_ 2566897256 WPTC1_ComLoss 1 "Error" 0 "No Error";
VAL_ 2566897256 WPTC1_IGBTShortCircuit 1 "Error" 0 "No Error";
VAL_ 2566897256 WPTC1_LowFlowrate 1 "Error" 0 "No Error";
VAL_ 2566897256 WPTC1_OvercurrentFault 1 "Error" 0 "No Error";
VAL_ 2566897256 WPTC1_PTCShortCircuit 1 "Error" 0 "No Error";
VAL_ 2566897256 WPTC1_NTCFault 1 "Error" 0 "No Error";
VAL_ 2566897283 WPTC2_WorkingSts 1 "On" 0 "Off";
VAL_ 2566897283 WPTC2_FaultLevel 3 "Fault Lv3" 2 "Fault Lv2" 1 "Fault Lv1" 0 "No Fault";
VAL_ 2566897283 WPTC2_HVOverVoltage 1 "Error" 0 "No Error";
VAL_ 2566897283 WPTC2_HVUnderVoltage 1 "Error" 0 "No Error";
VAL_ 2566897283 WPTC2_LVOverVoltage 1 "Error" 0 "No Error";
VAL_ 2566897283 WPTC2_LVUnderVoltage 1 "Error" 0 "No Error";
VAL_ 2566897283 WPTC2_OpenCircuit 1 "Error" 0 "No Error";
VAL_ 2566897283 WPTC2_OutletOverheating 1 "Error" 0 "No Error";
VAL_ 2566897283 WPTC2_IGBTOverheating 1 "Error" 0 "No Error";
VAL_ 2566897283 WPTC2_ComLoss 1 "Error" 0 "No Error";
VAL_ 2566897283 WPTC2_IGBTShortCircuit 1 "Error" 0 "No Error";
VAL_ 2566897283 WPTC2_LowFlowrate 1 "Error" 0 "No Error";
VAL_ 2566897283 WPTC2_OvercurrentFault 1 "Error" 0 "No Error";
VAL_ 2566897283 WPTC2_PTCShortCircuit 1 "Error" 0 "No Error";
VAL_ 2566897283 WPTC2_NTCFault 1 "Error" 0 "No Error";
VAL_ 2566897284 WPTC3_WorkingSts 1 "On" 0 "Off";
VAL_ 2566897284 WPTC3_FaultLevel 3 "Fault Lv3" 2 "Fault Lv2" 1 "Fault Lv1" 0 "No Fault";
VAL_ 2566897284 WPTC3_HVOverVoltage 1 "Error" 0 "No Error";
VAL_ 2566897284 WPTC3_HVUnderVoltage 1 "Error" 0 "No Error";
VAL_ 2566897284 WPTC3_LVOverVoltage 1 "Error" 0 "No Error";
VAL_ 2566897284 WPTC3_LVUnderVoltage 1 "Error" 0 "No Error";
VAL_ 2566897284 WPTC3_OpenCircuit 1 "Error" 0 "No Error";
VAL_ 2566897284 WPTC3_OutletOverheating 1 "Error" 0 "No Error";
VAL_ 2566897284 WPTC3_IGBTOverheating 1 "Error" 0 "No Error";
VAL_ 2566897284 WPTC3_ComLoss 1 "Error" 0 "No Error";
VAL_ 2566897284 WPTC3_IGBTShortCircuit 1 "Error" 0 "No Error";
VAL_ 2566897284 WPTC3_LowFlowrate 1 "Error" 0 "No Error";
VAL_ 2566897284 WPTC3_OvercurrentFault 1 "Error" 0 "No Error";
VAL_ 2566897284 WPTC3_PTCShortCircuit 1 "Error" 0 "No Error";
VAL_ 2566897284 WPTC3_NTCFault 1 "Error" 0 "No Error";
VAL_ 2348810251 EngOverrideCtrlMode_C00000B 3 "Speed/torquelimitcontrolLimitspeedand/ortorquebasedontheincludedlimitvaluesThespeedlimitgovernoris" 2 "TorquecontrolControltorquetotheincludeddesiredtorquevalue" 1 "SpeedcontrolGovernspeedtotheincludeddesiredspeedvalue" 0 "OverridedisabledDisableanyexistingcontrolcommandedbythesourceofthiscommand";
VAL_ 2348810251 EngRequestedSpeedCtrlConditions_C00000B 3 "StabilityOptimizedfordrivelineengagedand/orinlockupcondition2egPTOdriveline" 2 "StabilityOptimizedfordrivelineengagedand/orinlockupcondition1egvehicledriveline" 1 "StabilityOptimizedfordrivelinedisengagedandnonlockupconditions" 0 "TransientOptimizedfordrivelinedisengagedandnonlockupconditions";
VAL_ 2348810251 OverrideCtrlModePriority_C00000B 3 "Lowpriority" 2 "Mediumpriority" 1 "Highpriority" 0 "Highestpriority";
VAL_ 2565865487 RetarderTorqueMode_18F0000F 15 "Not available" 14 "VCM negative torque demand" 13 "Not defined" 12 "Not defined" 11 "Not defined" 10 "Retarder control (not used)" 9 "High speed governor (not used)" 8 "Torque limiter" 7 "ABS control (not used)" 6 "Transmission control (not used)" 5 "ASR control (not used)" 4 "Road speed limiter (not used)" 3 "PTO governor (not used)" 2 "Cruise control (not used)" 1 "Operator selection (not used)" 0 "No request";
VAL_ 2565865487 ActualRetarderPercentTorque_18F0000F 255 "Signal not available" 254 "Error";
VAL_ 2565865487 DrvrsDemandRetarderPercentTorque_18F0000F 255 "Signal not available" 254 "Error";
VAL_ 2565865487 ActlMxAvlblRetarderPercentTorque_18F0000F 255 "Signal not available" 254 "Error";
VAL_ 2566840591 ReferenceRetarderTorque_18FEE10F 65535 "Signal not available" 65024 "Error";
VAL_ 2565865488 RetarderRqingBrakeLight 3 "NotAvailable_TakeNoAction" 2 "Reserved" 1 "RtrdrIsRqngThtBrkLghtsArIllmntd" 0 "RtrdrIsNtRqngThtBrkLghtsArIllmn";
VAL_ 2566840592 RetarderType_10 15 "NotAvailable" 14 "Other" 5 "1101NotDefined" 4 "Exhaust" 3 "CompressionRelease" 2 "CooledFriction" 1 "Hyd" 0 "Electric_Magnetic";
VAL_ 2566840592 RetarderLocation_10 15 "NotAvailable" 14 "Other" 6 "1101NotDefined" 5 "Trailer" 4 "Driveline" 3 "TransOutput" 2 "TransInput" 1 "EngExhaustBrake" 0 "EngCompressionReleaseBrake";
VAL_ 2565865513 RetarderTorqueMode 15 "Not available" 14 "VCM negative torque demand" 13 "Not defined" 12 "Not defined" 11 "Not defined" 10 "Retarder control (not used)" 9 "High speed governor (not used)" 8 "Torque limiter" 7 "ABS control (not used)" 6 "Transmission control (not used)" 5 "ASR control (not used)" 4 "Road speed limiter (not used)" 3 "PTO governor (not used)" 2 "Cruise control (not used)" 1 "Operator selection (not used)" 0 "No request";
VAL_ 2565865513 ActualRetarderPercentTorque 255 "Signal not available" 254 "Error";
VAL_ 2565865513 DrvrsDemandRetarderPercentTorque_18F00029 255 "Signal not available" 254 "Error";
VAL_ 2565865513 ActlMxAvlblRetarderPercentTorque 255 "Signal not available" 254 "Error";
VAL_ 2566840617 ReferenceRetarderTorque 65535 "Signal not available" 65024 "Error";
VAL_ 2348814091 EngOverrideCtrlMode_C000F0B 3 "Speed/torque limit control  Limit speed and/or torque based on the included limit values  The speed limit governor is" 2 "Torque control  Control torque to the included desired torque value" 1 "Speed control  Govern speed to the included desired speed value" 0 "Override disabled  Disable any existing control commanded by the source of this command";
VAL_ 2348814091 OverrideCtrlModePriority_C000F0B 3 "Low priority" 2 "Medium priority" 1 "High priority" 0 "Highest priority";
VAL_ 2348814091 EngRequestedTorque_TorqueLimit_C000F0B 255 "Signal not available" 254 "Error";
VAL_ 2348814347 EngOverrideCtrlMode_C00100B 3 "Speed/torquelimitcontrolLimitspeedand/ortorquebasedontheincludedlimitvaluesThespeedlimitgovernoris" 2 "TorquecontrolControltorquetotheincludeddesiredtorquevalue" 1 "SpeedcontrolGovernspeedtotheincludeddesiredspeedvalue" 0 "OverridedisabledDisableanyexistingcontrolcommandedbythesourceofthiscommand";
VAL_ 2348814347 EngRequestedSpeedCtrlConditions_C00100B 3 "StabilityOptimizedfordrivelineengagedand/orinlockupcondition2egPTOdriveline" 2 "StabilityOptimizedfordrivelineengagedand/orinlockupcondition1egvehicledriveline" 1 "StabilityOptimizedfordrivelinedisengagedandnonlockupconditions" 0 "TransientOptimizedfordrivelinedisengagedandnonlockupconditions";
VAL_ 2348814347 OverrideCtrlModePriority_C00100B 3 "Lowpriority" 2 "Mediumpriority" 1 "Highpriority" 0 "Highestpriority";
VAL_ 2348814347 TSC1TransRate_C00100B 7 "UsestandardTSC1transmissionratesof10mstoengine" 6 "20mstransmissionrate" 5 "50mstransmissionrate" 4 "100mstransmissionrate" 3 "250mstransmissionrate" 2 "500mstransmissionrate" 1 "750mstransmissionrate" 0 "1000mstransmissionrate";
VAL_ 2348814347 TSC1CtrlPurpose_C00100B 31 "P32TemporaryPowerTrainControlOriginaluseofTSC1Command" 4 "P5EngineProtection" 3 "P4RoadSpeedGovernor" 2 "P3PTOGovernor" 1 "P2CruiseControl" 0 "P1AcceleratorPedal/OperatorSelection";
VAL_ 2348814347 EngRequestedTorqueHighResolution_C00100B 7 "+0.875%" 6 "+0.750%" 5 "+0.625%" 4 "+0.500%" 3 "+0.375%" 2 "+0.250%" 1 "+0.125%" 0 "+0.000%";
VAL_ 2348820747 EngOverrideCtrlMode 3 "Speed/torque limit control  Limit speed and/or torque based on the included limit values  The speed limit governor is" 2 "Torque control  Control torque to the included desired torque value" 1 "Speed control  Govern speed to the included desired speed value" 0 "Override disabled  Disable any existing control commanded by the source of this command";
VAL_ 2348820747 OverrideCtrlModePriority 3 "Low priority" 2 "Medium priority" 1 "High priority" 0 "Highest priority";
VAL_ 2348820747 EngRequestedTorque_TorqueLimit 255 "Signal not available" 254 "Error";
VAL_ 2566844672 ParkingBrakeSwitch 3 "NotAvailable" 2 "Error" 1 "ParkingBrakeSet" 0 "ParkingBrakeNotSet";
VAL_ 2566844672 BrakeSwitch 3 "NotAvailable" 2 "Error" 1 "BrakePedalDepressed" 0 "BrakePedalReleased";
VAL_ 2566844672 ClutchSwitch 3 "NotAvailable" 2 "Error" 1 "ClutchPedalDepressed" 0 "ClutchPedalReleased";
VAL_ 2364539904 EngTorqueMode_ 15 "Not available" 14 "蠕行或非D档" 12 "Torque limiter activation" 11 "Remote accelerator" 10 "Braking system" 9 "High speed governor" 8 "Torque limiting" 7 "ABS control" 6 "Transmission control" 5 "ASR control" 4 "Road speed governor" 3 "PTO governor" 2 "Cruise control" 1 "Accelerator pedal/operator selec" 0 "Low idle governor/no request (de";
VAL_ 2364539904 ActlEngPrcntTrqueHighResolution_ 15 "NotAvailable" 14 "NotAvailable" 13 "NotAvailable" 12 "NotAvailable" 11 "NotAvailable" 10 "NotAvailable" 9 "NotAvailable" 8 "NotAvailable" 7 "0.875" 6 "0.750" 5 "0.625" 4 "0.500" 3 "0.375" 2 "0.250" 1 "0.125" 0 "0";
VAL_ 2364539648 AccelPedal1LowIdleSwitch_ 3 "NotAvailable" 2 "Error" 1 "AccelPedal1InLowIdleCondition" 0 "AcclPedal1NotInLowIdleCondition";
VAL_ 2364539648 AccelPedalKickdownSwitch 3 "NotAvailable" 2 "Error" 1 "KickdownActive" 0 "KickdownPassive";
VAL_ 2566843904 EngCoolantTemp 255 "Signal not available" 254 "Error";
VAL_ 2566845952 EngIntakeManifold1Press 255 "Signal not available" 254 "Error";
VAL_ 2365537280 ActualEngPercentTorque 255 "Signal not available" 254 "Error";
VAL_ 2365537280 NominalFrictionPercentTorque 255 "Signal not available" 254 "Error";
VAL_ 2364539395 TransDrivelineEngaged_CF00203 3 "NotAvailable" 2 "Error" 1 "DrivelineEngaged" 0 "DrivelineDisengaged";
VAL_ 2364539395 TransShiftInProcess_CF00203 3 "NotAvailable" 2 "Error" 1 "ShiftInProcess" 0 "ShiftIsNotInProcess";
VAL_ 2565866755 TransSelectedGear 125 "Neutral";
VAL_ 2565866755 TransCurrentGear_18F00503 251 "Park";
VAL_ 2566801923 TransReadyForBrakeRelease_18FE4A03 3 "Not available" 2 "Error" 1 "TransReadyForBrakeRelease" 0 "TransNotReadyForBrakeRelease";
VAL_ 2364541955 TransTorqueConverterRatio 65535 "Signal not available" 65279 "Error";
VAL_ 2566853635 TransReadyForBrakeRelease 3 "Not available" 2 "Error" 1 "Transmission Ready for Brake Release" 0 "Transmission Not Ready for Brake Release";
VAL_ 2566853635 TransCurrentGear 255 "Signal not available" 254 "Error";
VAL_ 2566853635 PercentClutchSlip 255 "Signal not available" 254 "Error";
VAL_ 2566853635 TransShiftInProcess 3 "Not available" 2 "Error" 1 "Shift in process" 0 "Shift is not in process";
VAL_ 2566853635 TransDrivelineEngaged 3 "Not available" 2 "Error" 1 "Driveline engaged" 0 "Driveline disengaged";
VAL_ 2566853635 TrnsTorqueConverterLockupEngaged 3 "Not available" 2 "Error" 1 "Torque converter lockup engaged" 0 "Torque converter lockup disengaged";
VAL_ 2566853635 ActiveShiftConsoleIndicator 3 "Not available" 2 "Reserved" 1 "Secondary shift console is active" 0 "Primary shift console is active";
VAL_ 2565865739 AntiLockBrakingActive 3 "NotAvailable" 2 "Reserved" 1 "ABSActive" 0 "ABSPassiveButInst~0xFFed";
VAL_ 2565865739 EBSBrakeSwitch_18F0010B 3 "NotAvailable" 2 "Error" 1 "BrakePedalIsBeingPressed" 0 "BrakePedalIsNotBeingPressed";
VAL_ 2565865739 ABSFullyOperational 3 "NotAvailable" 2 "Reserved" 1 "FullyOperational" 0 "NotFullyOperational";
VAL_ 2566803211 ROPEngCtrlActive 3 "DontCare_TakeNoAction" 2 "Reserved" 1 "ROPEngCtrlActive" 0 "ROPEngCtrlPassiveButInst~0xFFed";
VAL_ 2566803211 ROPBrakeCtrlActive 3 "DontCare_TakeNoAction" 2 "Reserved" 1 "ROPBrakeCtrlActive" 0 "ROPBrakeCtrlPassiveButInst~0xFFed";
VAL_ 2566803211 YCEngCtrlActive 3 "DontCare_TakeNoAction" 2 "Reserved" 1 "YCEngCtrlActive" 0 "YCEngCtrlPassiveButInst~0xFFed";
VAL_ 2566803211 YCBrakeCtrlActive 3 "DontCare_TakeNoAction" 2 "Reserved" 1 "YCBrakeCtrlActive" 0 "YCBrakeCtrlPassiveButInst~0xFFed";
VAL_ 2565867787 SteerWheelAngleSensorType 3 "NotAvailable" 2 "Reserved" 1 "AbsMeasuringPrinciple" 0 "RelativeMeasuringPrinciple";
VAL_ 2566767627 HaltBrakeMode 7 "NotAvailable" 6 "Reserved" 5 "NotDefined" 4 "NotDefined" 3 "NotDefined" 2 "ActiveButNotFunctioningProperly" 1 "Active" 0 "Inactive";
VAL_ 2566767627 HillHolderMode 7 "NotAvailable" 6 "HillHolderNotFunctional" 5 "Reserved" 4 "Reserved" 3 "Reserved" 2 "ActvBtWllChngTInctvInAShortTime" 1 "Active" 0 "Inactive";
VAL_ 2566767627 FoundationBrakeUse 3 "NotAvailable" 2 "Reserved" 1 "FoundationBrakesInUse" 0 "FoundationBrakesNotInUse";
VAL_ 2566767627 XBRSystemState 3 "NotAvailable" 2 "NoExtlBrakeDemandWillBeAccepted" 1 "OnlyExtlBrkDmndOfHghstXBRPrrtyW" 0 "AnyExtlBrkeDemandWillBeAccepted";
VAL_ 2566767627 XBRActiveCtrlMode 15 "NotAvailable" 14 "ReservedForSAEAssignment" 13 "ReservedForSAEAssignment" 12 "ReservedForSAEAssignment" 11 "ReservedForSAEAssignment" 10 "ReservedForSAEAssignment" 9 "ReservedForSAEAssignment" 8 "ReservedForSAEAssignment" 7 "ReservedForSAEAssignment" 6 "ReservedForSAEAssignment" 5 "ReservedForSAEAssignment" 4 "ReservedForSAEAssignment" 3 "MxMdOfXBRAcclrtnCtrlBngExecuted" 2 "AddtnMdOfXBRAcclrtnCtrlBngExctd" 1 "DrvrsBrkDmndBngExctdNExtlBrkDmn" 0 "NoBrakeDemandBeingExecuted";
VAL_ 2566767627 PrkngBrkeActuatorFullyActivated 3 "NotAvailable" 2 "Error" 1 "PrkngBrkeActuatorFullyActivated" 0 "PrkngBrkActtorNotFullyActivated";
VAL_ 2566767627 EmergencyBrakingActive 3 "NotAvailable" 2 "Reserved" 1 "Active" 0 "Inactive";
VAL_ 2566847015 BrakePrimaryPress 255 "Signal not available" 254 "Error";
VAL_ 2566847015 BrakeSecondPress 255 "Signal not available" 254 "Error";
VAL_ 2565865767 ABSOffroadSwitch_18F00127 3 "Not available" 2 "Error" 1 "ABS offroad switch active" 0 "ABS offroad switch passive";
VAL_ 2565865767 ASROffroadSwitch_18F00127 3 "Not available" 2 "Error" 1 "ASR offroad switch active" 0 "ASR offroad switch passive";
VAL_ 2565865767 ASRHillHolderSwitch_18F00127 3 "Not available" 2 "Error" 1 "ASR hill holder switch active" 0 "ASR hill holder switch passive";
VAL_ 2565865767 EngRetarderSelection 255 "Signal not available" 254 "Error";
VAL_ 2565865767 HaltBrakeSwitch_18F00127 3 "Not available" 2 "Error" 1 "Halt brake switch active" 0 "Halt brake switch passive";
VAL_ 2565865767 TrctrMntdTrailerABSWarningSignal 3 "Take no action" 2 "Reserved" 1 "On" 0 "Off";
VAL_ 2565865511 DrvrsDemandRetarderPercentTorque 255 "Signal not available" 254 "Error";
VAL_ 2565865511 RetarderSelectionNonengine 255 "Signal not available" 254 "Error";
VAL_ 2566857767 RetarderLeverState 255 "Signal not available" 254 "Error";
VAL_ 2432593706 AdaptiveCruiseControlMode 7 "Notavailable/notvalid" 6 "Disabledorerrorcondition" 5 "Finishmode" 4 "Holdmode" 3 "Overtakemode" 2 "Distancecontrolactive" 1 "Speedcontrolactive" 0 "Off(Standby,enabled,readyforactivation)";
VAL_ 2432593706 AdaptivecruisecontrolsetdistanceMode 7 "NotAvailable_NotValid" 6 "ErrorCondition" 5 "ConventionalCruiseCtrlMode" 4 "ACCDistanceMode5(Shortest)" 3 "ACCDistanceMode4" 2 "ACCDistanceMode3" 1 "ACCDistanceMode2" 0 "ACCDistanceMode1(Largest)";
VAL_ 2432593706 ACCTargetDetected 3 "NotAvailable" 2 "Reserved" 1 "Targetdetected" 0 "Notargetsdetected";
VAL_ 2432593706 ACCSystemShutoffWarning 3 "NotAvailable" 2 "Reserved" 1 "ACCSSOWActive" 0 "ACCSSOWNotActive";
VAL_ 2432593706 ACCDistanceAlertSignal 3 "Takenoaction" 2 "Reserved" 1 "ACCDASActive" 0 "ACCDASNotActive";
VAL_ 2432593706 ForwardCollisionWarning 3 "NotAvailable" 2 "Errorindicator" 1 "Collisionisimminent" 0 "Nowarning";
VAL_ 2365479471 NominalLevelFrontAxle 15 "NotAvailable" 14 "Error" 13 "NotDefined" 12 "NotDefined" 11 "NotDefined" 10 "Lowering" 9 "Raising" 8 "NotDefined" 7 "LowerLevel" 6 "UpperLevel" 5 "CustomerLevel" 4 "PresetLevel" 3 "Norm~0xFFevel3" 2 "Norm~0xFFevel2" 1 "Norm~0xFFevel1" 0 "LevelNotSpecified";
VAL_ 2566909530 GrossCombinationVehicleWeight 65535 "Signal not available" 65279 "Error";
VAL_ 2566909530 GrossCombVehWghtConfidence 255 "Signal not available" 254 "Error";
VAL_ 2364551072 AdvancedemergencybrakingsystemstateAEBS1 15 "NotAvailable_NotInst~0xFFed" 14 "Error" 13 "ReservedForFutureUse" 12 "ReservedForFutureUse" 11 "CollisionWarningWithBraking（vehicleandpedestrian）" 10 "CollisionWarningActive（vehicleandpedestrian）" 9 "CollisionWarningWithBraking（pedestrian）" 8 "CollisionWarningActive（pedestrian）" 7 "EmergencyBrakingActive" 6 "CollisionWarningWithBraking（vehicle）" 5 "CollisionWarningActive（vehicle）" 4 "DriverOverridesSystem" 3 "SystemIsReadyAndActivated" 2 "SystemIsDeactivatedByDriver" 1 "SystemIsTemporarilyNotAvailable" 0 "SystemIsNotReady";
VAL_ 2364551072 Collision_warning_level 15 "notavailable/notinst~0xFFed" 14 "error" 13 "NotAvailable" 12 "NotAvailable" 11 "NotAvailable" 10 "NotAvailable" 9 "NotAvailable" 8 "NotAvailable" 7 "NotAvailable" 6 "NotAvailable" 5 "NotAvailable" 4 "warninglevel4人二级" 3 "warninglevel3车二级" 2 "warninglevel2人一级" 1 "warninglevel1-lowest车一级" 0 "nowarning";
VAL_ 2566856943 EM1TorqueModeDrivingBraking_ 15 "NotAvailable" 14 "Other" 13 "NotDefined" 12 "ServiceProcedure" 11 "RemoteAccelerator" 10 "BrakingSystem" 9 "HighSpeedGovernor" 8 "TorqueLimiting" 7 "ABSControl" 6 "TransmissionControl" 5 "ASRControl" 4 "RoadSpeedGovernor" 3 "PTOGovernor" 2 "CruiseControl" 1 "AcceleratorPedal_OperatorSelec" 0 "LowIdleGovernor_NoRequest";
VAL_ 2566840815 RetarderType_EF_ 15 "NotAvailable" 14 "Other" 5 "1101NotDefined" 4 "Exhaust" 3 "CompressionRelease" 2 "CooledFriction" 1 "Hyd" 0 "Electric_Magnetic";
VAL_ 2566840815 RetarderLocation_EF 15 "NotAvailable" 14 "Other" 6 "1101NotDefined" 5 "Trailer" 4 "Driveline" 3 "TransOutput" 2 "TransInput" 1 "EngExhaustBrake" 0 "EngCompressionReleaseBrake";
VAL_ 2566701807 PropulsionSystemActive_Ready 3 "Not Available" 2 "SAE Reserved" 1 "Propulsion System is ready to move, or is moving the vehicle as commanded by operator" 0 "Propulsion System is not ready to move vehicle if commanded by operator";
VAL_ 2431710879 ADAS_Posn_RelHead 255 "N/A" 254 "未知" 253 "与当前路径的逆时针夹角1.417度  (顺时针夹角358.583度)" 252 "在路径靠左的方向" 251 "在路径靠左的方向" 250 "在路径靠左的方向" 249 "在路径靠左的方向" 248 "在路径靠左的方向" 247 "在路径靠左的方向" 246 "在路径靠左的方向" 245 "在路径靠左的方向" 244 "在路径靠左的方向" 243 "在路径靠左的方向" 242 "在路径靠左的方向" 241 "在路径靠左的方向" 240 "在路径靠左的方向" 239 "在路径靠左的方向" 238 "在路径靠左的方向" 237 "在路径靠左的方向" 236 "在路径靠左的方向" 235 "在路径靠左的方向" 234 "在路径靠左的方向" 233 "在路径靠左的方向" 232 "在路径靠左的方向" 231 "在路径靠左的方向" 230 "在路径靠左的方向" 229 "在路径靠左的方向" 228 "在路径靠左的方向" 227 "在路径靠左的方向" 226 "在路径靠左的方向" 225 "在路径靠左的方向" 224 "在路径靠左的方向" 223 "在路径靠左的方向" 222 "在路径靠左的方向" 221 "在路径靠左的方向" 220 "在路径靠左的方向" 219 "在路径靠左的方向" 218 "在路径靠左的方向" 217 "在路径靠左的方向" 216 "在路径靠左的方向" 215 "在路径靠左的方向" 214 "在路径靠左的方向" 213 "在路径靠左的方向" 212 "在路径靠左的方向" 211 "在路径靠左的方向" 210 "在路径靠左的方向" 209 "在路径靠左的方向" 208 "在路径靠左的方向" 207 "在路径靠左的方向" 206 "在路径靠左的方向" 205 "在路径靠左的方向" 204 "在路径靠左的方向" 203 "在路径靠左的方向" 202 "在路径靠左的方向" 201 "在路径靠左的方向" 200 "在路径靠左的方向" 199 "在路径靠左的方向" 198 "在路径靠左的方向" 197 "在路径靠左的方向" 196 "在路径靠左的方向" 195 "在路径靠左的方向" 194 "在路径靠左的方向" 193 "在路径靠左的方向" 192 "在路径靠左的方向" 191 "在路径靠左的方向" 190 "在路径靠左的方向" 189 "在路径靠左的方向" 188 "在路径靠左的方向" 187 "在路径靠左的方向" 186 "在路径靠左的方向" 185 "在路径靠左的方向" 184 "在路径靠左的方向" 183 "在路径靠左的方向" 182 "在路径靠左的方向" 181 "在路径靠左的方向" 180 "在路径靠左的方向" 179 "在路径靠左的方向" 178 "在路径靠左的方向" 177 "在路径靠左的方向" 176 "在路径靠左的方向" 175 "在路径靠左的方向" 174 "在路径靠左的方向" 173 "在路径靠左的方向" 172 "在路径靠左的方向" 171 "在路径靠左的方向" 170 "在路径靠左的方向" 169 "在路径靠左的方向" 168 "在路径靠左的方向" 167 "在路径靠左的方向" 166 "在路径靠左的方向" 165 "在路径靠左的方向" 164 "在路径靠左的方向" 163 "在路径靠左的方向" 162 "在路径靠左的方向" 161 "在路径靠左的方向" 160 "在路径靠左的方向" 159 "在路径靠左的方向" 158 "在路径靠左的方向" 157 "在路径靠左的方向" 156 "在路径靠左的方向" 155 "在路径靠左的方向" 154 "在路径靠左的方向" 153 "在路径靠左的方向" 152 "在路径靠左的方向" 151 "在路径靠左的方向" 150 "在路径靠左的方向" 149 "在路径靠左的方向" 148 "在路径靠左的方向" 147 "在路径靠左的方向" 146 "在路径靠左的方向" 145 "在路径靠左的方向" 144 "在路径靠左的方向" 143 "在路径靠左的方向" 142 "在路径靠左的方向" 141 "在路径靠左的方向" 140 "在路径靠左的方向" 139 "在路径靠左的方向" 138 "在路径靠左的方向" 137 "在路径靠左的方向" 136 "在路径靠左的方向" 135 "在路径靠左的方向" 134 "在路径靠左的方向" 133 "在路径靠左的方向" 132 "在路径靠左的方向" 131 "在路径靠左的方向" 130 "在路径靠左的方向" 129 "在路径靠左的方向" 128 "与当前路径的逆时针夹角178.583度 (顺时针夹角181.417度)" 127 "与当前路径的方向相反" 126 "与当前路径的顺时针夹角178.583度" 125 "在路径靠右的方向" 124 "在路径靠右的方向" 123 "在路径靠右的方向" 122 "在路径靠右的方向" 121 "在路径靠右的方向" 120 "在路径靠右的方向" 119 "在路径靠右的方向" 118 "在路径靠右的方向" 117 "在路径靠右的方向" 116 "在路径靠右的方向" 115 "在路径靠右的方向" 114 "在路径靠右的方向" 113 "在路径靠右的方向" 112 "在路径靠右的方向" 111 "在路径靠右的方向" 110 "在路径靠右的方向" 109 "在路径靠右的方向" 108 "在路径靠右的方向" 107 "在路径靠右的方向" 106 "在路径靠右的方向" 105 "在路径靠右的方向" 104 "在路径靠右的方向" 103 "在路径靠右的方向" 102 "在路径靠右的方向" 101 "在路径靠右的方向" 100 "在路径靠右的方向" 99 "在路径靠右的方向" 98 "在路径靠右的方向" 97 "在路径靠右的方向" 96 "在路径靠右的方向" 95 "在路径靠右的方向" 94 "在路径靠右的方向" 93 "在路径靠右的方向" 92 "在路径靠右的方向" 91 "在路径靠右的方向" 90 "在路径靠右的方向" 89 "在路径靠右的方向" 88 "在路径靠右的方向" 87 "在路径靠右的方向" 86 "在路径靠右的方向" 85 "在路径靠右的方向" 84 "在路径靠右的方向" 83 "在路径靠右的方向" 82 "在路径靠右的方向" 81 "在路径靠右的方向" 80 "在路径靠右的方向" 79 "在路径靠右的方向" 78 "在路径靠右的方向" 77 "在路径靠右的方向" 76 "在路径靠右的方向" 75 "在路径靠右的方向" 74 "在路径靠右的方向" 73 "在路径靠右的方向" 72 "在路径靠右的方向" 71 "在路径靠右的方向" 70 "在路径靠右的方向" 69 "在路径靠右的方向" 68 "在路径靠右的方向" 67 "在路径靠右的方向" 66 "在路径靠右的方向" 65 "在路径靠右的方向" 64 "在路径靠右的方向" 63 "在路径靠右的方向" 62 "在路径靠右的方向" 61 "在路径靠右的方向" 60 "在路径靠右的方向" 59 "在路径靠右的方向" 58 "在路径靠右的方向" 57 "在路径靠右的方向" 56 "在路径靠右的方向" 55 "在路径靠右的方向" 54 "在路径靠右的方向" 53 "在路径靠右的方向" 52 "在路径靠右的方向" 51 "在路径靠右的方向" 50 "在路径靠右的方向" 49 "在路径靠右的方向" 48 "在路径靠右的方向" 47 "在路径靠右的方向" 46 "在路径靠右的方向" 45 "在路径靠右的方向" 44 "在路径靠右的方向" 43 "在路径靠右的方向" 42 "在路径靠右的方向" 41 "在路径靠右的方向" 40 "在路径靠右的方向" 39 "在路径靠右的方向" 38 "在路径靠右的方向" 37 "在路径靠右的方向" 36 "在路径靠右的方向" 35 "在路径靠右的方向" 34 "在路径靠右的方向" 33 "在路径靠右的方向" 32 "在路径靠右的方向" 31 "在路径靠右的方向" 30 "在路径靠右的方向" 29 "在路径靠右的方向" 28 "在路径靠右的方向" 27 "在路径靠右的方向" 26 "在路径靠右的方向" 25 "在路径靠右的方向" 24 "在路径靠右的方向" 23 "在路径靠右的方向" 22 "在路径靠右的方向" 21 "在路径靠右的方向" 20 "在路径靠右的方向" 19 "在路径靠右的方向" 18 "在路径靠右的方向" 17 "在路径靠右的方向" 16 "在路径靠右的方向" 15 "在路径靠右的方向" 14 "在路径靠右的方向" 13 "在路径靠右的方向" 12 "在路径靠右的方向" 11 "在路径靠右的方向" 10 "在路径靠右的方向" 9 "在路径靠右的方向" 8 "在路径靠右的方向" 7 "在路径靠右的方向" 6 "在路径靠右的方向" 5 "在路径靠右的方向" 4 "在路径靠右的方向" 3 "在路径靠右的方向" 2 "在路径靠右的方向" 1 "与当前路径的顺时针夹角1.417度" 0 "在当前路径方向";
VAL_ 2431710879 ADAS_Posn_Slope 1023 "N/A";
VAL_ 2431710879 ADAS_Posn_Confdc 7 "N/A" 6 "最低置信度" 0 "最高置信度";
VAL_ 2431710879 ADAS_Posn_Age 511 "N/A" 510 "消息发送时刻与定位子系统计算车辆位置之间的时间差 大于 2545 ms" 509 "消息发送时刻与定位子系统计算车辆位置之间的时间差为:0~2545 ms" 0 "消息发送时刻与定位子系统计算车辆位置之间的时间差为:0~2545 ms";
VAL_ 2431710879 ADAS_Posn_PosProbb 31 "N/A" 30 "位置的概率为 0~100%" 29 "位置的概率为 0~100%" 28 "位置的概率为 0~100%" 27 "位置的概率为 0~100%" 26 "位置的概率为 0~100%" 25 "位置的概率为 0~100%" 24 "位置的概率为 0~100%" 23 "位置的概率为 0~100%" 22 "位置的概率为 0~100%" 21 "位置的概率为 0~100%" 20 "位置的概率为 0~100%" 19 "位置的概率为 0~100%" 18 "位置的概率为 0~100%" 17 "位置的概率为 0~100%" 16 "位置的概率为 0~100%" 15 "位置的概率为 0~100%" 14 "位置的概率为 0~100%" 13 "位置的概率为 0~100%" 12 "位置的概率为 0~100%" 11 "位置的概率为 0~100%" 10 "位置的概率为 0~100%" 9 "位置的概率为 0~100%" 8 "位置的概率为 0~100%" 7 "位置的概率为 0~100%" 6 "位置的概率为 0~100%" 5 "位置的概率为 0~100%" 4 "位置的概率为 0~100%" 3 "位置的概率为 0~100%" 2 "位置的概率为 0~100%" 1 "位置的概率为 0~100%" 0 "位置的概率为 0~100%";
VAL_ 2431710879 ADAS_Posn_Idx 0 "代表最可能的位置，1次之。";
VAL_ 2431710879 ADAS_Posn_PathIdx 63 "当前路径的索引，当该值发生变化是，表明车辆已经到达一条新路径" 62 "当前路径的索引，当该值发生变化是，表明车辆已经到达一条新路径" 61 "当前路径的索引，当该值发生变化是，表明车辆已经到达一条新路径" 60 "当前路径的索引，当该值发生变化是，表明车辆已经到达一条新路径" 59 "当前路径的索引，当该值发生变化是，表明车辆已经到达一条新路径" 58 "当前路径的索引，当该值发生变化是，表明车辆已经到达一条新路径" 57 "当前路径的索引，当该值发生变化是，表明车辆已经到达一条新路径" 56 "当前路径的索引，当该值发生变化是，表明车辆已经到达一条新路径" 55 "当前路径的索引，当该值发生变化是，表明车辆已经到达一条新路径" 54 "当前路径的索引，当该值发生变化是，表明车辆已经到达一条新路径" 53 "当前路径的索引，当该值发生变化是，表明车辆已经到达一条新路径" 52 "当前路径的索引，当该值发生变化是，表明车辆已经到达一条新路径" 51 "当前路径的索引，当该值发生变化是，表明车辆已经到达一条新路径" 50 "当前路径的索引，当该值发生变化是，表明车辆已经到达一条新路径" 49 "当前路径的索引，当该值发生变化是，表明车辆已经到达一条新路径" 48 "当前路径的索引，当该值发生变化是，表明车辆已经到达一条新路径" 47 "当前路径的索引，当该值发生变化是，表明车辆已经到达一条新路径" 46 "当前路径的索引，当该值发生变化是，表明车辆已经到达一条新路径" 45 "当前路径的索引，当该值发生变化是，表明车辆已经到达一条新路径" 44 "当前路径的索引，当该值发生变化是，表明车辆已经到达一条新路径" 43 "当前路径的索引，当该值发生变化是，表明车辆已经到达一条新路径" 42 "当前路径的索引，当该值发生变化是，表明车辆已经到达一条新路径" 41 "当前路径的索引，当该值发生变化是，表明车辆已经到达一条新路径" 40 "当前路径的索引，当该值发生变化是，表明车辆已经到达一条新路径" 39 "当前路径的索引，当该值发生变化是，表明车辆已经到达一条新路径" 38 "当前路径的索引，当该值发生变化是，表明车辆已经到达一条新路径" 37 "当前路径的索引，当该值发生变化是，表明车辆已经到达一条新路径" 36 "当前路径的索引，当该值发生变化是，表明车辆已经到达一条新路径" 35 "当前路径的索引，当该值发生变化是，表明车辆已经到达一条新路径" 34 "当前路径的索引，当该值发生变化是，表明车辆已经到达一条新路径" 33 "当前路径的索引，当该值发生变化是，表明车辆已经到达一条新路径" 32 "当前路径的索引，当该值发生变化是，表明车辆已经到达一条新路径" 31 "当前路径的索引，当该值发生变化是，表明车辆已经到达一条新路径" 30 "当前路径的索引，当该值发生变化是，表明车辆已经到达一条新路径" 29 "当前路径的索引，当该值发生变化是，表明车辆已经到达一条新路径" 28 "当前路径的索引，当该值发生变化是，表明车辆已经到达一条新路径" 27 "当前路径的索引，当该值发生变化是，表明车辆已经到达一条新路径" 26 "当前路径的索引，当该值发生变化是，表明车辆已经到达一条新路径" 25 "当前路径的索引，当该值发生变化是，表明车辆已经到达一条新路径" 24 "当前路径的索引，当该值发生变化是，表明车辆已经到达一条新路径" 23 "当前路径的索引，当该值发生变化是，表明车辆已经到达一条新路径" 22 "当前路径的索引，当该值发生变化是，表明车辆已经到达一条新路径" 21 "当前路径的索引，当该值发生变化是，表明车辆已经到达一条新路径" 20 "当前路径的索引，当该值发生变化是，表明车辆已经到达一条新路径" 19 "当前路径的索引，当该值发生变化是，表明车辆已经到达一条新路径" 18 "当前路径的索引，当该值发生变化是，表明车辆已经到达一条新路径" 17 "当前路径的索引，当该值发生变化是，表明车辆已经到达一条新路径" 16 "当前路径的索引，当该值发生变化是，表明车辆已经到达一条新路径" 15 "当前路径的索引，当该值发生变化是，表明车辆已经到达一条新路径" 14 "当前路径的索引，当该值发生变化是，表明车辆已经到达一条新路径" 13 "当前路径的索引，当该值发生变化是，表明车辆已经到达一条新路径" 12 "当前路径的索引，当该值发生变化是，表明车辆已经到达一条新路径" 11 "当前路径的索引，当该值发生变化是，表明车辆已经到达一条新路径" 10 "当前路径的索引，当该值发生变化是，表明车辆已经到达一条新路径" 9 "当前路径的索引，当该值发生变化是，表明车辆已经到达一条新路径" 8 "当前路径的索引，当该值发生变化是，表明车辆已经到达一条新路径" 7 "N/A" 6 "表示STUB消息用于传输交叉口主路径的航向变化E和相对概率" 5 "表示存在不会被路径数据追加的十字路口分支" 4 "具有此路径索引的消息仅指当前车辆位置段" 3 "Av2HP 车辆定位子系统没有校准" 2 "位置不在道路上" 1 "位置不在数字化区域" 0 "未知";
VAL_ 2431710879 ADAS_Posn_CycCnt 3 "此消息类型的循环计数为3（下一次发送该消息类型的循环计数为0）" 2 "此消息类型的循环计数为2" 1 "此消息类型的循环计数为1" 0 "此消息类型的循环计数为0";
VAL_ 2431710879 ADAS_Posn_Offset 8191 "N/A" 510 "车辆位置的偏移范围0~8190m" 0 "车辆位置的偏移范围0~8190m";
VAL_ 2431710879 ADAS_Posn_MsgTyp 7 "N/A" 6 "META-DATA消息类型" 5 "PROFILE LONG消息类型" 4 "PROFILE SHORT消息类型" 3 "STUB消息类型" 2 "SEGMENT消息类型" 1 "POSITION消息类型" 0 "System specific消息类型";
VAL_ 2498819743 ADAS_Stub_NumOfLaneDrvDir 7 "N/A." 6 "6车道或者更多." 5 "表示相应的车道数（0~5 lanes）" 4 "表示相应的车道数（0~5 lanes）" 3 "表示相应的车道数（0~5 lanes）" 2 "表示相应的车道数（0~5 lanes）" 1 "表示相应的车道数（0~5 lanes）" 0 "表示在错误方向上行驶的单向道路";
VAL_ 2498819743 ADAS_Stub_NumOfLaneOppDir 3 "无效值" 2 "表示两条或以上的车道线" 1 "表示一条车道线" 0 "表示单行车道";
VAL_ 2498819743 ADAS_Stub_RtOfWay 3 "N/A" 2 "未知" 1 "相对于路径冲突车辆，该车辆需避让" 0 "相对于路径冲突车辆，该车具有优先路权";
VAL_ 2498819743 ADAS_Stub_LastStub 1 "表示该stub是当前路径上的最后一个stub" 0 "表示路径后方还有其他的stub消息将发送";
VAL_ 2498819743 ADAS_Stub_TurnAngl 255 "N/A" 254 "未知" 253 "1.417 度偏左 (358.583度偏右)" 252 "车道偏左" 251 "车道偏左" 250 "车道偏左" 249 "车道偏左" 248 "车道偏左" 247 "车道偏左" 246 "车道偏左" 245 "车道偏左" 244 "车道偏左" 243 "车道偏左" 242 "车道偏左" 241 "车道偏左" 240 "车道偏左" 239 "车道偏左" 238 "车道偏左" 237 "车道偏左" 236 "车道偏左" 235 "车道偏左" 234 "车道偏左" 233 "车道偏左" 232 "车道偏左" 231 "车道偏左" 230 "车道偏左" 229 "车道偏左" 228 "车道偏左" 227 "车道偏左" 226 "车道偏左" 225 "车道偏左" 224 "车道偏左" 223 "车道偏左" 222 "车道偏左" 221 "车道偏左" 220 "车道偏左" 219 "车道偏左" 218 "车道偏左" 217 "车道偏左" 216 "车道偏左" 215 "车道偏左" 214 "车道偏左" 213 "车道偏左" 212 "车道偏左" 211 "车道偏左" 210 "车道偏左" 209 "车道偏左" 208 "车道偏左" 207 "车道偏左" 206 "车道偏左" 205 "车道偏左" 204 "车道偏左" 203 "车道偏左" 202 "车道偏左" 201 "车道偏左" 200 "车道偏左" 199 "车道偏左" 198 "车道偏左" 197 "车道偏左" 196 "车道偏左" 195 "车道偏左" 194 "车道偏左" 193 "车道偏左" 192 "车道偏左" 191 "车道偏左" 190 "车道偏左" 189 "车道偏左" 188 "车道偏左" 187 "车道偏左" 186 "车道偏左" 185 "车道偏左" 184 "车道偏左" 183 "车道偏左" 182 "车道偏左" 181 "车道偏左" 180 "车道偏左" 179 "车道偏左" 178 "车道偏左" 177 "车道偏左" 176 "车道偏左" 175 "车道偏左" 174 "车道偏左" 173 "车道偏左" 172 "车道偏左" 171 "车道偏左" 170 "车道偏左" 169 "车道偏左" 168 "车道偏左" 167 "车道偏左" 166 "车道偏左" 165 "车道偏左" 164 "车道偏左" 163 "车道偏左" 162 "车道偏左" 161 "车道偏左" 160 "车道偏左" 159 "车道偏左" 158 "车道偏左" 157 "车道偏左" 156 "车道偏左" 155 "车道偏左" 154 "车道偏左" 153 "车道偏左" 152 "车道偏左" 151 "车道偏左" 150 "车道偏左" 149 "车道偏左" 148 "车道偏左" 147 "车道偏左" 146 "车道偏左" 145 "车道偏左" 144 "车道偏左" 143 "车道偏左" 142 "车道偏左" 141 "车道偏左" 140 "车道偏左" 139 "车道偏左" 138 "车道偏左" 137 "车道偏左" 136 "车道偏左" 135 "车道偏左" 134 "车道偏左" 133 "车道偏左" 132 "车道偏左" 131 "车道偏左" 130 "车道偏左" 129 "车道偏左" 128 "178.583 度偏左 (181.417 度偏右)" 127 "相反方向" 126 "178.583 度偏右" 125 "车道偏右" 124 "车道偏右" 123 "车道偏右" 122 "车道偏右" 121 "车道偏右" 120 "车道偏右" 119 "车道偏右" 118 "车道偏右" 117 "车道偏右" 116 "车道偏右" 115 "车道偏右" 114 "车道偏右" 113 "车道偏右" 112 "车道偏右" 111 "车道偏右" 110 "车道偏右" 109 "车道偏右" 108 "车道偏右" 107 "车道偏右" 106 "车道偏右" 105 "车道偏右" 104 "车道偏右" 103 "车道偏右" 102 "车道偏右" 101 "车道偏右" 100 "车道偏右" 99 "车道偏右" 98 "车道偏右" 97 "车道偏右" 96 "车道偏右" 95 "车道偏右" 94 "车道偏右" 93 "车道偏右" 92 "车道偏右" 91 "车道偏右" 90 "车道偏右" 89 "车道偏右" 88 "车道偏右" 87 "车道偏右" 86 "车道偏右" 85 "车道偏右" 84 "车道偏右" 83 "车道偏右" 82 "车道偏右" 81 "车道偏右" 80 "车道偏右" 79 "车道偏右" 78 "车道偏右" 77 "车道偏右" 76 "车道偏右" 75 "车道偏右" 74 "车道偏右" 73 "车道偏右" 72 "车道偏右" 71 "车道偏右" 70 "车道偏右" 69 "车道偏右" 68 "车道偏右" 67 "车道偏右" 66 "车道偏右" 65 "车道偏右" 64 "车道偏右" 63 "车道偏右" 62 "车道偏右" 61 "车道偏右" 60 "车道偏右" 59 "车道偏右" 58 "车道偏右" 57 "车道偏右" 56 "车道偏右" 55 "车道偏右" 54 "车道偏右" 53 "车道偏右" 52 "车道偏右" 51 "车道偏右" 50 "车道偏右" 49 "车道偏右" 48 "车道偏右" 47 "车道偏右" 46 "车道偏右" 45 "车道偏右" 44 "车道偏右" 43 "车道偏右" 42 "车道偏右" 41 "车道偏右" 40 "车道偏右" 39 "车道偏右" 38 "车道偏右" 37 "车道偏右" 36 "车道偏右" 35 "车道偏右" 34 "车道偏右" 33 "车道偏右" 32 "车道偏右" 31 "车道偏右" 30 "车道偏右" 29 "车道偏右" 28 "车道偏右" 27 "车道偏右" 26 "车道偏右" 25 "车道偏右" 24 "车道偏右" 23 "车道偏右" 22 "车道偏右" 21 "车道偏右" 20 "车道偏右" 19 "车道偏右" 18 "车道偏右" 17 "车道偏右" 16 "车道偏右" 15 "车道偏右" 14 "车道偏右" 13 "车道偏右" 12 "车道偏右" 11 "车道偏右" 10 "车道偏右" 9 "车道偏右" 8 "车道偏右" 7 "车道偏右" 6 "车道偏右" 5 "车道偏右" 4 "车道偏右" 3 "车道偏右" 2 "车道偏右" 1 "1.417度偏右" 0 "在车道方向";
VAL_ 2498819743 ADAS_Stub_FormOfWay_ 15 "N/A" 14 "步行区" 13 "进入或退出服务区" 12 "进入或离开停车场" 11 "服务区道路或临街道路" 10 "滑行道/坡道（不在高速公路或受控通道上）" 9 "高速公路或受控通道上的滑行道/坡道" 8 "平行道路（作为支路/坡道的特殊类型）" 7 "预留" 6 "预留" 5 "交通广场/特殊交通图" 4 "环形路段" 3 "单车道（默认）" 2 "多车道或数字化道路" 1 "高速公路或受控道路，不是支路/坡道" 0 "未知";
VAL_ 2498819743 ADAS_Stub_CmplxInsct 3 "N/A" 2 "未知" 1 "新路径是复杂交叉路口的一部分。" 0 "新路径不是复杂交叉路口的一部分";
VAL_ 2498819743 ADAS_Stub_PartOfCalcRoute 3 "N/A" 2 "未知" 1 "从这一点开始的新路径是计算路线的一部分" 0 "从这一点开始的新路径不是计算路线的一部分";
VAL_ 2498819743 ADAS_Stub_FuncRoadClass 7 "N/A" 0 "未知";
VAL_ 2498819743 ADAS_Stub_RelProbb 31 "N/A" 30 "0~100%，在交叉路口的stub对应新路径的概率，所有stub的概率和为1" 29 "0~100%，在交叉路口的stub对应新路径的概率，所有stub的概率和为1" 28 "0~100%，在交叉路口的stub对应新路径的概率，所有stub的概率和为1" 27 "0~100%，在交叉路口的stub对应新路径的概率，所有stub的概率和为1" 26 "0~100%，在交叉路口的stub对应新路径的概率，所有stub的概率和为1" 25 "0~100%，在交叉路口的stub对应新路径的概率，所有stub的概率和为1" 24 "0~100%，在交叉路口的stub对应新路径的概率，所有stub的概率和为1" 23 "0~100%，在交叉路口的stub对应新路径的概率，所有stub的概率和为1" 22 "0~100%，在交叉路口的stub对应新路径的概率，所有stub的概率和为1" 21 "0~100%，在交叉路口的stub对应新路径的概率，所有stub的概率和为1" 20 "0~100%，在交叉路口的stub对应新路径的概率，所有stub的概率和为1" 19 "0~100%，在交叉路口的stub对应新路径的概率，所有stub的概率和为1" 18 "0~100%，在交叉路口的stub对应新路径的概率，所有stub的概率和为1" 17 "0~100%，在交叉路口的stub对应新路径的概率，所有stub的概率和为1" 16 "0~100%，在交叉路口的stub对应新路径的概率，所有stub的概率和为1" 15 "0~100%，在交叉路口的stub对应新路径的概率，所有stub的概率和为1" 14 "0~100%，在交叉路口的stub对应新路径的概率，所有stub的概率和为1" 13 "0~100%，在交叉路口的stub对应新路径的概率，所有stub的概率和为1" 12 "0~100%，在交叉路口的stub对应新路径的概率，所有stub的概率和为1" 11 "0~100%，在交叉路口的stub对应新路径的概率，所有stub的概率和为1" 10 "0~100%，在交叉路口的stub对应新路径的概率，所有stub的概率和为1" 9 "0~100%，在交叉路口的stub对应新路径的概率，所有stub的概率和为1" 8 "0~100%，在交叉路口的stub对应新路径的概率，所有stub的概率和为1" 7 "0~100%，在交叉路口的stub对应新路径的概率，所有stub的概率和为1" 6 "0~100%，在交叉路口的stub对应新路径的概率，所有stub的概率和为1" 5 "0~100%，在交叉路口的stub对应新路径的概率，所有stub的概率和为1" 4 "0~100%，在交叉路口的stub对应新路径的概率，所有stub的概率和为1" 3 "0~100%，在交叉路口的stub对应新路径的概率，所有stub的概率和为1" 2 "0~100%，在交叉路口的stub对应新路径的概率，所有stub的概率和为1" 1 "0~100%，在交叉路口的stub对应新路径的概率，所有stub的概率和为1" 0 "0~100%，在交叉路口的stub对应新路径的概率，所有stub的概率和为1";
VAL_ 2498819743 ADAS_Stub_Update 1 "该消息无更新" 0 "表明该消息在已经发送过的消息中有信息更新了";
VAL_ 2498819743 ADAS_Stub_Retr 1 "表明该消息是第一次发送" 0 "表明该消息至少已经发送过一次";
VAL_ 2498819743 ADAS_Stub_SubPathIdx 63 "“正常”的STUB消息，代表新路径的索引，包含新路径的来源，引用此索引值的后续消息将提供有关它的更多数据。" 62 "“正常”的STUB消息，代表新路径的索引，包含新路径的来源，引用此索引值的后续消息将提供有关它的更多数据。" 61 "“正常”的STUB消息，代表新路径的索引，包含新路径的来源，引用此索引值的后续消息将提供有关它的更多数据。" 60 "“正常”的STUB消息，代表新路径的索引，包含新路径的来源，引用此索引值的后续消息将提供有关它的更多数据。" 59 "“正常”的STUB消息，代表新路径的索引，包含新路径的来源，引用此索引值的后续消息将提供有关它的更多数据。" 58 "“正常”的STUB消息，代表新路径的索引，包含新路径的来源，引用此索引值的后续消息将提供有关它的更多数据。" 57 "“正常”的STUB消息，代表新路径的索引，包含新路径的来源，引用此索引值的后续消息将提供有关它的更多数据。" 56 "“正常”的STUB消息，代表新路径的索引，包含新路径的来源，引用此索引值的后续消息将提供有关它的更多数据。" 55 "“正常”的STUB消息，代表新路径的索引，包含新路径的来源，引用此索引值的后续消息将提供有关它的更多数据。" 54 "“正常”的STUB消息，代表新路径的索引，包含新路径的来源，引用此索引值的后续消息将提供有关它的更多数据。" 53 "“正常”的STUB消息，代表新路径的索引，包含新路径的来源，引用此索引值的后续消息将提供有关它的更多数据。" 52 "“正常”的STUB消息，代表新路径的索引，包含新路径的来源，引用此索引值的后续消息将提供有关它的更多数据。" 51 "“正常”的STUB消息，代表新路径的索引，包含新路径的来源，引用此索引值的后续消息将提供有关它的更多数据。" 50 "“正常”的STUB消息，代表新路径的索引，包含新路径的来源，引用此索引值的后续消息将提供有关它的更多数据。" 49 "“正常”的STUB消息，代表新路径的索引，包含新路径的来源，引用此索引值的后续消息将提供有关它的更多数据。" 48 "“正常”的STUB消息，代表新路径的索引，包含新路径的来源，引用此索引值的后续消息将提供有关它的更多数据。" 47 "“正常”的STUB消息，代表新路径的索引，包含新路径的来源，引用此索引值的后续消息将提供有关它的更多数据。" 46 "“正常”的STUB消息，代表新路径的索引，包含新路径的来源，引用此索引值的后续消息将提供有关它的更多数据。" 45 "“正常”的STUB消息，代表新路径的索引，包含新路径的来源，引用此索引值的后续消息将提供有关它的更多数据。" 44 "“正常”的STUB消息，代表新路径的索引，包含新路径的来源，引用此索引值的后续消息将提供有关它的更多数据。" 43 "“正常”的STUB消息，代表新路径的索引，包含新路径的来源，引用此索引值的后续消息将提供有关它的更多数据。" 42 "“正常”的STUB消息，代表新路径的索引，包含新路径的来源，引用此索引值的后续消息将提供有关它的更多数据。" 41 "“正常”的STUB消息，代表新路径的索引，包含新路径的来源，引用此索引值的后续消息将提供有关它的更多数据。" 40 "“正常”的STUB消息，代表新路径的索引，包含新路径的来源，引用此索引值的后续消息将提供有关它的更多数据。" 39 "“正常”的STUB消息，代表新路径的索引，包含新路径的来源，引用此索引值的后续消息将提供有关它的更多数据。" 38 "“正常”的STUB消息，代表新路径的索引，包含新路径的来源，引用此索引值的后续消息将提供有关它的更多数据。" 37 "“正常”的STUB消息，代表新路径的索引，包含新路径的来源，引用此索引值的后续消息将提供有关它的更多数据。" 36 "“正常”的STUB消息，代表新路径的索引，包含新路径的来源，引用此索引值的后续消息将提供有关它的更多数据。" 35 "“正常”的STUB消息，代表新路径的索引，包含新路径的来源，引用此索引值的后续消息将提供有关它的更多数据。" 34 "“正常”的STUB消息，代表新路径的索引，包含新路径的来源，引用此索引值的后续消息将提供有关它的更多数据。" 33 "“正常”的STUB消息，代表新路径的索引，包含新路径的来源，引用此索引值的后续消息将提供有关它的更多数据。" 32 "“正常”的STUB消息，代表新路径的索引，包含新路径的来源，引用此索引值的后续消息将提供有关它的更多数据。" 31 "“正常”的STUB消息，代表新路径的索引，包含新路径的来源，引用此索引值的后续消息将提供有关它的更多数据。" 30 "“正常”的STUB消息，代表新路径的索引，包含新路径的来源，引用此索引值的后续消息将提供有关它的更多数据。" 29 "“正常”的STUB消息，代表新路径的索引，包含新路径的来源，引用此索引值的后续消息将提供有关它的更多数据。" 28 "“正常”的STUB消息，代表新路径的索引，包含新路径的来源，引用此索引值的后续消息将提供有关它的更多数据。" 27 "“正常”的STUB消息，代表新路径的索引，包含新路径的来源，引用此索引值的后续消息将提供有关它的更多数据。" 26 "“正常”的STUB消息，代表新路径的索引，包含新路径的来源，引用此索引值的后续消息将提供有关它的更多数据。" 25 "“正常”的STUB消息，代表新路径的索引，包含新路径的来源，引用此索引值的后续消息将提供有关它的更多数据。" 24 "“正常”的STUB消息，代表新路径的索引，包含新路径的来源，引用此索引值的后续消息将提供有关它的更多数据。" 23 "“正常”的STUB消息，代表新路径的索引，包含新路径的来源，引用此索引值的后续消息将提供有关它的更多数据。" 22 "“正常”的STUB消息，代表新路径的索引，包含新路径的来源，引用此索引值的后续消息将提供有关它的更多数据。" 21 "“正常”的STUB消息，代表新路径的索引，包含新路径的来源，引用此索引值的后续消息将提供有关它的更多数据。" 20 "“正常”的STUB消息，代表新路径的索引，包含新路径的来源，引用此索引值的后续消息将提供有关它的更多数据。" 19 "“正常”的STUB消息，代表新路径的索引，包含新路径的来源，引用此索引值的后续消息将提供有关它的更多数据。" 18 "“正常”的STUB消息，代表新路径的索引，包含新路径的来源，引用此索引值的后续消息将提供有关它的更多数据。" 17 "“正常”的STUB消息，代表新路径的索引，包含新路径的来源，引用此索引值的后续消息将提供有关它的更多数据。" 16 "“正常”的STUB消息，代表新路径的索引，包含新路径的来源，引用此索引值的后续消息将提供有关它的更多数据。" 15 "“正常”的STUB消息，代表新路径的索引，包含新路径的来源，引用此索引值的后续消息将提供有关它的更多数据。" 14 "“正常”的STUB消息，代表新路径的索引，包含新路径的来源，引用此索引值的后续消息将提供有关它的更多数据。" 13 "“正常”的STUB消息，代表新路径的索引，包含新路径的来源，引用此索引值的后续消息将提供有关它的更多数据。" 12 "“正常”的STUB消息，代表新路径的索引，包含新路径的来源，引用此索引值的后续消息将提供有关它的更多数据。" 11 "“正常”的STUB消息，代表新路径的索引，包含新路径的来源，引用此索引值的后续消息将提供有关它的更多数据。" 10 "“正常”的STUB消息，代表新路径的索引，包含新路径的来源，引用此索引值的后续消息将提供有关它的更多数据。" 9 "“正常”的STUB消息，代表新路径的索引，包含新路径的来源，引用此索引值的后续消息将提供有关它的更多数据。" 8 "“正常”的STUB消息，代表新路径的索引，包含新路径的来源，引用此索引值的后续消息将提供有关它的更多数据。" 6 "代表主路径的延续，提供了主路径延续的信息，例如TURN ANGLE和RELATIVE PROBABILITY。" 5 "对于这些STUB，不会附加任何分支路径的信息，此Stub类型通常用于具有极低带宽或存储容量的系统，或用于非常低概率分支或在交叉路口处不允许转弯的系统。 如果车辆转向具有路径索引为5的路口，则Av2HP必须启动新路径。 通常，仅提供“单路径地平线与Stub”的Av2HP会发送SUB-PATH INDEX值为5的STUB消息.";
VAL_ 2498819743 ADAS_Stub_PathIdx 63 "当前路径的索引，当该值发生变化时，表明车辆已经到达一条新路径" 62 "当前路径的索引，当该值发生变化时，表明车辆已经到达一条新路径" 61 "当前路径的索引，当该值发生变化时，表明车辆已经到达一条新路径" 60 "当前路径的索引，当该值发生变化时，表明车辆已经到达一条新路径" 59 "当前路径的索引，当该值发生变化时，表明车辆已经到达一条新路径" 58 "当前路径的索引，当该值发生变化时，表明车辆已经到达一条新路径" 57 "当前路径的索引，当该值发生变化时，表明车辆已经到达一条新路径" 56 "当前路径的索引，当该值发生变化时，表明车辆已经到达一条新路径" 55 "当前路径的索引，当该值发生变化时，表明车辆已经到达一条新路径" 54 "当前路径的索引，当该值发生变化时，表明车辆已经到达一条新路径" 53 "当前路径的索引，当该值发生变化时，表明车辆已经到达一条新路径" 52 "当前路径的索引，当该值发生变化时，表明车辆已经到达一条新路径" 51 "当前路径的索引，当该值发生变化时，表明车辆已经到达一条新路径" 50 "当前路径的索引，当该值发生变化时，表明车辆已经到达一条新路径" 49 "当前路径的索引，当该值发生变化时，表明车辆已经到达一条新路径" 48 "当前路径的索引，当该值发生变化时，表明车辆已经到达一条新路径" 47 "当前路径的索引，当该值发生变化时，表明车辆已经到达一条新路径" 46 "当前路径的索引，当该值发生变化时，表明车辆已经到达一条新路径" 45 "当前路径的索引，当该值发生变化时，表明车辆已经到达一条新路径" 44 "当前路径的索引，当该值发生变化时，表明车辆已经到达一条新路径" 43 "当前路径的索引，当该值发生变化时，表明车辆已经到达一条新路径" 42 "当前路径的索引，当该值发生变化时，表明车辆已经到达一条新路径" 41 "当前路径的索引，当该值发生变化时，表明车辆已经到达一条新路径" 40 "当前路径的索引，当该值发生变化时，表明车辆已经到达一条新路径" 39 "当前路径的索引，当该值发生变化时，表明车辆已经到达一条新路径" 38 "当前路径的索引，当该值发生变化时，表明车辆已经到达一条新路径" 37 "当前路径的索引，当该值发生变化时，表明车辆已经到达一条新路径" 36 "当前路径的索引，当该值发生变化时，表明车辆已经到达一条新路径" 35 "当前路径的索引，当该值发生变化时，表明车辆已经到达一条新路径" 34 "当前路径的索引，当该值发生变化时，表明车辆已经到达一条新路径" 33 "当前路径的索引，当该值发生变化时，表明车辆已经到达一条新路径" 32 "当前路径的索引，当该值发生变化时，表明车辆已经到达一条新路径" 31 "当前路径的索引，当该值发生变化时，表明车辆已经到达一条新路径" 30 "当前路径的索引，当该值发生变化时，表明车辆已经到达一条新路径" 29 "当前路径的索引，当该值发生变化时，表明车辆已经到达一条新路径" 28 "当前路径的索引，当该值发生变化时，表明车辆已经到达一条新路径" 27 "当前路径的索引，当该值发生变化时，表明车辆已经到达一条新路径" 26 "当前路径的索引，当该值发生变化时，表明车辆已经到达一条新路径" 25 "当前路径的索引，当该值发生变化时，表明车辆已经到达一条新路径" 24 "当前路径的索引，当该值发生变化时，表明车辆已经到达一条新路径" 23 "当前路径的索引，当该值发生变化时，表明车辆已经到达一条新路径" 22 "当前路径的索引，当该值发生变化时，表明车辆已经到达一条新路径" 21 "当前路径的索引，当该值发生变化时，表明车辆已经到达一条新路径" 20 "当前路径的索引，当该值发生变化时，表明车辆已经到达一条新路径" 19 "当前路径的索引，当该值发生变化时，表明车辆已经到达一条新路径" 18 "当前路径的索引，当该值发生变化时，表明车辆已经到达一条新路径" 17 "当前路径的索引，当该值发生变化时，表明车辆已经到达一条新路径" 16 "当前路径的索引，当该值发生变化时，表明车辆已经到达一条新路径" 15 "当前路径的索引，当该值发生变化时，表明车辆已经到达一条新路径" 14 "当前路径的索引，当该值发生变化时，表明车辆已经到达一条新路径" 13 "当前路径的索引，当该值发生变化时，表明车辆已经到达一条新路径" 12 "当前路径的索引，当该值发生变化时，表明车辆已经到达一条新路径" 11 "当前路径的索引，当该值发生变化时，表明车辆已经到达一条新路径" 10 "当前路径的索引，当该值发生变化时，表明车辆已经到达一条新路径" 9 "当前路径的索引，当该值发生变化时，表明车辆已经到达一条新路径" 8 "当前路径的索引，当该值发生变化时，表明车辆已经到达一条新路径" 7 "N/A" 6 "表示STUB消息用于传输交叉口主路径的航向变化和相对概率" 5 "表示存在不会被路径数据追加的十字路口分支" 4 "具有此路径索引的消息仅指当前车辆位置段" 3 "Av2HP 车辆定位子系统没有校准" 2 "位置不在道路上" 1 "位置不在数字化区域" 0 "未知";
VAL_ 2498819743 ADAS_Stub_CycCnt 3 "此消息类型的循环计数为3（下一次发送该消息类型的循环计数为0）" 2 "此消息类型的循环计数为2" 1 "此消息类型的循环计数为1" 0 "此消息类型的循环计数为0";
VAL_ 2498819743 ADAS_Stub_Offset 8191 "N/A" 510 "0~8190m，岔路口位置与路径起点的距离对8191取余" 0 "0~8190m，岔路口位置与路径起点的距离对8191取余";
VAL_ 2498819743 ADAS_Stub_MsgType 7 "N/A" 6 "META-DATA消息类型" 5 "PROFILE LONG消息类型" 4 "PROFILE SHORT消息类型" 3 "STUB消息类型" 2 "SEGMENT消息类型" 1 "POSITION消息类型" 0 "System specific消息类型";
VAL_ 2565928863 ADAS_ProfShort_Value1 1023 "N/A";
VAL_ 2565928863 ADAS_ProfShort_Value0 1023 "N/A";
VAL_ 2565928863 ADAS_ProfShort_Dist1 1023 "N/A" 1022 "0~1022m，第一个行点到第二个行点的距离，不超过1023" 0 "0~1022m，第一个行点到第二个行点的距离，不超过1023";
VAL_ 2565928863 ADAS_ProfShort_AccurClass 3 "精度未知" 2 "最低精度." 1 "中等精度." 0 "最高精度";
VAL_ 2565928863 ADAS_ProfShort_Update 1 "表明该消息在已经发送过的消息中有信息更新了" 0 "该消息未更新";
VAL_ 2565928863 ADAS_ProfShort_Retr 1 "表明该消息至少已经发送过一次" 0 "表明该消息是第一次发送";
VAL_ 2565928863 ADAS_ProfShort_CtrlPoint 1 "表明消息中的值是进行插值所需要的控制点" 0 "非控制点";
VAL_ 2565928863 ADAS_ProfShort_ProfType 31 "保留用于系统特定类型" 30 "保留用于系统特定类型" 29 "保留用于系统特定类型" 28 "保留用于系统特定类型" 27 "保留用于系统特定类型" 26 "保留用于系统特定类型" 25 "保留用于系统特定类型" 24 "保留用于系统特定类型" 23 "保留用于系统特定类型" 22 "保留用于系统特定类型" 21 "保留用于系统特定类型" 20 "保留用于系统特定类型" 19 "保留用于系统特定类型" 18 "保留用于系统特定类型" 17 "保留用于系统特定类型" 16 "保留用于系统特定类型" 15 "保留用于标准类型" 14 "保留用于标准类型" 13 "保留用于标准类型" 12 "保留用于标准类型" 11 "保留用于标准类型" 10 "保留用于标准类型" 9 "保留用于标准类型" 8 "航向的变化" 7 "变速标志位置" 6 "路况" 5 "道路可通行性" 4 "坡度（线性插值方式）" 3 "坡度（step插值方式）" 2 "路线编号类型" 1 "曲率" 0 "N/A";
VAL_ 2565928863 ADAS_ProfShort_PathIdx 63 "当前路径的索引，当该值发生变化是，表明车辆已经到达一条新路径" 62 "当前路径的索引，当该值发生变化是，表明车辆已经到达一条新路径" 61 "当前路径的索引，当该值发生变化是，表明车辆已经到达一条新路径" 60 "当前路径的索引，当该值发生变化是，表明车辆已经到达一条新路径" 59 "当前路径的索引，当该值发生变化是，表明车辆已经到达一条新路径" 58 "当前路径的索引，当该值发生变化是，表明车辆已经到达一条新路径" 57 "当前路径的索引，当该值发生变化是，表明车辆已经到达一条新路径" 56 "当前路径的索引，当该值发生变化是，表明车辆已经到达一条新路径" 55 "当前路径的索引，当该值发生变化是，表明车辆已经到达一条新路径" 54 "当前路径的索引，当该值发生变化是，表明车辆已经到达一条新路径" 53 "当前路径的索引，当该值发生变化是，表明车辆已经到达一条新路径" 52 "当前路径的索引，当该值发生变化是，表明车辆已经到达一条新路径" 51 "当前路径的索引，当该值发生变化是，表明车辆已经到达一条新路径" 50 "当前路径的索引，当该值发生变化是，表明车辆已经到达一条新路径" 49 "当前路径的索引，当该值发生变化是，表明车辆已经到达一条新路径" 48 "当前路径的索引，当该值发生变化是，表明车辆已经到达一条新路径" 47 "当前路径的索引，当该值发生变化是，表明车辆已经到达一条新路径" 46 "当前路径的索引，当该值发生变化是，表明车辆已经到达一条新路径" 45 "当前路径的索引，当该值发生变化是，表明车辆已经到达一条新路径" 44 "当前路径的索引，当该值发生变化是，表明车辆已经到达一条新路径" 43 "当前路径的索引，当该值发生变化是，表明车辆已经到达一条新路径" 42 "当前路径的索引，当该值发生变化是，表明车辆已经到达一条新路径" 41 "当前路径的索引，当该值发生变化是，表明车辆已经到达一条新路径" 40 "当前路径的索引，当该值发生变化是，表明车辆已经到达一条新路径" 39 "当前路径的索引，当该值发生变化是，表明车辆已经到达一条新路径" 38 "当前路径的索引，当该值发生变化是，表明车辆已经到达一条新路径" 37 "当前路径的索引，当该值发生变化是，表明车辆已经到达一条新路径" 36 "当前路径的索引，当该值发生变化是，表明车辆已经到达一条新路径" 35 "当前路径的索引，当该值发生变化是，表明车辆已经到达一条新路径" 34 "当前路径的索引，当该值发生变化是，表明车辆已经到达一条新路径" 33 "当前路径的索引，当该值发生变化是，表明车辆已经到达一条新路径" 32 "当前路径的索引，当该值发生变化是，表明车辆已经到达一条新路径" 31 "当前路径的索引，当该值发生变化是，表明车辆已经到达一条新路径" 30 "当前路径的索引，当该值发生变化是，表明车辆已经到达一条新路径" 29 "当前路径的索引，当该值发生变化是，表明车辆已经到达一条新路径" 28 "当前路径的索引，当该值发生变化是，表明车辆已经到达一条新路径" 27 "当前路径的索引，当该值发生变化是，表明车辆已经到达一条新路径" 26 "当前路径的索引，当该值发生变化是，表明车辆已经到达一条新路径" 25 "当前路径的索引，当该值发生变化是，表明车辆已经到达一条新路径" 24 "当前路径的索引，当该值发生变化是，表明车辆已经到达一条新路径" 23 "当前路径的索引，当该值发生变化是，表明车辆已经到达一条新路径" 22 "当前路径的索引，当该值发生变化是，表明车辆已经到达一条新路径" 21 "当前路径的索引，当该值发生变化是，表明车辆已经到达一条新路径" 20 "当前路径的索引，当该值发生变化是，表明车辆已经到达一条新路径" 19 "当前路径的索引，当该值发生变化是，表明车辆已经到达一条新路径" 18 "当前路径的索引，当该值发生变化是，表明车辆已经到达一条新路径" 17 "当前路径的索引，当该值发生变化是，表明车辆已经到达一条新路径" 16 "当前路径的索引，当该值发生变化是，表明车辆已经到达一条新路径" 15 "当前路径的索引，当该值发生变化是，表明车辆已经到达一条新路径" 14 "当前路径的索引，当该值发生变化是，表明车辆已经到达一条新路径" 13 "当前路径的索引，当该值发生变化是，表明车辆已经到达一条新路径" 12 "当前路径的索引，当该值发生变化是，表明车辆已经到达一条新路径" 11 "当前路径的索引，当该值发生变化是，表明车辆已经到达一条新路径" 10 "当前路径的索引，当该值发生变化是，表明车辆已经到达一条新路径" 9 "当前路径的索引，当该值发生变化是，表明车辆已经到达一条新路径" 8 "当前路径的索引，当该值发生变化是，表明车辆已经到达一条新路径" 7 "N/A" 6 "表示STUB消息用于传输交叉口主路径的航向变化和相对概率" 5 "表示存在不会被路径数据追加的十字路口分支" 4 "具有此路径索引的消息仅指当前车辆位置段" 3 "Av2HP 车辆定位子系统没有校准" 2 "位置不在道路上" 1 "位置不在数字化区域" 0 "未知";
VAL_ 2565928863 ADAS_ProfShort_CycCnt 3 "此消息类型的循环计数为3（下一次发送该消息类型的循环计数为0）" 2 "此消息类型的循环计数为2" 1 "此消息类型的循环计数为1" 0 "此消息类型的循环计数为0";
VAL_ 2565928863 ADAS_ProfShort_Offset 8191 "N/A" 510 "0~8190m，该消息与路径起点的距离对8191取余" 0 "0~8190m，该消息与路径起点的距离对8191取余";
VAL_ 2565928863 ADAS_ProfShort_MsgTyp 7 "N/A" 6 "META-DATA消息类型" 5 "PROFILE LONG消息类型" 4 "PROFILE SHORT消息类型" 3 "STUB消息类型" 2 "SEGMENT消息类型" 1 "POSITION消息类型" 0 "System specific消息类型";
VAL_ 2565929119 ProfileLong_Value 4294967295 "N/A";
VAL_ 2565929119 ADAS_ProfLong_Update 1 "表示此消息包含已传输的PROFILE LONG消息的更新信息" 0 "该消息不包含更新信息";
VAL_ 2565929119 ADAS_ProfLong_Retr 1 "表明该消息至少已经发送过一次" 0 "表明该消息是第一次发送";
VAL_ 2565929119 ADAS_ProfLong_CtrlPoint 1 "表明消息中的值是进行插值所需要的控制点" 0 "非控制点";
VAL_ 2565929119 ADAS_ProfLong_ProfType 31 "保留用于系统特定类型" 30 "保留用于系统特定类型" 29 "保留用于系统特定类型" 28 "保留用于系统特定类型" 27 "保留用于系统特定类型" 26 "保留用于系统特定类型" 25 "保留用于系统特定类型" 24 "保留用于系统特定类型" 23 "保留用于系统特定类型" 22 "保留用于系统特定类型" 21 "保留用于系统特定类型" 20 "保留用于系统特定类型" 19 "保留用于系统特定类型" 18 "保留用于系统特定类型" 17 "保留用于系统特定类型" 16 "保留用于系统特定类型" 15 "保留用于标准类型" 14 "保留用于标准类型" 13 "保留用于标准类型" 12 "保留用于标准类型" 11 "保留用于标准类型" 10 "扩展车道" 9 "卡车速度限制" 8 "交通标志" 7 "Link ID" 6 "控制点高度" 5 "控制点纬度" 4 "控制点经度" 3 "高度" 2 "维度" 1 "经度" 0 "N/A";
VAL_ 2565929119 ADAS_ProfLong_Pathidx 63 "当前路径的索引，当该值发生变化时，表明车辆已经到达一条新路径" 62 "当前路径的索引，当该值发生变化时，表明车辆已经到达一条新路径" 61 "当前路径的索引，当该值发生变化时，表明车辆已经到达一条新路径" 60 "当前路径的索引，当该值发生变化时，表明车辆已经到达一条新路径" 59 "当前路径的索引，当该值发生变化时，表明车辆已经到达一条新路径" 58 "当前路径的索引，当该值发生变化时，表明车辆已经到达一条新路径" 57 "当前路径的索引，当该值发生变化时，表明车辆已经到达一条新路径" 56 "当前路径的索引，当该值发生变化时，表明车辆已经到达一条新路径" 55 "当前路径的索引，当该值发生变化时，表明车辆已经到达一条新路径" 54 "当前路径的索引，当该值发生变化时，表明车辆已经到达一条新路径" 53 "当前路径的索引，当该值发生变化时，表明车辆已经到达一条新路径" 52 "当前路径的索引，当该值发生变化时，表明车辆已经到达一条新路径" 51 "当前路径的索引，当该值发生变化时，表明车辆已经到达一条新路径" 50 "当前路径的索引，当该值发生变化时，表明车辆已经到达一条新路径" 49 "当前路径的索引，当该值发生变化时，表明车辆已经到达一条新路径" 48 "当前路径的索引，当该值发生变化时，表明车辆已经到达一条新路径" 47 "当前路径的索引，当该值发生变化时，表明车辆已经到达一条新路径" 46 "当前路径的索引，当该值发生变化时，表明车辆已经到达一条新路径" 45 "当前路径的索引，当该值发生变化时，表明车辆已经到达一条新路径" 44 "当前路径的索引，当该值发生变化时，表明车辆已经到达一条新路径" 43 "当前路径的索引，当该值发生变化时，表明车辆已经到达一条新路径" 42 "当前路径的索引，当该值发生变化时，表明车辆已经到达一条新路径" 41 "当前路径的索引，当该值发生变化时，表明车辆已经到达一条新路径" 40 "当前路径的索引，当该值发生变化时，表明车辆已经到达一条新路径" 39 "当前路径的索引，当该值发生变化时，表明车辆已经到达一条新路径" 38 "当前路径的索引，当该值发生变化时，表明车辆已经到达一条新路径" 37 "当前路径的索引，当该值发生变化时，表明车辆已经到达一条新路径" 36 "当前路径的索引，当该值发生变化时，表明车辆已经到达一条新路径" 35 "当前路径的索引，当该值发生变化时，表明车辆已经到达一条新路径" 34 "当前路径的索引，当该值发生变化时，表明车辆已经到达一条新路径" 33 "当前路径的索引，当该值发生变化时，表明车辆已经到达一条新路径" 32 "当前路径的索引，当该值发生变化时，表明车辆已经到达一条新路径" 31 "当前路径的索引，当该值发生变化时，表明车辆已经到达一条新路径" 30 "当前路径的索引，当该值发生变化时，表明车辆已经到达一条新路径" 29 "当前路径的索引，当该值发生变化时，表明车辆已经到达一条新路径" 28 "当前路径的索引，当该值发生变化时，表明车辆已经到达一条新路径" 27 "当前路径的索引，当该值发生变化时，表明车辆已经到达一条新路径" 26 "当前路径的索引，当该值发生变化时，表明车辆已经到达一条新路径" 25 "当前路径的索引，当该值发生变化时，表明车辆已经到达一条新路径" 24 "当前路径的索引，当该值发生变化时，表明车辆已经到达一条新路径" 23 "当前路径的索引，当该值发生变化时，表明车辆已经到达一条新路径" 22 "当前路径的索引，当该值发生变化时，表明车辆已经到达一条新路径" 21 "当前路径的索引，当该值发生变化时，表明车辆已经到达一条新路径" 20 "当前路径的索引，当该值发生变化时，表明车辆已经到达一条新路径" 19 "当前路径的索引，当该值发生变化时，表明车辆已经到达一条新路径" 18 "当前路径的索引，当该值发生变化时，表明车辆已经到达一条新路径" 17 "当前路径的索引，当该值发生变化时，表明车辆已经到达一条新路径" 16 "当前路径的索引，当该值发生变化时，表明车辆已经到达一条新路径" 15 "当前路径的索引，当该值发生变化时，表明车辆已经到达一条新路径" 14 "当前路径的索引，当该值发生变化时，表明车辆已经到达一条新路径" 13 "当前路径的索引，当该值发生变化时，表明车辆已经到达一条新路径" 12 "当前路径的索引，当该值发生变化时，表明车辆已经到达一条新路径" 11 "当前路径的索引，当该值发生变化时，表明车辆已经到达一条新路径" 10 "当前路径的索引，当该值发生变化时，表明车辆已经到达一条新路径" 9 "当前路径的索引，当该值发生变化时，表明车辆已经到达一条新路径" 8 "当前路径的索引，当该值发生变化时，表明车辆已经到达一条新路径" 7 "N/A" 6 "表示STUB消息用于传输交叉口主路径的航向变化和相对概率" 5 "表示存在不会被路径数据追加的十字路口分支" 4 "具有此路径索引的消息仅指当前车辆位置段" 3 "Av2HP 车辆定位子系统没有校准" 2 "位置不在道路上" 1 "位置不在数字化区域" 0 "未知";
VAL_ 2565929119 ADAS_ProfLong_CycCnt 3 "此消息类型的循环计数为3（下一次发送该消息类型的循环计数为0）" 2 "此消息类型的循环计数为2" 1 "此消息类型的循环计数为1" 0 "此消息类型的循环计数为0";
VAL_ 2565929119 ADAS_ProfLong_Offset 8191 "N/A" 510 "0~8190m，该消息与路径起点的距离对8191取余" 0 "0~8190m，该消息与路径起点的距离对8191取余";
VAL_ 2565929119 ADAS_ProfLong_MsgType 7 "N/A" 6 "META-DATA消息类型" 5 "PROFILE LONG消息类型" 4 "PROFILE SHORT消息类型" 3 "STUB消息类型" 2 "SEGMENT消息类型" 1 "POSITION消息类型" 0 "System specific消息类型";
VAL_ 2565928607 ADAS_Seg_NumOfLaneDrvDir 7 "N/A." 6 "6车道或者更多." 5 "表示相应的车道数（0~5 lanes）" 4 "表示相应的车道数（0~5 lanes）" 3 "表示相应的车道数（0~5 lanes）" 2 "表示相应的车道数（0~5 lanes）" 1 "表示相应的车道数（0~5 lanes）" 0 "表示在错误方向上行驶的单向道路";
VAL_ 2565928607 ADAS_Seg_NumOfLaneOppDir 3 "无效值" 2 "表示两条或以上的车道线" 1 "表示一条车道线" 0 "表示单行车道";
VAL_ 2565928607 ADAS_Seg_DividedRoad 3 "N/A" 2 "未知" 1 "属于分道路/双车道." 0 "不属于分道路/双车道.";
VAL_ 2565928607 ADAS_Seg_EffSpdLmtType 7 "未知" 6 "明确的 - 雪" 5 "明确的 - 下雨" 4 "明确的 - 一天中的时段" 3 "明确的 - 按天" 2 "明确的 - 夜晚" 1 "明确 - 通过交通标志确定限速" 0 "隐含（例如，城市中的默认速度限制）";
VAL_ 2565928607 ADAS_Seg_EffSpdLmt 31 "无效" 30 "不限制" 29 "160  km/h [mph]" 28 "150  km/h [mph]" 27 "140  km/h [mph]" 26 "130  km/h [mph]" 25 "120  km/h [mph]" 24 "115  km/h [mph]" 23 "110  km/h [mph]" 22 "105 km/h [mph]" 21 "100 km/h [mph]" 20 "95 km/h [mph]" 19 "90  km/h [mph]" 18 "85  km/h [mph]" 17 "80  km/h [mph]" 16 "75  km/h [mph]" 15 "70  km/h [mph]" 14 "65  km/h [mph]" 13 "60  km/h [mph]" 12 "55  km/h [mph]" 11 "50  km/h [mph]" 10 "45  km/h [mph]" 9 "40  km/h [mph]" 8 "35  km/h [mph]" 7 "30  km/h [mph]" 6 "25  km/h [mph]" 5 "20  km/h [mph]" 4 "15  km/h [mph]" 3 "10  km/h [mph]" 2 "7  km/h [mph]" 1 "≤ 5  km/h [mph]" 0 "未知（包括变速标志控制）";
VAL_ 2565928607 ADAS_Seg_FormOfWay 15 "N/A" 14 "步行区" 13 "进入或退出服务区" 12 "进入或离开停车场" 11 "服务区道路或临街道路" 10 "滑行道/坡道（不在高速公路或受控通道上）" 9 "高速公路或受控通道上的滑行道/坡道" 8 "平行道路（作为支路/坡道的特殊类型）" 7 "预留" 6 "预留" 5 "交通广场/特殊交通图" 4 "环形路段" 3 "单车道（默认）" 2 "多车道或数字化道路" 1 "高速公路或受控道路，不是支路/坡道" 0 "未知";
VAL_ 2565928607 ADAS_Seg_CmplxInsct 3 "N/A" 2 "未知" 1 "属于复杂交叉路口." 0 "不属于复杂交叉路口.";
VAL_ 2565928607 ADAS_Seg_PartOfCalcRoute 3 "N/A" 2 "未知" 1 "属于计算的路径" 0 "不属于计算的路径";
VAL_ 2565928607 ADAS_Seg_FuncRoadClass 7 "N/A" 0 "未知";
VAL_ 2565928607 ADAS_Seg_RelProbb 31 "N/A" 30 "0~100%，该路段相对于同一路径上的前一路段的相对概率" 29 "0~100%，该路段相对于同一路径上的前一路段的相对概率" 28 "0~100%，该路段相对于同一路径上的前一路段的相对概率" 27 "0~100%，该路段相对于同一路径上的前一路段的相对概率" 26 "0~100%，该路段相对于同一路径上的前一路段的相对概率" 25 "0~100%，该路段相对于同一路径上的前一路段的相对概率" 24 "0~100%，该路段相对于同一路径上的前一路段的相对概率" 23 "0~100%，该路段相对于同一路径上的前一路段的相对概率" 22 "0~100%，该路段相对于同一路径上的前一路段的相对概率" 21 "0~100%，该路段相对于同一路径上的前一路段的相对概率" 20 "0~100%，该路段相对于同一路径上的前一路段的相对概率" 19 "0~100%，该路段相对于同一路径上的前一路段的相对概率" 18 "0~100%，该路段相对于同一路径上的前一路段的相对概率" 17 "0~100%，该路段相对于同一路径上的前一路段的相对概率" 16 "0~100%，该路段相对于同一路径上的前一路段的相对概率" 15 "0~100%，该路段相对于同一路径上的前一路段的相对概率" 14 "0~100%，该路段相对于同一路径上的前一路段的相对概率" 13 "0~100%，该路段相对于同一路径上的前一路段的相对概率" 12 "0~100%，该路段相对于同一路径上的前一路段的相对概率" 11 "0~100%，该路段相对于同一路径上的前一路段的相对概率" 10 "0~100%，该路段相对于同一路径上的前一路段的相对概率" 9 "0~100%，该路段相对于同一路径上的前一路段的相对概率" 8 "0~100%，该路段相对于同一路径上的前一路段的相对概率" 7 "0~100%，该路段相对于同一路径上的前一路段的相对概率" 6 "0~100%，该路段相对于同一路径上的前一路段的相对概率" 5 "0~100%，该路段相对于同一路径上的前一路段的相对概率" 4 "0~100%，该路段相对于同一路径上的前一路段的相对概率" 3 "0~100%，该路段相对于同一路径上的前一路段的相对概率" 2 "0~100%，该路段相对于同一路径上的前一路段的相对概率" 1 "0~100%，该路段相对于同一路径上的前一路段的相对概率" 0 "0~100%，该路段相对于同一路径上的前一路段的相对概率";
VAL_ 2565928607 ADAS_Seg_Update 1 "表示此消息包含已传输的Segment消息的更新信息" 0 "该消息不包含更新信息";
VAL_ 2565928607 ADAS_Seg_Retr 1 "表明该消息至少已经发送过一次" 0 "表明该消息是第一次发送";
VAL_ 2565928607 ADAS_Seg_BuildUpArea 3 "N/A" 2 "未知" 1 "属于建成区" 0 "不属于建成区";
VAL_ 2565928607 ADAS_Seg_Bridge 3 "N/A" 2 "未知" 1 "属于桥梁" 0 "不属于桥梁";
VAL_ 2565928607 ADAS_Seg_Tunnel 3 "N/A" 2 "未知" 1 "属于隧道" 0 "不属于隧道";
VAL_ 2565928607 ADAS_Seg_Pathidx 63 "当前路径的索引，当该值发生变化时，表明车辆已经到达一条新路径" 62 "当前路径的索引，当该值发生变化时，表明车辆已经到达一条新路径" 61 "当前路径的索引，当该值发生变化时，表明车辆已经到达一条新路径" 60 "当前路径的索引，当该值发生变化时，表明车辆已经到达一条新路径" 59 "当前路径的索引，当该值发生变化时，表明车辆已经到达一条新路径" 58 "当前路径的索引，当该值发生变化时，表明车辆已经到达一条新路径" 57 "当前路径的索引，当该值发生变化时，表明车辆已经到达一条新路径" 56 "当前路径的索引，当该值发生变化时，表明车辆已经到达一条新路径" 55 "当前路径的索引，当该值发生变化时，表明车辆已经到达一条新路径" 54 "当前路径的索引，当该值发生变化时，表明车辆已经到达一条新路径" 53 "当前路径的索引，当该值发生变化时，表明车辆已经到达一条新路径" 52 "当前路径的索引，当该值发生变化时，表明车辆已经到达一条新路径" 51 "当前路径的索引，当该值发生变化时，表明车辆已经到达一条新路径" 50 "当前路径的索引，当该值发生变化时，表明车辆已经到达一条新路径" 49 "当前路径的索引，当该值发生变化时，表明车辆已经到达一条新路径" 48 "当前路径的索引，当该值发生变化时，表明车辆已经到达一条新路径" 47 "当前路径的索引，当该值发生变化时，表明车辆已经到达一条新路径" 46 "当前路径的索引，当该值发生变化时，表明车辆已经到达一条新路径" 45 "当前路径的索引，当该值发生变化时，表明车辆已经到达一条新路径" 44 "当前路径的索引，当该值发生变化时，表明车辆已经到达一条新路径" 43 "当前路径的索引，当该值发生变化时，表明车辆已经到达一条新路径" 42 "当前路径的索引，当该值发生变化时，表明车辆已经到达一条新路径" 41 "当前路径的索引，当该值发生变化时，表明车辆已经到达一条新路径" 40 "当前路径的索引，当该值发生变化时，表明车辆已经到达一条新路径" 39 "当前路径的索引，当该值发生变化时，表明车辆已经到达一条新路径" 38 "当前路径的索引，当该值发生变化时，表明车辆已经到达一条新路径" 37 "当前路径的索引，当该值发生变化时，表明车辆已经到达一条新路径" 36 "当前路径的索引，当该值发生变化时，表明车辆已经到达一条新路径" 35 "当前路径的索引，当该值发生变化时，表明车辆已经到达一条新路径" 34 "当前路径的索引，当该值发生变化时，表明车辆已经到达一条新路径" 33 "当前路径的索引，当该值发生变化时，表明车辆已经到达一条新路径" 32 "当前路径的索引，当该值发生变化时，表明车辆已经到达一条新路径" 31 "当前路径的索引，当该值发生变化时，表明车辆已经到达一条新路径" 30 "当前路径的索引，当该值发生变化时，表明车辆已经到达一条新路径" 29 "当前路径的索引，当该值发生变化时，表明车辆已经到达一条新路径" 28 "当前路径的索引，当该值发生变化时，表明车辆已经到达一条新路径" 27 "当前路径的索引，当该值发生变化时，表明车辆已经到达一条新路径" 26 "当前路径的索引，当该值发生变化时，表明车辆已经到达一条新路径" 25 "当前路径的索引，当该值发生变化时，表明车辆已经到达一条新路径" 24 "当前路径的索引，当该值发生变化时，表明车辆已经到达一条新路径" 23 "当前路径的索引，当该值发生变化时，表明车辆已经到达一条新路径" 22 "当前路径的索引，当该值发生变化时，表明车辆已经到达一条新路径" 21 "当前路径的索引，当该值发生变化时，表明车辆已经到达一条新路径" 20 "当前路径的索引，当该值发生变化时，表明车辆已经到达一条新路径" 19 "当前路径的索引，当该值发生变化时，表明车辆已经到达一条新路径" 18 "当前路径的索引，当该值发生变化时，表明车辆已经到达一条新路径" 17 "当前路径的索引，当该值发生变化时，表明车辆已经到达一条新路径" 16 "当前路径的索引，当该值发生变化时，表明车辆已经到达一条新路径" 15 "当前路径的索引，当该值发生变化时，表明车辆已经到达一条新路径" 14 "当前路径的索引，当该值发生变化时，表明车辆已经到达一条新路径" 13 "当前路径的索引，当该值发生变化时，表明车辆已经到达一条新路径" 12 "当前路径的索引，当该值发生变化时，表明车辆已经到达一条新路径" 11 "当前路径的索引，当该值发生变化时，表明车辆已经到达一条新路径" 10 "当前路径的索引，当该值发生变化时，表明车辆已经到达一条新路径" 9 "当前路径的索引，当该值发生变化时，表明车辆已经到达一条新路径" 8 "当前路径的索引，当该值发生变化时，表明车辆已经到达一条新路径" 7 "N/A" 6 "表示STUB消息用于传输交叉口主路径的航向变化和相对概率" 5 "表示存在不会被路径数据追加的十字路口分支" 4 "具有此路径索引的消息仅指当前车辆位置段" 3 "Av2HP 车辆定位子系统没有校准" 2 "位置不在道路上" 1 "位置不在数字化区域" 0 "未知";
VAL_ 2565928607 ADAS_Seg_CycCnt 3 "此消息类型的循环计数为3（下一次发送该消息类型的循环计数为0）" 2 "此消息类型的循环计数为2" 1 "此消息类型的循环计数为1" 0 "此消息类型的循环计数为0";
VAL_ 2565928607 ADAS_Seg_Offset 8191 "N/A" 510 "0~8190m，该segment路段与路径起点的距离对8191取余" 0 "0~8190m，该segment路段与路径起点的距离对8191取余";
VAL_ 2565928607 ADAS_Seg_MsgType 7 "N/A" 6 "META-DATA消息类型" 5 "PROFILE LONG消息类型" 4 "PROFILE SHORT消息类型" 3 "STUB消息类型" 2 "SEGMENT消息类型" 1 "POSITION消息类型" 0 "System specific消息类型";
VAL_ 2633037471 ADAS_Meta_ProtVer_Minor 15 "次要协议版本" 14 "次要协议版本" 13 "次要协议版本" 12 "次要协议版本" 11 "次要协议版本" 10 "次要协议版本" 9 "次要协议版本" 8 "次要协议版本" 7 "次要协议版本" 6 "次要协议版本" 5 "次要协议版本" 4 "次要协议版本" 3 "次要协议版本" 2 "次要协议版本" 1 "次要协议版本" 0 "次要协议版本";
VAL_ 2633037471 ADAS_Meta_SpdUnits 1 "每小时英里数 (mph)." 0 "公里/小时 (km/h).";
VAL_ 2633037471 ADAS_Meta_MapVerYear 63 "N/A" 62 "代表当前年份减去2000再对63求余(Year-2000 mode 63)" 61 "代表当前年份减去2000再对63求余(Year-2000 mode 63)" 60 "代表当前年份减去2000再对63求余(Year-2000 mode 63)" 59 "代表当前年份减去2000再对63求余(Year-2000 mode 63)" 58 "代表当前年份减去2000再对63求余(Year-2000 mode 63)" 57 "代表当前年份减去2000再对63求余(Year-2000 mode 63)" 56 "代表当前年份减去2000再对63求余(Year-2000 mode 63)" 55 "代表当前年份减去2000再对63求余(Year-2000 mode 63)" 54 "代表当前年份减去2000再对63求余(Year-2000 mode 63)" 53 "代表当前年份减去2000再对63求余(Year-2000 mode 63)" 52 "代表当前年份减去2000再对63求余(Year-2000 mode 63)" 51 "代表当前年份减去2000再对63求余(Year-2000 mode 63)" 50 "代表当前年份减去2000再对63求余(Year-2000 mode 63)" 49 "代表当前年份减去2000再对63求余(Year-2000 mode 63)" 48 "代表当前年份减去2000再对63求余(Year-2000 mode 63)" 47 "代表当前年份减去2000再对63求余(Year-2000 mode 63)" 46 "代表当前年份减去2000再对63求余(Year-2000 mode 63)" 45 "代表当前年份减去2000再对63求余(Year-2000 mode 63)" 44 "代表当前年份减去2000再对63求余(Year-2000 mode 63)" 43 "代表当前年份减去2000再对63求余(Year-2000 mode 63)" 42 "代表当前年份减去2000再对63求余(Year-2000 mode 63)" 41 "代表当前年份减去2000再对63求余(Year-2000 mode 63)" 40 "代表当前年份减去2000再对63求余(Year-2000 mode 63)" 39 "代表当前年份减去2000再对63求余(Year-2000 mode 63)" 38 "代表当前年份减去2000再对63求余(Year-2000 mode 63)" 37 "代表当前年份减去2000再对63求余(Year-2000 mode 63)" 36 "代表当前年份减去2000再对63求余(Year-2000 mode 63)" 35 "代表当前年份减去2000再对63求余(Year-2000 mode 63)" 34 "代表当前年份减去2000再对63求余(Year-2000 mode 63)" 33 "代表当前年份减去2000再对63求余(Year-2000 mode 63)" 32 "代表当前年份减去2000再对63求余(Year-2000 mode 63)" 31 "代表当前年份减去2000再对63求余(Year-2000 mode 63)" 30 "代表当前年份减去2000再对63求余(Year-2000 mode 63)" 29 "代表当前年份减去2000再对63求余(Year-2000 mode 63)" 28 "代表当前年份减去2000再对63求余(Year-2000 mode 63)" 27 "代表当前年份减去2000再对63求余(Year-2000 mode 63)" 26 "代表当前年份减去2000再对63求余(Year-2000 mode 63)" 25 "代表当前年份减去2000再对63求余(Year-2000 mode 63)" 24 "代表当前年份减去2000再对63求余(Year-2000 mode 63)" 23 "代表当前年份减去2000再对63求余(Year-2000 mode 63)" 22 "代表当前年份减去2000再对63求余(Year-2000 mode 63)" 21 "代表当前年份减去2000再对63求余(Year-2000 mode 63)" 20 "代表当前年份减去2000再对63求余(Year-2000 mode 63)" 19 "代表当前年份减去2000再对63求余(Year-2000 mode 63)" 18 "代表当前年份减去2000再对63求余(Year-2000 mode 63)" 17 "代表当前年份减去2000再对63求余(Year-2000 mode 63)" 16 "代表当前年份减去2000再对63求余(Year-2000 mode 63)" 15 "代表当前年份减去2000再对63求余(Year-2000 mode 63)" 14 "代表当前年份减去2000再对63求余(Year-2000 mode 63)" 13 "代表当前年份减去2000再对63求余(Year-2000 mode 63)" 12 "代表当前年份减去2000再对63求余(Year-2000 mode 63)" 11 "代表当前年份减去2000再对63求余(Year-2000 mode 63)" 10 "代表当前年份减去2000再对63求余(Year-2000 mode 63)" 9 "代表当前年份减去2000再对63求余(Year-2000 mode 63)" 8 "代表当前年份减去2000再对63求余(Year-2000 mode 63)" 7 "代表当前年份减去2000再对63求余(Year-2000 mode 63)" 6 "代表当前年份减去2000再对63求余(Year-2000 mode 63)" 5 "代表当前年份减去2000再对63求余(Year-2000 mode 63)" 4 "代表当前年份减去2000再对63求余(Year-2000 mode 63)" 3 "代表当前年份减去2000再对63求余(Year-2000 mode 63)" 2 "代表当前年份减去2000再对63求余(Year-2000 mode 63)" 1 "代表当前年份减去2000再对63求余(Year-2000 mode 63)" 0 "代表当前年份减去2000再对63求余(Year-2000 mode 63)";
VAL_ 2633037471 ADAS_Meta_MapVerQtr 3 "一年当中的第四季度" 2 "一年当中的第三季度" 1 "一年当中的第二季度" 0 "一年当中的第一季度";
VAL_ 2633037471 ADAS_Meta_RegionCode 32766 "区域代码" 0 "区域代码";
VAL_ 2633037471 ADAS_Meta_DrvSide 1 "右侧驾驶" 0 "左侧驾驶";
VAL_ 2633037471 ADAS_Meta_HWVer 511 "提供商的硬件和/或软件版本（取决于公司特定的编号方案）" 1 "提供商的硬件和/或软件版本（取决于公司特定的编号方案）" 0 "未知";
VAL_ 2633037471 ADAS_Meta_ProtVer_MinorSub 7 "次要协议子版本" 6 "次要协议子版本" 5 "次要协议子版本" 4 "次要协议子版本" 3 "次要协议子版本" 2 "次要协议子版本" 1 "次要协议子版本" 0 "次要协议子版本";
VAL_ 2633037471 ADAS_Meta_ProtVer_Major 3 "v3主版本" 2 "v2主版本" 0 "v2主版本";
VAL_ 2633037471 ADAS_Meta_CycCnt 3 "此消息类型的循环计数为3（下一次发送该消息类型的循环计数为0）" 2 "此消息类型的循环计数为2" 1 "此消息类型的循环计数为1" 0 "此消息类型的循环计数为0";
VAL_ 2633037471 ADAS_Meta_CountryCode 1023 "国家代码，ISO 3166-1数字指定的有效值" 0 "国家代码，ISO 3166-1数字指定的有效值";
VAL_ 2633037471 ADAS_Meta_MapProvider 7 "N/A." 6 "其他供应商" 5 "四维图新供应商" 4 "IPC供应商" 3 "Zenrin供应商" 2 "TomTom (Tele Atlas) 提供商" 1 "诺基亚HERE（NAVTEQ）提供商" 0 "未知";
VAL_ 2633037471 ADAS_Meta_MsgType 7 "N/A" 6 "META-DATA消息类型" 5 "PROFILE LONG消息类型" 4 "PROFILE SHORT消息类型" 3 "STUB消息类型" 2 "SEGMENT消息类型" 1 "POSITION消息类型" 0 "System specific消息类型";
VAL_ 2633037727 ADASProfileShortSlope 1023 "N/A";
VAL_ 2566869400 ADB_Left_Switch_State 1 "on" 0 "off";
VAL_ 2566869400 ADB_Left_MAX_State 1 "on" 0 "off";
VAL_ 2566869400 ADB_Left_Bent_State 1 "on" 0 "off";
VAL_ 2566869400 ADB_Left_Lamp_Fault 1 "故障" 0 "正常";
VAL_ 2566869400 ADB_Left_Power_Fault 1 "故障" 0 "正常";
VAL_ 2566869400 ADB_Left_CAN_Fault 1 "故障" 0 "正常";
VAL_ 2566869400 ADB_Left_HiBeamSt 1 "on" 0 "off";
VAL_ 2566869400 ADB_Left_HbWngSt 1 "High beam work fail" 0 "High beam work normal";
VAL_ 2566869400 ADB_L_SwitchSet_Sts 2 "Enable" 1 "Disable" 0 "No Req/Initial";
VAL_ 2566869657 ADB_Right_Switch_State 1 "on" 0 "off";
VAL_ 2566869657 ADB_Right_MAX_State 1 "on" 0 "off";
VAL_ 2566869657 ADB_Right_Bent_State 1 "on" 0 "off";
VAL_ 2566869657 ADB_Right_Lamp_Fault 1 "故障" 0 "正常";
VAL_ 2566869657 ADB_Right_Power_Fault 1 "故障" 0 "正常";
VAL_ 2566869657 ADB_Right_CAN_Fault 1 "故障" 0 "正常";
VAL_ 2566869657 ADB_Right_HiBeamSt 1 "on" 0 "off";
VAL_ 2566869657 ADB_Right_HbWngSt 1 "High beam work fail" 0 "High beam work normal";
VAL_ 2566869657 ADB_R_SwitchSet_Sts 2 "Enable" 1 "Disable" 0 "No Req/Initial";
VAL_ 2566893400 EAC1_CmpsrSts 3 "Fault（压缩机故障）" 1 "On" 0 "Off";
VAL_ 2566893400 EAC1_UndrVFlt 1 "Failure" 0 "Normal";
VAL_ 2566893400 EAC1_OvrCrntFlt 1 "Failure" 0 "Normal";
VAL_ 2566893400 EAC1_OvrCrntFey 1 "Failure" 0 "Normal";
VAL_ 2566893400 EAC1_OvrTempFlt 1 "Failure" 0 "Normal";
VAL_ 2566893400 EAC1_OvrTmpFey 1 "Failure" 0 "Normal";
VAL_ 2566893400 EAC1_CompIntVolFlt 1 "Failure" 0 "Normal";
VAL_ 2566893400 EAC1_LstCommWithAC 1 "Failure" 0 "Normal";
VAL_ 2566893400 EAS1_HVIL_Sts 1 "Failure" 0 "Normal";
VAL_ 2566893400 EAC1_OvrVolFlt 1 "Failure" 0 "Normal";
